VERSION ""

NS_ :

BS_:

BU_: L_DHRR_FD L_UWB_BLE_MST_FD L_UWB_RR_FD L_UWB_BLE_SLV_FD L_UWB_FR_FD L_ROA_FR_FD L_ROA_FD L_DHRL_FD L_UWB_TRNK_FD L_UWB_FRNK_FD L_EDT_FD L_UWB_FL_FD GW_BDC_FD L_UWB_RL_FD L_SAL_FD L_WPC_FD L_TPMS_FD L_DHL_FD L_DHR_FD

BO_ 2214592722 L_UWB_FR_FD_03_00ms: 32 L_UWB_FR_FD
 SG_ L_UWB_FR_FD_Crc3Val : 0|16@1+ (1,0) [0|0] "0" Vector__XXX
 SG_ L_UWB_FR_FD_AlvCnt3Val : 16|8@1+ (1,0) [0|0] "0" Vector__XXX
 SG_ UWB_FR_Ranging_Enc_Result2 : 216|40@1+ (1,0) [0|0] ""  GW_BDC_FD,L_UWB_BLE_MST_FD
 SG_ UWB_FR_Ranging_Enc_Result : 24|192@1+ (1,0) [0|0] ""  GW_BDC_FD,L_UWB_BLE_MST_FD

BO_ 2214592714 L_UWB_BLE_MST_FD_22_00ms: 32 L_UWB_BLE_MST_FD
 SG_ L_UWB_BLE_MST_FD_Crc22Val : 0|16@1+ (1,0) [0|0] "0" Vector__XXX
 SG_ L_UWB_BLE_MST_FD_AlvCnt22Val : 16|8@1+ (1,0) [0|0] "0" Vector__XXX
 SG_ MST_DisconnectDKID : 24|8@1+ (1,0) [0|0] ""  L_EDT_FD
 SG_ MST_DisconnectReason : 32|8@1+ (1,0) [0|0] ""  L_EDT_FD
 SG_ MST_BLE_ErrorReturn : 40|8@1+ (1,0) [0|0] ""  L_EDT_FD,L_UWB_BLE_SLV_FD

BO_ 2214592719 L_UWB_FL_FD_Dvp_01_00ms: 32 L_UWB_FL_FD
 SG_ UWB_FL_Dvp_Data : 0|255@1+ (1,0) [0|0] ""  L_EDT_FD

BO_ 2521143553 L_UWB_BLE_SLV_FD_13_00ms: 32 L_UWB_BLE_SLV_FD
 SG_ L_UWB_BLE_SLV_FD_Crc13Val : 0|16@1+ (1,0) [0|0] "" Vector__XXX
 SG_ L_UWB_BLE_SLV_FD_AlvCnt13Val : 16|8@1+ (1,0) [0|0] "" Vector__XXX
 SG_ SLV_SWID_4_IVD_1 : 24|232@1+ (1,0) [0|0] ""  L_UWB_BLE_MST_FD

BO_ 2214592705 L_UWB_FL_FD_02_00ms: 16 L_UWB_FL_FD
 SG_ L_UWB_FL_FD_Crc2Val : 0|16@1+ (1,0) [0|0] "0" Vector__XXX
 SG_ L_UWB_FL_FD_AlvCnt2Val : 16|8@1+ (1,0) [0|0] "0" Vector__XXX
 SG_ UWB_FL_FOB_RSD_Enc_Result : 24|64@1+ (1,0) [0|0] ""  GW_BDC_FD

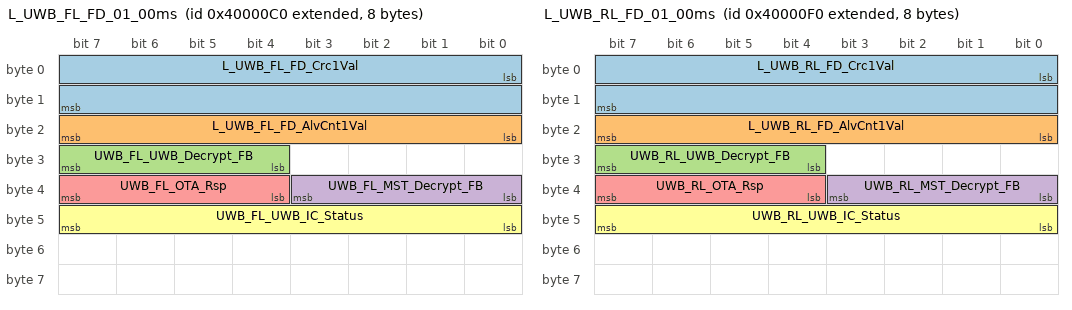
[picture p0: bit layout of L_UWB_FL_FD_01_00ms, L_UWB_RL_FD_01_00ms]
BO_ 2214592704 L_UWB_FL_FD_01_00ms: 8 L_UWB_FL_FD
 SG_ L_UWB_FL_FD_Crc1Val : 0|16@1+ (1,0) [0|0] "0" Vector__XXX
 SG_ L_UWB_FL_FD_AlvCnt1Val : 16|8@1+ (1,0) [0|0] "0" Vector__XXX
 SG_ UWB_FL_UWB_Decrypt_FB : 28|4@1+ (1,0) [0|0] ""  GW_BDC_FD
 SG_ UWB_FL_MST_Decrypt_FB : 32|4@1+ (1,0) [0|0] ""  L_UWB_BLE_MST_FD
 SG_ UWB_FL_OTA_Rsp : 36|4@1+ (1,0) [0|0] ""  L_UWB_BLE_MST_FD
 SG_ UWB_FL_UWB_IC_Status : 40|8@1+ (1,0) [0|0] ""  L_EDT_FD

BO_ 2214592706 L_UWB_FL_FD_03_00ms: 32 L_UWB_FL_FD
 SG_ L_UWB_FL_FD_Crc3Val : 0|16@1+ (1,0) [0|0] "0" Vector__XXX
 SG_ L_UWB_FL_FD_AlvCnt3Val : 16|8@1+ (1,0) [0|0] "0" Vector__XXX
 SG_ UWB_FL_Ranging_Enc_Result2 : 216|40@1+ (1,0) [0|0] ""  GW_BDC_FD,L_UWB_BLE_MST_FD
 SG_ UWB_FL_Ranging_Enc_Result : 24|192@1+ (1,0) [0|0] ""  GW_BDC_FD,L_UWB_BLE_MST_FD

BO_ 2525339649 L_UWB_FL_FD_04_00ms: 32 L_UWB_FL_FD
 SG_ L_UWB_FL_FD_Crc4Val : 0|16@1+ (1,0) [0|0] "" Vector__XXX
 SG_ L_UWB_FL_FD_AlvCnt4Val : 16|8@1+ (1,0) [0|0] "" Vector__XXX
 SG_ FL_SWID_3_IVD_1 : 24|232@1+ (1,0) [0|0] ""  L_UWB_BLE_MST_FD

BO_ 2214592767 L_UWB_RL_FD_Dvp_01_00ms: 32 L_UWB_RL_FD
 SG_ UWB_RL_Dvp_Data : 0|255@1+ (1,0) [0|0] ""  L_EDT_FD

BO_ 2214592754 L_UWB_RL_FD_03_00ms: 32 L_UWB_RL_FD
 SG_ L_UWB_RL_FD_Crc3Val : 0|16@1+ (1,0) [0|0] "0" Vector__XXX
 SG_ L_UWB_RL_FD_AlvCnt3Val : 16|8@1+ (1,0) [0|0] "0" Vector__XXX
 SG_ UWB_RL_Ranging_Enc_Result2 : 216|40@1+ (1,0) [0|0] ""  GW_BDC_FD,L_UWB_BLE_MST_FD
 SG_ UWB_RL_Ranging_Enc_Result : 24|192@1+ (1,0) [0|0] ""  GW_BDC_FD,L_UWB_BLE_MST_FD

BO_ 2214592752 L_UWB_RL_FD_01_00ms: 8 L_UWB_RL_FD
 SG_ L_UWB_RL_FD_Crc1Val : 0|16@1+ (1,0) [0|0] "0" Vector__XXX
 SG_ L_UWB_RL_FD_AlvCnt1Val : 16|8@1+ (1,0) [0|0] "0" Vector__XXX
 SG_ UWB_RL_UWB_Decrypt_FB : 28|4@1+ (1,0) [0|0] ""  GW_BDC_FD
 SG_ UWB_RL_MST_Decrypt_FB : 32|4@1+ (1,0) [0|0] ""  L_UWB_BLE_MST_FD
 SG_ UWB_RL_OTA_Rsp : 36|4@1+ (1,0) [0|0] ""  L_UWB_BLE_MST_FD
 SG_ UWB_RL_UWB_IC_Status : 40|8@1+ (1,0) [0|0] ""  L_EDT_FD

BO_ 2214592753 L_UWB_RL_FD_02_00ms: 16 L_UWB_RL_FD
 SG_ L_UWB_RL_FD_Crc2Val : 0|16@1+ (1,0) [0|0] "0" Vector__XXX
 SG_ L_UWB_RL_FD_AlvCnt2Val : 16|8@1+ (1,0) [0|0] "0" Vector__XXX
 SG_ UWB_RL_FOB_RSD_Enc_Result : 24|64@1+ (1,0) [0|0] ""  GW_BDC_FD

BO_ 187 BDC_FD_01_00ms: 32 GW_BDC_FD
 SG_ BDC_FD_Crc1Val : 0|16@1+ (1,0) [0|0] "" Vector__XXX
 SG_ Ast_AutoRlxWrngDis_Copy_0 : 101|3@1+ (1,0) [0|0] "" Vector__XXX
 SG_ RLPSU_FailState_PopUp_Copy_0 : 104|4@1+ (1,0) [0|0] "" Vector__XXX
 SG_ RRPSU_FailState_PopUp_Copy_0 : 108|4@1+ (1,0) [0|0] "" Vector__XXX
 SG_ Pseat_AllSeatIMSMemoryDelReq : 112|2@1+ (1,0) [0|0] "" Vector__XXX
 SG_ PSeat_RLVIPRelaxionMemoryDelReq : 114|3@1+ (1,0) [0|0] "" Vector__XXX
 SG_ PSeat_RRVIPRelaxionMemoryDelReq : 117|3@1+ (1,0) [0|0] "" Vector__XXX
 SG_ Lamp_FrunkLampCmd : 120|2@1+ (1,0) [0|0] "" Vector__XXX
 SG_ Lamp_DrvCourtesyLampCmd : 122|2@1+ (1,0) [0|0] "" Vector__XXX
 SG_ Lamp_AstCourtesyLampCmd : 124|2@1+ (1,0) [0|0] "" Vector__XXX
 SG_ Lamp_RLCourtesyLampCmd : 126|2@1+ (1,0) [0|0] "" Vector__XXX
 SG_ Lamp_RRCourtesyLampCmd : 128|2@1+ (1,0) [0|0] "" Vector__XXX
 SG_ Lamp_RoomLampCmd : 130|3@1+ (1,0) [0|0] "" Vector__XXX
 SG_ Lamp_FootLampCmd : 133|4@1+ (1,0) [0|0] ""  L_SAL_FD
 SG_ PFSU_3LAMPBzrReq_Copy_0 : 137|2@1+ (1,0) [0|0] "" Vector__XXX
 SG_ PFSU_3RAMPBzrReq_Copy_0 : 139|2@1+ (1,0) [0|0] "" Vector__XXX
 SG_ Drv_AutoRlxWrngDis_2_Copy_0 : 141|3@1+ (1,0) [0|0] "" Vector__XXX
 SG_ Ast_AutoRlxWrngDis_2_Copy_0 : 144|3@1+ (1,0) [0|0] "" Vector__XXX
 SG_ RLPSU_Folding_State_Popup_EC_Cop : 147|3@1+ (1,0) [0|0] "" Vector__XXX
 SG_ RRPSU_Folding_State_Popup_EC_Cop : 150|3@1+ (1,0) [0|0] "" Vector__XXX
 SG_ C_LH_Folding_State_PopUp_Copy_0 : 153|3@1+ (1,0) [0|0] "" Vector__XXX
 SG_ C_RH_Folding_State_PopUp_Copy_0 : 156|3@1+ (1,0) [0|0] "" Vector__XXX
 SG_ C_RH_Folding_State_PopUp_2_Copy_ : 159|3@1+ (1,0) [0|0] "" Vector__XXX
 SG_ BDC_FD_AlvCnt1Val : 16|8@1+ (1,0) [0|0] "" Vector__XXX
 SG_ C_LH_Folding_State_PopUp_2_Copy_ : 162|3@1+ (1,0) [0|0] "" Vector__XXX
 SG_ Swivel_UtilModeSetReq : 165|2@1+ (1,0) [0|0] "" Vector__XXX
 SG_ PSeat_SecondRLTiltWalkInDisReq : 167|2@1+ (1,0) [0|0] "" Vector__XXX
 SG_ PSeat_SecondRRTiltWalkInDisReq : 169|2@1+ (1,0) [0|0] "" Vector__XXX
 SG_ PSeat_DrvLegrestOSDDisReq : 171|3@1+ (1,0) [0|0] "" Vector__XXX
 SG_ PHEV_FuelDrWakeupSta_Copy_0 : 174|2@1+ (1,0) [0|0] "" Vector__XXX
 SG_ MoodLamp_MLSingleBrghtModCmd : 184|3@1+ (1,0) [0|0] "" Vector__XXX
 SG_ MoodLamp_SingleBrghtVal : 187|4@1+ (1,0) [0|0] "" Vector__XXX
 SG_ PSeat_AstReturnMemoryCmd : 192|2@1+ (1,0) [0|0] "" Vector__XXX
 SG_ Swivel_AVNPlayConfirmReq : 194|2@1+ (1,0) [0|0] "" Vector__XXX
 SG_ Swivel_AVNDrvPopUpDisReq : 196|4@1+ (1,0) [0|0] "" Vector__XXX
 SG_ Swivel_AVNAstPopUpDisReq : 200|4@1+ (1,0) [0|0] "" Vector__XXX
 SG_ Swivel_AVNDrvOSDDisReq : 204|4@1+ (1,0) [0|0] "" Vector__XXX
 SG_ Swivel_AVNAstOSDDisReq : 208|4@1+ (1,0) [0|0] "" Vector__XXX
 SG_ Swivel_CTSPlayConfirmReq : 212|2@1+ (1,0) [0|0] "" Vector__XXX
 SG_ Swivel_CTSDrvPopUpDisReq : 214|4@1+ (1,0) [0|0] "" Vector__XXX
 SG_ Swivel_CTSAstPopUpDisReq : 218|4@1+ (1,0) [0|0] "" Vector__XXX
 SG_ Swivel_CTSDrvOSDDisReq : 222|4@1+ (1,0) [0|0] "" Vector__XXX
 SG_ Swivel_CTSAstOSDDisReq : 226|4@1+ (1,0) [0|0] "" Vector__XXX
 SG_ PSeat_AllFoldUnfoldOSDDisReq : 230|4@1+ (1,0) [0|0] "" Vector__XXX
 SG_ DrvIMS_MemorySetEnaSta_Copy_0 : 234|2@1+ (1,0) [0|0] "" Vector__XXX
 SG_ C_LH_Folding_State_PopUp_CTS : 236|3@1+ (1,0) [0|0] "" Vector__XXX
 SG_ C_LH_Folding_State_PopUp_2_CTS : 239|3@1+ (1,0) [0|0] "" Vector__XXX
 SG_ PHEV_FuelDrReleaseSwSta_Copy_0 : 24|2@1+ (1,0) [0|0] "" Vector__XXX
 SG_ C_RH_Folding_State_PopUp_CTS : 242|3@1+ (1,0) [0|0] "" Vector__XXX
 SG_ C_RH_Folding_State_PopUp_2_CTS : 245|3@1+ (1,0) [0|0] "" Vector__XXX
 SG_ PSeat_AllFoldUnfoldOSDDisReq_CTS : 248|4@1+ (1,0) [0|0] "" Vector__XXX
 SG_ StrWhlWrmr_MKBDBpReq_Copy_0 : 26|2@1+ (1,0) [0|0] "" Vector__XXX
 SG_ BckGls_RrGlsHtdMKBDBpReq_Copy_0 : 28|2@1+ (1,0) [0|0] "" Vector__XXX
 SG_ Wndshld_FrtGlsHtdMKBDBpReq_Copy_ : 30|2@1+ (1,0) [0|0] "" Vector__XXX
 SG_ BAlarm_AutoLockrReq_Copy_0 : 32|2@1+ (1,0) [0|0] "" Vector__XXX
 SG_ RLPSU_FailState_PopUp_CTS : 34|4@1+ (1,0) [0|0] "" Vector__XXX
 SG_ RLPSU_Folding_State_Popup_CTS : 38|3@1+ (1,0) [0|0] "" Vector__XXX
 SG_ RRPSU_FailState_PopUp_CTS : 41|4@1+ (1,0) [0|0] "" Vector__XXX
 SG_ RRPSU_Folding_State_Popup_CTS : 45|3@1+ (1,0) [0|0] "" Vector__XXX
 SG_ DrvIMS_AMPBzrReq_Copy_0 : 50|2@1+ (1,0) [0|0] "" Vector__XXX
 SG_ AstIMS_AMPBzrReq_Copy_0 : 52|2@1+ (1,0) [0|0] "" Vector__XXX
 SG_ RLIMS_AMPBzrReq_Copy_0 : 54|2@1+ (1,0) [0|0] "" Vector__XXX
 SG_ RRIMS_AMPBzrReq_Copy_0 : 56|2@1+ (1,0) [0|0] "" Vector__XXX
 SG_ DrvIMS_BzrReq_Copy_0 : 58|2@1+ (1,0) [0|0] "" Vector__XXX
 SG_ DrvIMS_ErrConWmgDis_Copy_0 : 60|2@1+ (1,0) [0|0] "" Vector__XXX
 SG_ DrvIMS_MemoryP1Req_Copy_0 : 62|2@1+ (1,0) [0|0] "" Vector__XXX
 SG_ DrvIMS_MemoryP2Req_Copy_0 : 64|2@1+ (1,0) [0|0] "" Vector__XXX
 SG_ DrvIMS_MemoryP3Req_Copy_0 : 66|2@1+ (1,0) [0|0] "" Vector__XXX
 SG_ DrvIMS_PlyBckP1Req_Copy_0 : 68|2@1+ (1,0) [0|0] "" Vector__XXX
 SG_ DrvIMS_PlyBckP2Req_Copy_0 : 70|2@1+ (1,0) [0|0] "" Vector__XXX
 SG_ DrvIMS_PlyBckP3Req_Copy_0 : 72|2@1+ (1,0) [0|0] "" Vector__XXX
 SG_ DrvIMS_PlyBckStpReq_Copy_0 : 74|2@1+ (1,0) [0|0] "" Vector__XXX
 SG_ AVN_SeatPosMemory_Cmd_Copy_0 : 76|3@1+ (1,0) [0|0] "" Vector__XXX
 SG_ AVN_SeatPosPlyBck_Cmd_Copy_0 : 79|3@1+ (1,0) [0|0] "" Vector__XXX
 SG_ SmrtIMS_EnterSwSta_Copy_0 : 82|2@1+ (1,0) [0|0] "" Vector__XXX
 SG_ SmrtIMS_PlyBckReq_Copy_0 : 84|12@1+ (1,0) [0|0] "" Vector__XXX
 SG_ SmrtIMS_PlyBckStpReq_Copy_0 : 96|2@1+ (1,0) [0|0] "" Vector__XXX
 SG_ Drv_AutoRlxWrngDis_Copy_0 : 98|3@1+ (1,0) [0|0] "" Vector__XXX

BO_ 2214592751 L_UWB_FRNK_FD_Dvp_01_00ms: 32 L_UWB_FRNK_FD
 SG_ UWB_FRNK_Dvp_Data : 0|255@1+ (1,0) [0|0] ""  L_EDT_FD

BO_ 2214592738 L_UWB_FRNK_FD_03_00ms: 32 L_UWB_FRNK_FD
 SG_ L_UWB_FRNK_FD_Crc3Val : 0|16@1+ (1,0) [0|0] "0" Vector__XXX
 SG_ L_UWB_FRNK_FD_AlvCnt3Val : 16|8@1+ (1,0) [0|0] "0" Vector__XXX
 SG_ UWB_FRNK_Ranging_Enc_Result2 : 216|40@1+ (1,0) [0|0] ""  GW_BDC_FD,L_UWB_BLE_MST_FD
 SG_ UWB_FRNK_Ranging_Enc_Result : 24|192@1+ (1,0) [0|0] ""  GW_BDC_FD,L_UWB_BLE_MST_FD

BO_ 2214592737 L_UWB_FRNK_FD_02_00ms: 16 L_UWB_FRNK_FD
 SG_ L_UWB_FRNK_FD_Crc2Val : 0|16@1+ (1,0) [0|0] "0" Vector__XXX
 SG_ L_UWB_FRNK_FD_AlvCnt2Val : 16|8@1+ (1,0) [0|0] "0" Vector__XXX
 SG_ UWB_FRNK_FOB_RSD_Enc_Result : 24|64@1+ (1,0) [0|0] ""  GW_BDC_FD

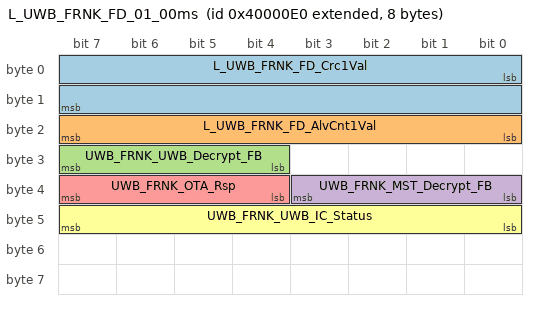
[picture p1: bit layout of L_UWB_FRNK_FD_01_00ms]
BO_ 2214592736 L_UWB_FRNK_FD_01_00ms: 8 L_UWB_FRNK_FD
 SG_ L_UWB_FRNK_FD_Crc1Val : 0|16@1+ (1,0) [0|0] "0" Vector__XXX
 SG_ L_UWB_FRNK_FD_AlvCnt1Val : 16|8@1+ (1,0) [0|0] "0" Vector__XXX
 SG_ UWB_FRNK_UWB_Decrypt_FB : 28|4@1+ (1,0) [0|0] ""  GW_BDC_FD
 SG_ UWB_FRNK_MST_Decrypt_FB : 32|4@1+ (1,0) [0|0] ""  L_UWB_BLE_MST_FD
 SG_ UWB_FRNK_OTA_Rsp : 36|4@1+ (1,0) [0|0] ""  L_UWB_BLE_MST_FD
 SG_ UWB_FRNK_UWB_IC_Status : 40|8@1+ (1,0) [0|0] ""  L_EDT_FD

BO_ 2348810509 TP_L_DHRR_FD_BDC_FD: 32 L_DHRR_FD
 SG_ TP_L_DHRR_FD_BDC_FD_Byte0 : 0|8@1+ (1,0) [0|0] ""  GW_BDC_FD
 SG_ TP_L_DHRR_FD_BDC_FD_Byte13 : 104|8@1+ (1,0) [0|0] ""  GW_BDC_FD
 SG_ TP_L_DHRR_FD_BDC_FD_Byte14 : 112|8@1+ (1,0) [0|0] ""  GW_BDC_FD
 SG_ TP_L_DHRR_FD_BDC_FD_Byte15 : 120|8@1+ (1,0) [0|0] ""  GW_BDC_FD
 SG_ TP_L_DHRR_FD_BDC_FD_Byte16 : 128|8@1+ (1,0) [0|0] ""  GW_BDC_FD
 SG_ TP_L_DHRR_FD_BDC_FD_Byte17 : 136|8@1+ (1,0) [0|0] ""  GW_BDC_FD
 SG_ TP_L_DHRR_FD_BDC_FD_Byte18 : 144|8@1+ (1,0) [0|0] ""  GW_BDC_FD
 SG_ TP_L_DHRR_FD_BDC_FD_Byte19 : 152|8@1+ (1,0) [0|0] ""  GW_BDC_FD
 SG_ TP_L_DHRR_FD_BDC_FD_Byte2 : 16|8@1+ (1,0) [0|0] ""  GW_BDC_FD
 SG_ TP_L_DHRR_FD_BDC_FD_Byte20 : 160|8@1+ (1,0) [0|0] ""  GW_BDC_FD
 SG_ TP_L_DHRR_FD_BDC_FD_Byte21 : 168|8@1+ (1,0) [0|0] ""  GW_BDC_FD
 SG_ TP_L_DHRR_FD_BDC_FD_Byte22 : 176|8@1+ (1,0) [0|0] ""  GW_BDC_FD
 SG_ TP_L_DHRR_FD_BDC_FD_Byte23 : 184|8@1+ (1,0) [0|0] ""  GW_BDC_FD
 SG_ TP_L_DHRR_FD_BDC_FD_Byte24 : 192|8@1+ (1,0) [0|0] ""  GW_BDC_FD
 SG_ TP_L_DHRR_FD_BDC_FD_Byte25 : 200|8@1+ (1,0) [0|0] ""  GW_BDC_FD
 SG_ TP_L_DHRR_FD_BDC_FD_Byte26 : 208|8@1+ (1,0) [0|0] ""  GW_BDC_FD
 SG_ TP_L_DHRR_FD_BDC_FD_Byte27 : 216|8@1+ (1,0) [0|0] ""  GW_BDC_FD
 SG_ TP_L_DHRR_FD_BDC_FD_Byte28 : 224|8@1+ (1,0) [0|0] ""  GW_BDC_FD
 SG_ TP_L_DHRR_FD_BDC_FD_Byte29 : 232|8@1+ (1,0) [0|0] ""  GW_BDC_FD
 SG_ TP_L_DHRR_FD_BDC_FD_Byte3 : 24|8@1+ (1,0) [0|0] ""  GW_BDC_FD
 SG_ TP_L_DHRR_FD_BDC_FD_Byte30 : 240|8@1+ (1,0) [0|0] ""  GW_BDC_FD
 SG_ TP_L_DHRR_FD_BDC_FD_Byte31 : 248|8@1+ (1,0) [0|0] ""  GW_BDC_FD
 SG_ TP_L_DHRR_FD_BDC_FD_Byte4 : 32|8@1+ (1,0) [0|0] ""  GW_BDC_FD
 SG_ TP_L_DHRR_FD_BDC_FD_Byte5 : 40|8@1+ (1,0) [0|0] ""  GW_BDC_FD
 SG_ TP_L_DHRR_FD_BDC_FD_Byte6 : 48|8@1+ (1,0) [0|0] ""  GW_BDC_FD
 SG_ TP_L_DHRR_FD_BDC_FD_Byte7 : 56|8@1+ (1,0) [0|0] ""  GW_BDC_FD
 SG_ TP_L_DHRR_FD_BDC_FD_Byte8 : 64|8@1+ (1,0) [0|0] ""  GW_BDC_FD
 SG_ TP_L_DHRR_FD_BDC_FD_Byte9 : 72|8@1+ (1,0) [0|0] ""  GW_BDC_FD
 SG_ TP_L_DHRR_FD_BDC_FD_Byte1 : 8|8@1+ (1,0) [0|0] ""  GW_BDC_FD
 SG_ TP_L_DHRR_FD_BDC_FD_Byte10 : 80|8@1+ (1,0) [0|0] ""  GW_BDC_FD
 SG_ TP_L_DHRR_FD_BDC_FD_Byte11 : 88|8@1+ (1,0) [0|0] ""  GW_BDC_FD
 SG_ TP_L_DHRR_FD_BDC_FD_Byte12 : 96|8@1+ (1,0) [0|0] ""  GW_BDC_FD

BO_ 745 PDC_FD_15_300ms: 32 GW_BDC_FD
 SG_ PDC_FD_Crc15Val : 0|16@1+ (1,0) [0|0] ""  L_DHL_FD,L_DHRL_FD,L_DHRR_FD,L_DHR_FD,L_EDT_FD,L_ROA_FD,L_ROA_FR_FD,L_SAL_FD,L_TPMS_FD,L_UWB_BLE_MST_FD,L_UWB_BLE_SLV_FD,L_UWB_FL_FD,L_UWB_FRNK_FD,L_UWB_FR_FD,L_UWB_RL_FD,L_UWB_RR_FD,L_UWB_TRNK_FD,L_WPC_FD
 SG_ PDC_CurrAtReset_Copy_0 : 104|12@1+ (10,-40940) [-40940|0] "mA" Vector__XXX
 SG_ PDC_AvgCurrAtReset_Copy_0 : 120|12@1+ (10,-40940) [-40940|0] "mA" Vector__XXX
 SG_ PDC_ResetReason_Copy_0 : 132|3@1+ (1,0) [0|0] "" Vector__XXX
 SG_ PDC_CumulativeCountOf12VReq_Copy : 136|10@1+ (1,0) [0|0] "" Vector__XXX
 SG_ PDC_CumulativeCountOfCCUReq_Copy : 146|10@1+ (1,0) [0|0] "" Vector__XXX
 SG_ PDC_FD_AlvCnt15Val : 16|8@1+ (1,0) [0|0] ""  L_DHL_FD,L_DHRL_FD,L_DHRR_FD,L_DHR_FD,L_EDT_FD,L_ROA_FD,L_ROA_FR_FD,L_SAL_FD,L_TPMS_FD,L_UWB_BLE_MST_FD,L_UWB_BLE_SLV_FD,L_UWB_FL_FD,L_UWB_FRNK_FD,L_UWB_FR_FD,L_UWB_RL_FD,L_UWB_RR_FD,L_UWB_TRNK_FD,L_WPC_FD
 SG_ PDC_LDConReq_Copy_0 : 184|2@1+ (1,0) [0|0] "" Vector__XXX
 SG_ PDC_LDConReq_By_LVBat_Copy_0 : 186|2@1+ (1,0) [0|0] "" Vector__XXX
 SG_ PDC_LDConReq_By_OTA_Copy_0 : 188|2@1+ (1,0) [0|0] "" Vector__XXX
 SG_ PDC_LDConReq_By_Load_Copy_0 : 190|2@1+ (1,0) [0|0] "" Vector__XXX
 SG_ PDC_LDConReq_By_ActiveOn_Copy_0 : 192|2@1+ (1,0) [0|0] "" Vector__XXX
 SG_ PDC_ResetPreWrngForCCU_Copy_0 : 40|2@1+ (1,0) [0|0] "" Vector__XXX
 SG_ PDC_ResetPreWrngForOthers_Copy_0 : 42|2@1+ (1,0) [0|0] ""  L_DHL_FD,L_DHRL_FD,L_DHRR_FD,L_DHR_FD,L_EDT_FD,L_ROA_FD,L_ROA_FR_FD,L_SAL_FD,L_TPMS_FD,L_UWB_BLE_MST_FD,L_UWB_BLE_SLV_FD,L_UWB_FL_FD,L_UWB_FRNK_FD,L_UWB_FR_FD,L_UWB_RL_FD,L_UWB_RR_FD,L_UWB_TRNK_FD,L_WPC_FD
 SG_ PDC_ResetReqForCCU_Copy_0 : 44|2@1+ (1,0) [0|0] "" Vector__XXX
 SG_ PDC_ResetReqForOthers_Copy_0 : 46|2@1+ (1,0) [0|0] ""  L_DHL_FD,L_DHRL_FD,L_DHRR_FD,L_DHR_FD,L_EDT_FD,L_ROA_FD,L_ROA_FR_FD,L_SAL_FD,L_TPMS_FD,L_UWB_BLE_MST_FD,L_UWB_BLE_SLV_FD,L_UWB_FL_FD,L_UWB_FRNK_FD,L_UWB_FR_FD,L_UWB_RL_FD,L_UWB_RR_FD,L_UWB_TRNK_FD,L_WPC_FD
 SG_ PDC_ResetFuncOpt_Copy_0 : 48|2@1+ (1,0) [0|0] ""  L_ROA_FD,L_ROA_FR_FD,L_TPMS_FD,L_UWB_BLE_MST_FD,L_UWB_BLE_SLV_FD,L_UWB_FL_FD,L_UWB_FRNK_FD,L_UWB_FR_FD,L_UWB_RL_FD,L_UWB_RR_FD,L_UWB_TRNK_FD
 SG_ PDC_12VRlyCtrl_Copy_0 : 50|2@1+ (1,0) [0|0] "" Vector__XXX
 SG_ PDC_CurrentValueForReset_Copy_0 : 52|8@1+ (50,0) [0|0] "mA" Vector__XXX
 SG_ PDC_TimeValueForReset_Copy_0 : 64|8@1+ (0.5,0) [0|0] "h" Vector__XXX
 SG_ PDC_12VRlyOffHoldingTime_Copy_0 : 72|5@1+ (0.5,0) [0|0] "s" Vector__XXX
 SG_ PDC_ResetCountSetting_Copy_0 : 77|2@1+ (1,0) [0|0] "" Vector__XXX
 SG_ PDC_ResetCount_Copy_0 : 79|2@1+ (1,0) [0|0] "" Vector__XXX
 SG_ PDC_ResetCumulativeCount_Copy_0 : 81|10@1+ (1,0) [0|0] "" Vector__XXX
 SG_ PDC_ResetOpsta_Copy_0 : 91|2@1+ (1,0) [0|0] "" Vector__XXX
 SG_ PDC_ReadyTimeValueForReset_Copy_ : 96|8@1+ (10,0) [0|255] "Min" Vector__XXX

BO_ 2348810508 TP_BDC_FD_L_DHRR_FD: 32 GW_BDC_FD
 SG_ TP_BDC_FD_L_DHRR_FD_Byte0 : 0|8@1+ (1,0) [0|0] ""  L_DHRR_FD
 SG_ TP_BDC_FD_L_DHRR_FD_Byte13 : 104|8@1+ (1,0) [0|0] ""  L_DHRR_FD
 SG_ TP_BDC_FD_L_DHRR_FD_Byte14 : 112|8@1+ (1,0) [0|0] ""  L_DHRR_FD
 SG_ TP_BDC_FD_L_DHRR_FD_Byte15 : 120|8@1+ (1,0) [0|0] ""  L_DHRR_FD
 SG_ TP_BDC_FD_L_DHRR_FD_Byte16 : 128|8@1+ (1,0) [0|0] ""  L_DHRR_FD
 SG_ TP_BDC_FD_L_DHRR_FD_Byte17 : 136|8@1+ (1,0) [0|0] ""  L_DHRR_FD
 SG_ TP_BDC_FD_L_DHRR_FD_Byte18 : 144|8@1+ (1,0) [0|0] ""  L_DHRR_FD
 SG_ TP_BDC_FD_L_DHRR_FD_Byte19 : 152|8@1+ (1,0) [0|0] ""  L_DHRR_FD
 SG_ TP_BDC_FD_L_DHRR_FD_Byte2 : 16|8@1+ (1,0) [0|0] ""  L_DHRR_FD
 SG_ TP_BDC_FD_L_DHRR_FD_Byte20 : 160|8@1+ (1,0) [0|0] ""  L_DHRR_FD
 SG_ TP_BDC_FD_L_DHRR_FD_Byte21 : 168|8@1+ (1,0) [0|0] ""  L_DHRR_FD
 SG_ TP_BDC_FD_L_DHRR_FD_Byte22 : 176|8@1+ (1,0) [0|0] ""  L_DHRR_FD
 SG_ TP_BDC_FD_L_DHRR_FD_Byte23 : 184|8@1+ (1,0) [0|0] ""  L_DHRR_FD
 SG_ TP_BDC_FD_L_DHRR_FD_Byte24 : 192|8@1+ (1,0) [0|0] ""  L_DHRR_FD
 SG_ TP_BDC_FD_L_DHRR_FD_Byte25 : 200|8@1+ (1,0) [0|0] ""  L_DHRR_FD
 SG_ TP_BDC_FD_L_DHRR_FD_Byte26 : 208|8@1+ (1,0) [0|0] ""  L_DHRR_FD
 SG_ TP_BDC_FD_L_DHRR_FD_Byte27 : 216|8@1+ (1,0) [0|0] ""  L_DHRR_FD
 SG_ TP_BDC_FD_L_DHRR_FD_Byte28 : 224|8@1+ (1,0) [0|0] ""  L_DHRR_FD
 SG_ TP_BDC_FD_L_DHRR_FD_Byte29 : 232|8@1+ (1,0) [0|0] ""  L_DHRR_FD
 SG_ TP_BDC_FD_L_DHRR_FD_Byte3 : 24|8@1+ (1,0) [0|0] ""  L_DHRR_FD
 SG_ TP_BDC_FD_L_DHRR_FD_Byte30 : 240|8@1+ (1,0) [0|0] ""  L_DHRR_FD
 SG_ TP_BDC_FD_L_DHRR_FD_Byte31 : 248|8@1+ (1,0) [0|0] ""  L_DHRR_FD
 SG_ TP_BDC_FD_L_DHRR_FD_Byte4 : 32|8@1+ (1,0) [0|0] ""  L_DHRR_FD
 SG_ TP_BDC_FD_L_DHRR_FD_Byte5 : 40|8@1+ (1,0) [0|0] ""  L_DHRR_FD
 SG_ TP_BDC_FD_L_DHRR_FD_Byte6 : 48|8@1+ (1,0) [0|0] ""  L_DHRR_FD
 SG_ TP_BDC_FD_L_DHRR_FD_Byte7 : 56|8@1+ (1,0) [0|0] ""  L_DHRR_FD
 SG_ TP_BDC_FD_L_DHRR_FD_Byte8 : 64|8@1+ (1,0) [0|0] ""  L_DHRR_FD
 SG_ TP_BDC_FD_L_DHRR_FD_Byte9 : 72|8@1+ (1,0) [0|0] ""  L_DHRR_FD
 SG_ TP_BDC_FD_L_DHRR_FD_Byte1 : 8|8@1+ (1,0) [0|0] ""  L_DHRR_FD
 SG_ TP_BDC_FD_L_DHRR_FD_Byte10 : 80|8@1+ (1,0) [0|0] ""  L_DHRR_FD
 SG_ TP_BDC_FD_L_DHRR_FD_Byte11 : 88|8@1+ (1,0) [0|0] ""  L_DHRR_FD
 SG_ TP_BDC_FD_L_DHRR_FD_Byte12 : 96|8@1+ (1,0) [0|0] ""  L_DHRR_FD

BO_ 2348810507 TP_L_DHRL_FD_BDC_FD: 32 L_DHRL_FD
 SG_ TP_L_DHRL_FD_BDC_FD_Byte0 : 0|8@1+ (1,0) [0|0] ""  GW_BDC_FD
 SG_ TP_L_DHRL_FD_BDC_FD_Byte13 : 104|8@1+ (1,0) [0|0] ""  GW_BDC_FD
 SG_ TP_L_DHRL_FD_BDC_FD_Byte14 : 112|8@1+ (1,0) [0|0] ""  GW_BDC_FD
 SG_ TP_L_DHRL_FD_BDC_FD_Byte15 : 120|8@1+ (1,0) [0|0] ""  GW_BDC_FD
 SG_ TP_L_DHRL_FD_BDC_FD_Byte16 : 128|8@1+ (1,0) [0|0] ""  GW_BDC_FD
 SG_ TP_L_DHRL_FD_BDC_FD_Byte17 : 136|8@1+ (1,0) [0|0] ""  GW_BDC_FD
 SG_ TP_L_DHRL_FD_BDC_FD_Byte18 : 144|8@1+ (1,0) [0|0] ""  GW_BDC_FD
 SG_ TP_L_DHRL_FD_BDC_FD_Byte19 : 152|8@1+ (1,0) [0|0] ""  GW_BDC_FD
 SG_ TP_L_DHRL_FD_BDC_FD_Byte2 : 16|8@1+ (1,0) [0|0] ""  GW_BDC_FD
 SG_ TP_L_DHRL_FD_BDC_FD_Byte20 : 160|8@1+ (1,0) [0|0] ""  GW_BDC_FD
 SG_ TP_L_DHRL_FD_BDC_FD_Byte21 : 168|8@1+ (1,0) [0|0] ""  GW_BDC_FD
 SG_ TP_L_DHRL_FD_BDC_FD_Byte22 : 176|8@1+ (1,0) [0|0] ""  GW_BDC_FD
 SG_ TP_L_DHRL_FD_BDC_FD_Byte23 : 184|8@1+ (1,0) [0|0] ""  GW_BDC_FD
 SG_ TP_L_DHRL_FD_BDC_FD_Byte24 : 192|8@1+ (1,0) [0|0] ""  GW_BDC_FD
 SG_ TP_L_DHRL_FD_BDC_FD_Byte25 : 200|8@1+ (1,0) [0|0] ""  GW_BDC_FD
 SG_ TP_L_DHRL_FD_BDC_FD_Byte26 : 208|8@1+ (1,0) [0|0] ""  GW_BDC_FD
 SG_ TP_L_DHRL_FD_BDC_FD_Byte27 : 216|8@1+ (1,0) [0|0] ""  GW_BDC_FD
 SG_ TP_L_DHRL_FD_BDC_FD_Byte28 : 224|8@1+ (1,0) [0|0] ""  GW_BDC_FD
 SG_ TP_L_DHRL_FD_BDC_FD_Byte29 : 232|8@1+ (1,0) [0|0] ""  GW_BDC_FD
 SG_ TP_L_DHRL_FD_BDC_FD_Byte3 : 24|8@1+ (1,0) [0|0] ""  GW_BDC_FD
 SG_ TP_L_DHRL_FD_BDC_FD_Byte30 : 240|8@1+ (1,0) [0|0] ""  GW_BDC_FD
 SG_ TP_L_DHRL_FD_BDC_FD_Byte31 : 248|8@1+ (1,0) [0|0] ""  GW_BDC_FD
 SG_ TP_L_DHRL_FD_BDC_FD_Byte4 : 32|8@1+ (1,0) [0|0] ""  GW_BDC_FD
 SG_ TP_L_DHRL_FD_BDC_FD_Byte5 : 40|8@1+ (1,0) [0|0] ""  GW_BDC_FD
 SG_ TP_L_DHRL_FD_BDC_FD_Byte6 : 48|8@1+ (1,0) [0|0] ""  GW_BDC_FD
 SG_ TP_L_DHRL_FD_BDC_FD_Byte7 : 56|8@1+ (1,0) [0|0] ""  GW_BDC_FD
 SG_ TP_L_DHRL_FD_BDC_FD_Byte8 : 64|8@1+ (1,0) [0|0] ""  GW_BDC_FD
 SG_ TP_L_DHRL_FD_BDC_FD_Byte9 : 72|8@1+ (1,0) [0|0] ""  GW_BDC_FD
 SG_ TP_L_DHRL_FD_BDC_FD_Byte1 : 8|8@1+ (1,0) [0|0] ""  GW_BDC_FD
 SG_ TP_L_DHRL_FD_BDC_FD_Byte10 : 80|8@1+ (1,0) [0|0] ""  GW_BDC_FD
 SG_ TP_L_DHRL_FD_BDC_FD_Byte11 : 88|8@1+ (1,0) [0|0] ""  GW_BDC_FD
 SG_ TP_L_DHRL_FD_BDC_FD_Byte12 : 96|8@1+ (1,0) [0|0] ""  GW_BDC_FD

CM_ BO_ 2214592722 "[EW] On Event and On Write";
CM_ SG_ 2214592722 L_UWB_FR_FD_Crc3Val "L_UWB_FR_FD_CyclicRedundancyCheck3Value";
CM_ SG_ 2214592722 L_UWB_FR_FD_AlvCnt3Val "L_UWB_FR_FD_AliveCounter3Value";
CM_ SG_ 2214592722 UWB_FR_Ranging_Enc_Result2 "UWB Ranging Result2(Encrypted Data) with DK";
CM_ SG_ 2214592722 UWB_FR_Ranging_Enc_Result "UWB Ranging Result with DK";
CM_ BO_ 2214592714 "[EC] On Event and On Change";
CM_ SG_ 2214592714 L_UWB_BLE_MST_FD_Crc22Val "L_UWB_BLE_MST_FD_CyclicRedundancyCheck22Value";
CM_ SG_ 2214592714 L_UWB_BLE_MST_FD_AlvCnt22Val "L_UWB_BLE_MST_FD_AliveCounter22Value";
CM_ SG_ 2214592714 MST_DisconnectDKID "Disconnected DK ID";
CM_ SG_ 2214592714 MST_DisconnectReason "Disconnected Reason";
CM_ SG_ 2214592714 MST_BLE_ErrorReturn "Master BLE Error Data";
CM_ BO_ 2214592719 "[EW] On Event and On Write";
CM_ SG_ 2214592719 UWB_FL_Dvp_Data "Development Message";
CM_ BO_ 2521143553 "[EW] On Event and On Write";
CM_ SG_ 2521143553 L_UWB_BLE_SLV_FD_Crc13Val "L_UWB_BLE_SLV_FD_CyclicRedundancyCheck13Value";
CM_ SG_ 2521143553 L_UWB_BLE_SLV_FD_AlvCnt13Val "L_UWB_BLE_SLV_FD_AliveCounter13Value";
CM_ SG_ 2521143553 SLV_SWID_4_IVD_1 "Slave SW Unit 4 IVD1";
CM_ BO_ 2214592705 "[EC] On Event and On Change";
CM_ SG_ 2214592705 L_UWB_FL_FD_Crc2Val "L_UWB_FL_FD_CyclicRedundancyCheck2Value";
CM_ SG_ 2214592705 L_UWB_FL_FD_AlvCnt2Val "L_UWB_FL_FD_AliveCounter2Value";
CM_ SG_ 2214592705 UWB_FL_FOB_RSD_Enc_Result "UWB Ranging Result with FOB";
CM_ BO_ 2214592704 "[EC] On Event and On Change";
CM_ SG_ 2214592704 L_UWB_FL_FD_Crc1Val "L_UWB_FL_FD_CyclicRedundancyCheck1Value";
CM_ SG_ 2214592704 L_UWB_FL_FD_AlvCnt1Val "L_UWB_FL_FD_AliveCounter1Value";
CM_ SG_ 2214592704 UWB_FL_UWB_Decrypt_FB "Decryption Feedback for UWB (to BDC)";
CM_ SG_ 2214592704 UWB_FL_MST_Decrypt_FB "UWB FL Decryption FeedBack (to Master)";
CM_ SG_ 2214592704 UWB_FL_OTA_Rsp "UWB FL OTA response";
CM_ SG_ 2214592704 UWB_FL_UWB_IC_Status "UWB IC Status Message";
CM_ BO_ 2214592706 "[EW] On Event and On Write";
CM_ SG_ 2214592706 L_UWB_FL_FD_Crc3Val "L_UWB_FL_FD_CyclicRedundancyCheck3Value";
CM_ SG_ 2214592706 L_UWB_FL_FD_AlvCnt3Val "L_UWB_FL_FD_AliveCounter3Value";
CM_ SG_ 2214592706 UWB_FL_Ranging_Enc_Result2 "UWB Ranging Result2(Encrypted Data) with DK";
CM_ SG_ 2214592706 UWB_FL_Ranging_Enc_Result "UWB Ranging Result with DK";
CM_ BO_ 2525339649 "[EW] On Event and On Write";
CM_ SG_ 2525339649 L_UWB_FL_FD_Crc4Val "L_UWB_FL_FD_CyclicRedundancyCheck4Value";
CM_ SG_ 2525339649 L_UWB_FL_FD_AlvCnt4Val "L_UWB_FL_FD_AliveCounter4Value";
CM_ SG_ 2525339649 FL_SWID_3_IVD_1 "UWB FL SW Unit 3 IVD1";
CM_ BO_ 2214592767 "[EW] On Event and On Write";
CM_ SG_ 2214592767 UWB_RL_Dvp_Data "Development Message";
CM_ BO_ 2214592754 "[EW] On Event and On Write";
CM_ SG_ 2214592754 L_UWB_RL_FD_Crc3Val "L_UWB_RL_FD_CyclicRedundancyCheck3Value";
CM_ SG_ 2214592754 L_UWB_RL_FD_AlvCnt3Val "L_UWB_RL_FD_AliveCounter3Value";
CM_ SG_ 2214592754 UWB_RL_Ranging_Enc_Result2 "UWB Ranging Result2(Encrypted Data) with DK";
CM_ SG_ 2214592754 UWB_RL_Ranging_Enc_Result "UWB Ranging Result with DK";
CM_ BO_ 2214592752 "[EC] On Event and On Change";
CM_ SG_ 2214592752 L_UWB_RL_FD_Crc1Val "L_UWB_RL_FD_CyclicRedundancyCheck1Value";
CM_ SG_ 2214592752 L_UWB_RL_FD_AlvCnt1Val "L_UWB_RL_FD_AliveCounter1Value";
CM_ SG_ 2214592752 UWB_RL_UWB_Decrypt_FB "Decryption Feedback for UWB (to BDC)";
CM_ SG_ 2214592752 UWB_RL_MST_Decrypt_FB "UWB RL Decryption FeedBack (to Master)";
CM_ SG_ 2214592752 UWB_RL_OTA_Rsp "UWB RL OTA response";
CM_ SG_ 2214592752 UWB_RL_UWB_IC_Status "UWB IC Status Message";
CM_ BO_ 2214592753 "[EC] On Event and On Change";
CM_ SG_ 2214592753 L_UWB_RL_FD_Crc2Val "L_UWB_RL_FD_CyclicRedundancyCheck2Value";
CM_ SG_ 2214592753 L_UWB_RL_FD_AlvCnt2Val "L_UWB_RL_FD_AliveCounter2Value";
CM_ SG_ 2214592753 UWB_RL_FOB_RSD_Enc_Result "UWB Ranging Result with FOB";
CM_ BO_ 187 "[EC] On Event and On Change";
CM_ SG_ 187 BDC_FD_Crc1Val "BDC_FD_CyclicRedundancyCheck1Value";
CM_ SG_ 187 Ast_AutoRlxWrngDis_Copy_0 "Assist seat auto relax warning information for AVN Display";
CM_ SG_ 187 RLPSU_FailState_PopUp_Copy_0 "Rear LH Seat Operating Finish or Operating Disable Information for AVN Display";
CM_ SG_ 187 RRPSU_FailState_PopUp_Copy_0 "2nd RH Seat Operating Finish or Operating Disable Information for AVN Display";
CM_ SG_ 187 PFSU_3LAMPBzrReq_Copy_0 "3rd Left SEAT IMS Buzzer Request for AMP or Inner Speaker";
CM_ SG_ 187 PFSU_3RAMPBzrReq_Copy_0 "3rd Right SEAT IMS Buzzer Request for AMP or Inner Speaker";
CM_ SG_ 187 Drv_AutoRlxWrngDis_2_Copy_0 "Drive seat auto relax warning information for AVN display";
CM_ SG_ 187 Ast_AutoRlxWrngDis_2_Copy_0 "Assist seat auto relax warning information for AVN Display";
CM_ SG_ 187 RLPSU_Folding_State_Popup_EC_Cop "Rear LH seat Folding State information";
CM_ SG_ 187 RRPSU_Folding_State_Popup_EC_Cop "Rear RH seat Folding State information";
CM_ SG_ 187 C_LH_Folding_State_PopUp_Copy_0 "3rd LH seat Moving Finish / Mode-Fail signal";
CM_ SG_ 187 C_RH_Folding_State_PopUp_Copy_0 "3rd RH seat Moving Finish / Mode-Fail signal";
CM_ SG_ 187 C_RH_Folding_State_PopUp_2_Copy_ "AVNT OSD PopUp For 3rd Seat Inoperable condition";
CM_ SG_ 187 BDC_FD_AlvCnt1Val "BDC_FD_AliveCounter1Value";
CM_ SG_ 187 C_LH_Folding_State_PopUp_2_Copy_ "AVNT OSD PopUp For 3rd Seat Inoperable condition";
CM_ SG_ 187 Swivel_UtilModeSetReq "Utility Mode Set Request for Swivel Seat";
CM_ SG_ 187 PSeat_SecondRLTiltWalkInDisReq "Second RL Seat TiltUp Walkin Unlocking Display Request";
CM_ SG_ 187 PSeat_SecondRRTiltWalkInDisReq "Second RR Seat TiltUp Walkin Unlocking Display Request";
CM_ SG_ 187 PSeat_DrvLegrestOSDDisReq "Driver Seat Legrest OSD Display Request";
CM_ SG_ 187 Swivel_AVNPlayConfirmReq "AVN Swivel Play User Confirm Request";
CM_ SG_ 187 Swivel_AVNDrvPopUpDisReq "Driver Seat Swivel AVN PopUp Display Request";
CM_ SG_ 187 Swivel_AVNAstPopUpDisReq "Assist Seat Swivel AVN PopUp Display Request";
CM_ SG_ 187 Swivel_AVNDrvOSDDisReq "Driver Seat Swivel AVN OSD Display Request";
CM_ SG_ 187 Swivel_AVNAstOSDDisReq "Assist Seat Swivel AVN OSD Display Request";
CM_ SG_ 187 Swivel_CTSPlayConfirmReq "Swivel_CTSDrvPlayConfirmReq";
CM_ SG_ 187 Swivel_CTSDrvPopUpDisReq "Driver Seat Swivel CTS PopUp Display Request";
CM_ SG_ 187 Swivel_CTSAstPopUpDisReq "Assist Seat Swivel CTS PopUp Display Request";
CM_ SG_ 187 Swivel_CTSDrvOSDDisReq "Driver Seat Swivel CTS OSD Display Request";
CM_ SG_ 187 Swivel_CTSAstOSDDisReq "Swivel_CTSAstOSDDisReq";
CM_ SG_ 187 PSeat_AllFoldUnfoldOSDDisReq "All Fold Unfold OSD Display Request to AVN";
CM_ SG_ 187 DrvIMS_MemorySetEnaSta_Copy_0 "PSM_MemorySetEnableStatus";
CM_ SG_ 187 PHEV_FuelDrReleaseSwSta_Copy_0 "PHEV Fuel Filler Door Release Sw State";
CM_ SG_ 187 BAlarm_AutoLockrReq_Copy_0 "BAlarm_AutoLockRequest ##2G##BCM - BCMmsg01 - C_AutoLockCmd";
CM_ SG_ 187 DrvIMS_AMPBzrReq_Copy_0 "SEAT IMS Buzzer Request for AMP";
CM_ SG_ 187 AstIMS_AMPBzrReq_Copy_0 "SEAT IMS Buzzer Request for AMP";
CM_ SG_ 187 RLIMS_AMPBzrReq_Copy_0 "SEAT IMS Buzzer Request for AMP";
CM_ SG_ 187 RRIMS_AMPBzrReq_Copy_0 "SEAT IMS Buzzer Request for AMP";
CM_ SG_ 187 DrvIMS_BzrReq_Copy_0 "PSM_DriverSeatImsBuzzerRequest";
CM_ SG_ 187 DrvIMS_ErrConWmgDis_Copy_0 "Warning about IMS Mem/Play Error Condition";
CM_ SG_ 187 DrvIMS_MemoryP1Req_Copy_0 "PSM_DriverSeatPositionMemoryP1Request";
CM_ SG_ 187 DrvIMS_MemoryP2Req_Copy_0 "PSM_DriverSeatPositionMemoryP2Request";
CM_ SG_ 187 DrvIMS_MemoryP3Req_Copy_0 "PSM_DriverSeatPositionMemoryP3Request";
CM_ SG_ 187 DrvIMS_PlyBckP1Req_Copy_0 "PSM_PlayBackP1Request";
CM_ SG_ 187 DrvIMS_PlyBckP2Req_Copy_0 "PSM_PlayBackP2Request";
CM_ SG_ 187 DrvIMS_PlyBckP3Req_Copy_0 "PSM_PlayBackP3Request";
CM_ SG_ 187 DrvIMS_PlyBckStpReq_Copy_0 "PSM_PlayBackStopRequest";
CM_ SG_ 187 AVN_SeatPosMemory_Cmd_Copy_0 "AVN_SeatPositionMemory_Command";
CM_ SG_ 187 AVN_SeatPosPlyBck_Cmd_Copy_0 "AVN_SeatPositionPlayBack_Command";
CM_ SG_ 187 SmrtIMS_EnterSwSta_Copy_0 "Smart IMS switch on using IMS switch";
CM_ SG_ 187 SmrtIMS_PlyBckReq_Copy_0 "HCIMS_PlayBackRequest";
CM_ SG_ 187 SmrtIMS_PlyBckStpReq_Copy_0 "HCIMS_Status";
CM_ SG_ 187 Drv_AutoRlxWrngDis_Copy_0 "Drive seat auto relax warning information for AVN display";
CM_ BO_ 2214592751 "[EW] On Event and On Write";
CM_ SG_ 2214592751 UWB_FRNK_Dvp_Data "Development Message";
CM_ BO_ 2214592738 "[EW] On Event and On Write";
CM_ SG_ 2214592738 L_UWB_FRNK_FD_Crc3Val "L_UWB_FRNK_FD_CyclicRedundancyCheck3Value";
CM_ SG_ 2214592738 L_UWB_FRNK_FD_AlvCnt3Val "L_UWB_FRNK_FD_AliveCounter3Value";
CM_ SG_ 2214592738 UWB_FRNK_Ranging_Enc_Result2 "UWB Ranging Result2(Encrypted Data) with DK";
CM_ SG_ 2214592738 UWB_FRNK_Ranging_Enc_Result "UWB Ranging Result with DK";
CM_ BO_ 2214592737 "[EC] On Event and On Change";
CM_ SG_ 2214592737 L_UWB_FRNK_FD_Crc2Val "L_UWB_FRNK_FD_CyclicRedundancyCheck2Value";
CM_ SG_ 2214592737 L_UWB_FRNK_FD_AlvCnt2Val "L_UWB_FRNK_FD_AliveCounter2Value";
CM_ SG_ 2214592737 UWB_FRNK_FOB_RSD_Enc_Result "UWB Ranging Result with FOB";
CM_ BO_ 2214592736 "[EC] On Event and On Change";
CM_ SG_ 2214592736 L_UWB_FRNK_FD_Crc1Val "L_UWB_FRNK_FD_CyclicRedundancyCheck1Value";
CM_ SG_ 2214592736 L_UWB_FRNK_FD_AlvCnt1Val "L_UWB_FRNK_FD_AliveCounter1Value";
CM_ SG_ 2214592736 UWB_FRNK_UWB_Decrypt_FB "Decryption Feedback for UWB (to BDC)";
CM_ SG_ 2214592736 UWB_FRNK_MST_Decrypt_FB "UWB FRNK Decryption FeedBack (to Master)";
CM_ SG_ 2214592736 UWB_FRNK_OTA_Rsp "UWB FRNK OTA response";
CM_ SG_ 2214592736 UWB_FRNK_UWB_IC_Status "UWB IC Status Message";
CM_ BO_ 2348810509 "[TP] Transport Protocol";
CM_ BO_ 745 "[PE] Periodic and On Event";
CM_ SG_ 745 PDC_FD_Crc15Val "PDC_FD_CyclicRedundancyCheck15Value";
CM_ SG_ 745 PDC_CurrAtReset_Copy_0 "This signal indicate the current at reset request";
CM_ SG_ 745 PDC_AvgCurrAtReset_Copy_0 "This signal indicate the average current at reset request";
CM_ SG_ 745 PDC_ResetReason_Copy_0 "This signal indicate the reason reset is operated";
CM_ SG_ 745 PDC_CumulativeCountOf12VReq_Copy "This signal indicates the cumulative number of 12V Controller req.";
CM_ SG_ 745 PDC_CumulativeCountOfCCUReq_Copy "This signal indicates the cumulative number of CCU_ForcedPowerOffReq";
CM_ SG_ 745 PDC_FD_AlvCnt15Val "PDC_FD_AliveCounter15Value";
CM_ SG_ 745 PDC_LDConReq_Copy_0 "LDC on request signal for High Voltage Battery Discharge";
CM_ SG_ 745 PDC_LDConReq_By_LVBat_Copy_0 "LDC on request signal for High Voltage Battery Discharge by Low Voltage Battery";
CM_ SG_ 745 PDC_LDConReq_By_OTA_Copy_0 "LDC on request signal for High Voltage Battery Discharge by OTA";
CM_ SG_ 745 PDC_LDConReq_By_Load_Copy_0 "LDC on request signal for High Voltage Battery Discharge by Load";
CM_ SG_ 745 PDC_LDConReq_By_ActiveOn_Copy_0 "LDC on request signal for High Voltage Battery Discharge by Active On";
CM_ SG_ 745 PDC_ResetPreWrngForCCU_Copy_0 "This is a warning signal for reset.  This signal is used for preparing sideeffect of reset by Gateway";
CM_ SG_ 745 PDC_ResetPreWrngForOthers_Copy_0 "This is a warning signal for reset.  This signal is used for preparing sideeffect of reset by Receivers";
CM_ SG_ 745 PDC_ResetReqForCCU_Copy_0 "This is a request signal for SW reset of Gateway";
CM_ SG_ 745 PDC_ResetReqForOthers_Copy_0 "This is a request signal for SW reset except for Gateway";
CM_ SG_ 745 PDC_ResetFuncOpt_Copy_0 "This signal inform whether reset fucntion at PDC is appiled or not";
CM_ SG_ 745 PDC_12VRlyCtrl_Copy_0 "This signal is request signal to control 12V battery internal relay for HW reset";
CM_ SG_ 745 PDC_CurrentValueForReset_Copy_0 "This signal sets the average discharge current value to be measured for PDC_TimevalueForReset to be considered as a situation requiring reset.";
CM_ SG_ 745 PDC_TimeValueForReset_Copy_0 "This signal sets the time value to be considered as a situation requiring reset.";
CM_ SG_ 745 PDC_12VRlyOffHoldingTime_Copy_0 "This signal sets how long the relay will be turned off when performing an HW reset using a 12 V battery internal relay.";
CM_ SG_ 745 PDC_ResetCountSetting_Copy_0 "This signal sets the number of resets performed.";
CM_ SG_ 745 PDC_ResetCount_Copy_0 "This signal indicates how much reset has occurred.";
CM_ SG_ 745 PDC_ResetCumulativeCount_Copy_0 "This signal indicates the cumulative number of resets performed.";
CM_ SG_ 745 PDC_ResetOpsta_Copy_0 "This signal indicates whether the reset operation has been completed or not";
CM_ SG_ 745 PDC_ReadyTimeValueForReset_Copy_ "This signal sets the time value to be considered as a situation of quiescent current";
CM_ BO_ 2348810508 "[TP] Transport Protocol";
CM_ BO_ 2348810507 "[TP] Transport Protocol";
BA_DEF_ BO_  "CANFD_BRS" ENUM  "0","1";
BA_DEF_ BO_  "GenMsgEVName" STRING ;
BA_DEF_ BO_  "NmAsrMessage" ENUM  "No","Yes";
BA_DEF_ BO_  "DiagState" ENUM  "No","Yes";
BA_DEF_ BO_  "DiagResponse" ENUM  "No","Yes";
BA_DEF_ BO_  "DiagRequest" ENUM  "No","Yes";
BA_DEF_ BO_  "TpMessage" ENUM  "No","Yes";
BA_DEF_ BO_  "UsrMsgIDSforwardDeviation" INT 0 100;
BA_DEF_ BO_  "UsrMsgIDSbackwardDeviation" INT 50 1000;
BA_DEF_ BO_  "GenMsgCycleTime" INT 0 2000;
BA_DEF_ BO_  "GenMsgStartDelayTime" INT 0 2000;
BA_DEF_ BO_  "GenMsgSendType" ENUM  "Cyclic","NoMsgSendType";
BA_DEF_ BO_  "GenMsgCycleTimeFast" INT 0 500;
BA_DEF_ BO_  "GenMsgDelayTime" INT 0 20;
BA_DEF_ BO_  "GenMsgILSupport" ENUM  "No","Yes";
BA_DEF_ BO_  "GenMsgNrOfRepetition" INT 0 3;
BA_DEF_ BO_  "TpTxIndex" INT 0 65535;
BA_DEF_ BO_  "VFrameFormat" ENUM  "StandardCAN","ExtendedCAN","reserved","reserved","reserved","reserved","reserved","reserved","reserved","reserved","reserved","reserved","reserved","reserved","StandardCAN_FD","ExtendedCAN_FD";
BA_DEF_ SG_  "UserSigValidity" ENUM  "B+","ACC","IG","IG1","IG2","IG3","IG1 or IG2","IG1 or IG3","Undef";
BA_DEF_ SG_  "TimeoutValue" STRING ;
BA_DEF_ SG_  "UsrSigPurpose" ENUM  "Undef","FN","DIAG","DIAG(Req)","DIAG(Res)","DIAG(Func)","DEV","CCP","NM","TP";
BA_DEF_ SG_  "GenSigStartValue" INT 0 1215752192;
BA_DEF_ SG_  "NetworkRequest" ENUM  "Yes","No";
BA_DEF_ SG_  "NetworkRequestHoldingTime" INT 0 65535;
BA_DEF_ SG_  "Description" STRING ;
BA_DEF_ SG_  "Version" STRING ;
BA_DEF_ SG_  "GenSigEnvVarType" ENUM  "Int","Float","Undef";
BA_DEF_ SG_  "GenSigSendType" ENUM  "Cyclic","OnWrite","OnWriteWithRepetition","OnChange","OnChangeWithRepetition","IfActive","IfActiveWithRepetition","NoSigSendType","OnChangeAndIfActive","OnChangeAndIfActiveWithRepetition";
BA_DEF_ SG_  "GwSigLatencyTime" INT 0 65536;
BA_DEF_ SG_  "GwSigMissingSourceType" ENUM  "Undef","OldValue","DefaultValue","InitialValue";
BA_DEF_ SG_  "NWM-WakeupAllowed" ENUM  "<n.a.>";
BA_DEF_ SG_  "RoutingFactor" INT 1 1215752192;
BA_DEF_ SG_  "SystemSignalLongSymbol" STRING ;
BA_DEF_REL_ BU_SG_REL_  "GenSigTimeoutTime" INT 0 7000;
BA_DEF_DEF_  "CANFD_BRS" "1";
BA_DEF_DEF_  "GenMsgEVName" "@Signame";
BA_DEF_DEF_  "NmAsrMessage" "No";
BA_DEF_DEF_  "DiagState" "No";
BA_DEF_DEF_  "DiagResponse" "No";
BA_DEF_DEF_  "DiagRequest" "No";
BA_DEF_DEF_  "TpMessage" "No";
BA_DEF_DEF_  "UsrMsgIDSforwardDeviation" 10;
BA_DEF_DEF_  "UsrMsgIDSbackwardDeviation" 100;
BA_DEF_DEF_  "GenMsgCycleTime" 200;
BA_DEF_DEF_  "GenMsgStartDelayTime" 0;
BA_DEF_DEF_  "GenMsgSendType" "NoMsgSendType";
BA_DEF_DEF_  "GenMsgCycleTimeFast" 40;
BA_DEF_DEF_  "GenMsgDelayTime" 20;
BA_DEF_DEF_  "GenMsgILSupport" "Yes";
BA_DEF_DEF_  "GenMsgNrOfRepetition" 3;
BA_DEF_DEF_  "TpTxIndex" 0;
BA_DEF_DEF_  "VFrameFormat" "StandardCAN";
BA_DEF_DEF_  "UserSigValidity" "IG";
BA_DEF_DEF_  "TimeoutValue" "";
BA_DEF_DEF_  "UsrSigPurpose" "FN";
BA_DEF_DEF_  "GenSigStartValue" 0;
BA_DEF_DEF_  "NetworkRequest" "No";
BA_DEF_DEF_  "NetworkRequestHoldingTime" 0;
BA_DEF_DEF_  "Description" "";
BA_DEF_DEF_  "Version" "";
BA_DEF_DEF_  "GenSigEnvVarType" "Undef";
BA_DEF_DEF_  "GenSigSendType" "NoSigSendType";
BA_DEF_DEF_  "GwSigLatencyTime" 40;
BA_DEF_DEF_  "GwSigMissingSourceType" "Undef";
BA_DEF_DEF_  "NWM-WakeupAllowed" "<n.a.>";
BA_DEF_DEF_  "RoutingFactor" 1;
BA_DEF_DEF_REL_ "GenSigTimeoutTime" 500;
BA_DEF_DEF_  "SystemSignalLongSymbol" "";
BA_ "GenMsgDelayTime" BO_ 2214592722 10;
BA_ "GenMsgCycleTime" BO_ 2214592722 0;
BA_ "VFrameFormat" BO_ 2214592722 15;
BA_ "GenMsgCycleTime" BO_ 2214592714 0;
BA_ "VFrameFormat" BO_ 2214592714 15;
BA_ "GenMsgDelayTime" BO_ 2214592719 10;
BA_ "GenMsgCycleTime" BO_ 2214592719 0;
BA_ "VFrameFormat" BO_ 2214592719 15;
BA_ "GenMsgDelayTime" BO_ 2521143553 10;
BA_ "GenMsgCycleTime" BO_ 2521143553 0;
BA_ "VFrameFormat" BO_ 2521143553 15;
BA_ "GenMsgCycleTime" BO_ 2214592705 0;
BA_ "VFrameFormat" BO_ 2214592705 15;
BA_ "GenMsgCycleTime" BO_ 2214592704 0;
BA_ "VFrameFormat" BO_ 2214592704 15;
BA_ "GenMsgDelayTime" BO_ 2214592706 10;
BA_ "GenMsgCycleTime" BO_ 2214592706 0;
BA_ "VFrameFormat" BO_ 2214592706 15;
BA_ "GenMsgDelayTime" BO_ 2525339649 10;
BA_ "GenMsgCycleTime" BO_ 2525339649 0;
BA_ "VFrameFormat" BO_ 2525339649 15;
BA_ "GenMsgDelayTime" BO_ 2214592767 10;
BA_ "GenMsgCycleTime" BO_ 2214592767 0;
BA_ "VFrameFormat" BO_ 2214592767 15;
BA_ "GenMsgDelayTime" BO_ 2214592754 10;
BA_ "GenMsgCycleTime" BO_ 2214592754 0;
BA_ "VFrameFormat" BO_ 2214592754 15;
BA_ "GenMsgCycleTime" BO_ 2214592752 0;
BA_ "VFrameFormat" BO_ 2214592752 15;
BA_ "GenMsgCycleTime" BO_ 2214592753 0;
BA_ "VFrameFormat" BO_ 2214592753 15;
BA_ "GenMsgCycleTime" BO_ 187 0;
BA_ "VFrameFormat" BO_ 187 14;
BA_ "GenMsgDelayTime" BO_ 2214592751 10;
BA_ "GenMsgCycleTime" BO_ 2214592751 0;
BA_ "VFrameFormat" BO_ 2214592751 15;
BA_ "GenMsgDelayTime" BO_ 2214592738 10;
BA_ "GenMsgCycleTime" BO_ 2214592738 0;
BA_ "VFrameFormat" BO_ 2214592738 15;
BA_ "GenMsgCycleTime" BO_ 2214592737 0;
BA_ "VFrameFormat" BO_ 2214592737 15;
BA_ "GenMsgCycleTime" BO_ 2214592736 0;
BA_ "VFrameFormat" BO_ 2214592736 15;
BA_ "TpTxIndex" BO_ 2348810509 276;
BA_ "TpMessage" BO_ 2348810509 1;
BA_ "GenMsgILSupport" BO_ 2348810509 0;
BA_ "GenMsgNrOfRepetition" BO_ 2348810509 0;
BA_ "GenMsgCycleTimeFast" BO_ 2348810509 0;
BA_ "GenMsgCycleTime" BO_ 2348810509 0;
BA_ "VFrameFormat" BO_ 2348810509 15;
BA_ "GenMsgCycleTime" BO_ 745 300;
BA_ "GenMsgSendType" BO_ 745 0;
BA_ "VFrameFormat" BO_ 745 14;
BA_ "TpTxIndex" BO_ 2348810508 276;
BA_ "TpMessage" BO_ 2348810508 1;
BA_ "GenMsgILSupport" BO_ 2348810508 0;
BA_ "GenMsgNrOfRepetition" BO_ 2348810508 0;
BA_ "GenMsgCycleTimeFast" BO_ 2348810508 0;
BA_ "GenMsgCycleTime" BO_ 2348810508 0;
BA_ "VFrameFormat" BO_ 2348810508 15;
BA_ "TpTxIndex" BO_ 2348810507 275;
BA_ "TpMessage" BO_ 2348810507 1;
BA_ "GenMsgILSupport" BO_ 2348810507 0;
BA_ "GenMsgNrOfRepetition" BO_ 2348810507 0;
BA_ "GenMsgCycleTimeFast" BO_ 2348810507 0;
BA_ "GenMsgCycleTime" BO_ 2348810507 0;
BA_ "VFrameFormat" BO_ 2348810507 15;
BA_ "Version" SG_ 2214592722 L_UWB_FR_FD_Crc3Val "23.01.02";
BA_ "UserSigValidity" SG_ 2214592722 L_UWB_FR_FD_Crc3Val 3;
BA_ "GenSigStartValue" SG_ 2214592722 L_UWB_FR_FD_Crc3Val 65535;
BA_ "GenSigSendType" SG_ 2214592722 L_UWB_FR_FD_Crc3Val 2;
BA_ "Description" SG_ 2214592722 L_UWB_FR_FD_Crc3Val "The data area for CRC calculation is based on the data length (DLC) of the message DB.

The CRC shall be calculated over the entire data block (excluding the CRC bytes) including the user data, alive counter and Data ID



- CRC Polynomial (0x1021) , Ini";
BA_ "Version" SG_ 2214592722 L_UWB_FR_FD_AlvCnt3Val "23.01.02";
BA_ "UserSigValidity" SG_ 2214592722 L_UWB_FR_FD_AlvCnt3Val 3;
BA_ "GenSigSendType" SG_ 2214592722 L_UWB_FR_FD_AlvCnt3Val 2;
BA_ "Description" SG_ 2214592722 L_UWB_FR_FD_AlvCnt3Val "For the first transmission request for a data element the counter shall be initialized with 0 and shall be incremented by 1 for every subsequent send request. 

When the counter reaches the maximum value(0xFF), then it shall restart with 0 for the next s";
BA_ "Version" SG_ 2214592722 UWB_FR_Ranging_Enc_Result2 "24.04.06";
BA_ "UserSigValidity" SG_ 2214592722 UWB_FR_Ranging_Enc_Result2 0;
BA_ "GenSigSendType" SG_ 2214592722 UWB_FR_Ranging_Enc_Result2 2;
BA_ "Description" SG_ 2214592722 UWB_FR_Ranging_Enc_Result2 "UWB Ranging Result2(Encrypted Data) with DK";
BA_ "Version" SG_ 2214592722 UWB_FR_Ranging_Enc_Result "23.01.02";
BA_ "UserSigValidity" SG_ 2214592722 UWB_FR_Ranging_Enc_Result 0;
BA_ "GenSigSendType" SG_ 2214592722 UWB_FR_Ranging_Enc_Result 2;
BA_ "Version" SG_ 2214592714 L_UWB_BLE_MST_FD_Crc22Val "23.11.05";
BA_ "UserSigValidity" SG_ 2214592714 L_UWB_BLE_MST_FD_Crc22Val 3;
BA_ "GenSigStartValue" SG_ 2214592714 L_UWB_BLE_MST_FD_Crc22Val 65535;
BA_ "GenSigSendType" SG_ 2214592714 L_UWB_BLE_MST_FD_Crc22Val 4;
BA_ "Description" SG_ 2214592714 L_UWB_BLE_MST_FD_Crc22Val "The data area for CRC calculation is based on the data length (DLC) of the message DB.

The CRC shall be calculated over the entire data block (excluding the CRC bytes) including the user data, alive counter and Data ID



- CRC Polynomial (0x1021) , Ini";
BA_ "Version" SG_ 2214592714 L_UWB_BLE_MST_FD_AlvCnt22Val "23.11.05";
BA_ "UserSigValidity" SG_ 2214592714 L_UWB_BLE_MST_FD_AlvCnt22Val 3;
BA_ "GenSigSendType" SG_ 2214592714 L_UWB_BLE_MST_FD_AlvCnt22Val 4;
BA_ "Description" SG_ 2214592714 L_UWB_BLE_MST_FD_AlvCnt22Val "For the first transmission request for a data element the counter shall be initialized with 0 and shall be incremented by 1 for every subsequent send request. 

When the counter reaches the maximum value(0xFF), then it shall restart with 0 for the next s";
BA_ "Version" SG_ 2214592714 MST_DisconnectDKID "23.11.05";
BA_ "UserSigValidity" SG_ 2214592714 MST_DisconnectDKID 0;
BA_ "GenSigSendType" SG_ 2214592714 MST_DisconnectDKID 4;
BA_ "Description" SG_ 2214592714 MST_DisconnectDKID "For checking disconnected DK ID";
BA_ "Version" SG_ 2214592714 MST_DisconnectReason "23.11.05";
BA_ "UserSigValidity" SG_ 2214592714 MST_DisconnectReason 0;
BA_ "GenSigSendType" SG_ 2214592714 MST_DisconnectReason 4;
BA_ "Description" SG_ 2214592714 MST_DisconnectReason "For analyzing disconnected reason";
BA_ "Version" SG_ 2214592714 MST_BLE_ErrorReturn "24.01.04";
BA_ "UserSigValidity" SG_ 2214592714 MST_BLE_ErrorReturn 0;
BA_ "GenSigSendType" SG_ 2214592714 MST_BLE_ErrorReturn 4;
BA_ "Description" SG_ 2214592714 MST_BLE_ErrorReturn "Valid Range : 0x00 ~ 0xFF";
BA_ "Version" SG_ 2214592719 UWB_FL_Dvp_Data "23.01.02";
BA_ "UserSigValidity" SG_ 2214592719 UWB_FL_Dvp_Data 0;
BA_ "GenSigSendType" SG_ 2214592719 UWB_FL_Dvp_Data 2;
BA_ "Version" SG_ 2521143553 L_UWB_BLE_SLV_FD_Crc13Val "24.07.05";
BA_ "RoutingFactor" SG_ 2521143553 L_UWB_BLE_SLV_FD_Crc13Val 0;
BA_ "UserSigValidity" SG_ 2521143553 L_UWB_BLE_SLV_FD_Crc13Val 3;
BA_ "GenSigStartValue" SG_ 2521143553 L_UWB_BLE_SLV_FD_Crc13Val 65535;
BA_ "GenSigSendType" SG_ 2521143553 L_UWB_BLE_SLV_FD_Crc13Val 2;
BA_ "Description" SG_ 2521143553 L_UWB_BLE_SLV_FD_Crc13Val "The data area for CRC calculation is based on the data length (DLC) of the message DB.

The CRC shall be calculated over the entire data block (excluding the CRC bytes) including the user data, alive counter and Data ID



- CRC Polynomial (0x1021) , Ini";
BA_ "Version" SG_ 2521143553 L_UWB_BLE_SLV_FD_AlvCnt13Val "24.07.05";
BA_ "RoutingFactor" SG_ 2521143553 L_UWB_BLE_SLV_FD_AlvCnt13Val 0;
BA_ "UserSigValidity" SG_ 2521143553 L_UWB_BLE_SLV_FD_AlvCnt13Val 3;
BA_ "GenSigSendType" SG_ 2521143553 L_UWB_BLE_SLV_FD_AlvCnt13Val 2;
BA_ "Description" SG_ 2521143553 L_UWB_BLE_SLV_FD_AlvCnt13Val "For the first transmission request for a data element the counter shall be initialized with 0 and shall be incremented by 1 for every subsequent send request. 

When the counter reaches the maximum value(0xFF), then it shall restart with 0 for the next s";
BA_ "Version" SG_ 2521143553 SLV_SWID_4_IVD_1 "24.07.05";
BA_ "RoutingFactor" SG_ 2521143553 SLV_SWID_4_IVD_1 0;
BA_ "UserSigValidity" SG_ 2521143553 SLV_SWID_4_IVD_1 0;
BA_ "GenSigSendType" SG_ 2521143553 SLV_SWID_4_IVD_1 2;
BA_ "Version" SG_ 2214592705 L_UWB_FL_FD_Crc2Val "23.01.02";
BA_ "UserSigValidity" SG_ 2214592705 L_UWB_FL_FD_Crc2Val 3;
BA_ "GenSigStartValue" SG_ 2214592705 L_UWB_FL_FD_Crc2Val 65535;
BA_ "GenSigSendType" SG_ 2214592705 L_UWB_FL_FD_Crc2Val 4;
BA_ "Description" SG_ 2214592705 L_UWB_FL_FD_Crc2Val "The data area for CRC calculation is based on the data length (DLC) of the message DB.

The CRC shall be calculated over the entire data block (excluding the CRC bytes) including the user data, alive counter and Data ID



- CRC Polynomial (0x1021) , Ini";
BA_ "Version" SG_ 2214592705 L_UWB_FL_FD_AlvCnt2Val "23.01.02";
BA_ "UserSigValidity" SG_ 2214592705 L_UWB_FL_FD_AlvCnt2Val 3;
BA_ "GenSigSendType" SG_ 2214592705 L_UWB_FL_FD_AlvCnt2Val 4;
BA_ "Description" SG_ 2214592705 L_UWB_FL_FD_AlvCnt2Val "For the first transmission request for a data element the counter shall be initialized with 0 and shall be incremented by 1 for every subsequent send request. 

When the counter reaches the maximum value(0xFF), then it shall restart with 0 for the next s";
BA_ "Version" SG_ 2214592705 UWB_FL_FOB_RSD_Enc_Result "23.01.02";
BA_ "UserSigValidity" SG_ 2214592705 UWB_FL_FOB_RSD_Enc_Result 0;
BA_ "GenSigSendType" SG_ 2214592705 UWB_FL_FOB_RSD_Enc_Result 4;
BA_ "Version" SG_ 2214592704 L_UWB_FL_FD_Crc1Val "23.01.02";
BA_ "UserSigValidity" SG_ 2214592704 L_UWB_FL_FD_Crc1Val 3;
BA_ "GenSigStartValue" SG_ 2214592704 L_UWB_FL_FD_Crc1Val 65535;
BA_ "GenSigSendType" SG_ 2214592704 L_UWB_FL_FD_Crc1Val 4;
BA_ "Description" SG_ 2214592704 L_UWB_FL_FD_Crc1Val "The data area for CRC calculation is based on the data length (DLC) of the message DB.

The CRC shall be calculated over the entire data block (excluding the CRC bytes) including the user data, alive counter and Data ID



- CRC Polynomial (0x1021) , Ini";
BA_ "Version" SG_ 2214592704 L_UWB_FL_FD_AlvCnt1Val "23.01.02";
BA_ "UserSigValidity" SG_ 2214592704 L_UWB_FL_FD_AlvCnt1Val 3;
BA_ "GenSigSendType" SG_ 2214592704 L_UWB_FL_FD_AlvCnt1Val 4;
BA_ "Description" SG_ 2214592704 L_UWB_FL_FD_AlvCnt1Val "For the first transmission request for a data element the counter shall be initialized with 0 and shall be incremented by 1 for every subsequent send request. 

When the counter reaches the maximum value(0xFF), then it shall restart with 0 for the next s";
BA_ "Version" SG_ 2214592704 UWB_FL_UWB_Decrypt_FB "23.01.02";
BA_ "UserSigValidity" SG_ 2214592704 UWB_FL_UWB_Decrypt_FB 0;
BA_ "GenSigSendType" SG_ 2214592704 UWB_FL_UWB_Decrypt_FB 4;
BA_ "Version" SG_ 2214592704 UWB_FL_MST_Decrypt_FB "23.01.02";
BA_ "UserSigValidity" SG_ 2214592704 UWB_FL_MST_Decrypt_FB 0;
BA_ "GenSigSendType" SG_ 2214592704 UWB_FL_MST_Decrypt_FB 4;
BA_ "Version" SG_ 2214592704 UWB_FL_OTA_Rsp "24.07.05";
BA_ "UserSigValidity" SG_ 2214592704 UWB_FL_OTA_Rsp 0;
BA_ "GenSigSendType" SG_ 2214592704 UWB_FL_OTA_Rsp 4;
BA_ "Description" SG_ 2214592704 UWB_FL_OTA_Rsp "UWB FL OTA response";
BA_ "Version" SG_ 2214592704 UWB_FL_UWB_IC_Status "24.04.03";
BA_ "UserSigValidity" SG_ 2214592704 UWB_FL_UWB_IC_Status 0;
BA_ "GenSigSendType" SG_ 2214592704 UWB_FL_UWB_IC_Status 4;
BA_ "Description" SG_ 2214592704 UWB_FL_UWB_IC_Status "UWB IC Status Message";
BA_ "Version" SG_ 2214592706 L_UWB_FL_FD_Crc3Val "23.01.02";
BA_ "UserSigValidity" SG_ 2214592706 L_UWB_FL_FD_Crc3Val 3;
BA_ "GenSigStartValue" SG_ 2214592706 L_UWB_FL_FD_Crc3Val 65535;
BA_ "GenSigSendType" SG_ 2214592706 L_UWB_FL_FD_Crc3Val 2;
BA_ "Description" SG_ 2214592706 L_UWB_FL_FD_Crc3Val "The data area for CRC calculation is based on the data length (DLC) of the message DB.

The CRC shall be calculated over the entire data block (excluding the CRC bytes) including the user data, alive counter and Data ID



- CRC Polynomial (0x1021) , Ini";
BA_ "Version" SG_ 2214592706 L_UWB_FL_FD_AlvCnt3Val "23.01.02";
BA_ "UserSigValidity" SG_ 2214592706 L_UWB_FL_FD_AlvCnt3Val 3;
BA_ "GenSigSendType" SG_ 2214592706 L_UWB_FL_FD_AlvCnt3Val 2;
BA_ "Description" SG_ 2214592706 L_UWB_FL_FD_AlvCnt3Val "For the first transmission request for a data element the counter shall be initialized with 0 and shall be incremented by 1 for every subsequent send request. 

When the counter reaches the maximum value(0xFF), then it shall restart with 0 for the next s";
BA_ "Version" SG_ 2214592706 UWB_FL_Ranging_Enc_Result2 "24.04.06";
BA_ "UserSigValidity" SG_ 2214592706 UWB_FL_Ranging_Enc_Result2 0;
BA_ "GenSigSendType" SG_ 2214592706 UWB_FL_Ranging_Enc_Result2 2;
BA_ "Description" SG_ 2214592706 UWB_FL_Ranging_Enc_Result2 "UWB Ranging Result2(Encrypted Data) with DK";
BA_ "Version" SG_ 2214592706 UWB_FL_Ranging_Enc_Result "23.01.02";
BA_ "UserSigValidity" SG_ 2214592706 UWB_FL_Ranging_Enc_Result 0;
BA_ "GenSigSendType" SG_ 2214592706 UWB_FL_Ranging_Enc_Result 2;
BA_ "Version" SG_ 2525339649 L_UWB_FL_FD_Crc4Val "24.07.05";
BA_ "RoutingFactor" SG_ 2525339649 L_UWB_FL_FD_Crc4Val 0;
BA_ "UserSigValidity" SG_ 2525339649 L_UWB_FL_FD_Crc4Val 3;
BA_ "GenSigStartValue" SG_ 2525339649 L_UWB_FL_FD_Crc4Val 65535;
BA_ "GenSigSendType" SG_ 2525339649 L_UWB_FL_FD_Crc4Val 2;
BA_ "Description" SG_ 2525339649 L_UWB_FL_FD_Crc4Val "The data area for CRC calculation is based on the data length (DLC) of the message DB.

The CRC shall be calculated over the entire data block (excluding the CRC bytes) including the user data, alive counter and Data ID



- CRC Polynomial (0x1021) , Ini";
BA_ "Version" SG_ 2525339649 L_UWB_FL_FD_AlvCnt4Val "24.07.05";
BA_ "RoutingFactor" SG_ 2525339649 L_UWB_FL_FD_AlvCnt4Val 0;
BA_ "UserSigValidity" SG_ 2525339649 L_UWB_FL_FD_AlvCnt4Val 3;
BA_ "GenSigSendType" SG_ 2525339649 L_UWB_FL_FD_AlvCnt4Val 2;
BA_ "Description" SG_ 2525339649 L_UWB_FL_FD_AlvCnt4Val "For the first transmission request for a data element the counter shall be initialized with 0 and shall be incremented by 1 for every subsequent send request. 

When the counter reaches the maximum value(0xFF), then it shall restart with 0 for the next s";
BA_ "Version" SG_ 2525339649 FL_SWID_3_IVD_1 "24.07.05";
BA_ "RoutingFactor" SG_ 2525339649 FL_SWID_3_IVD_1 0;
BA_ "UserSigValidity" SG_ 2525339649 FL_SWID_3_IVD_1 0;
BA_ "GenSigSendType" SG_ 2525339649 FL_SWID_3_IVD_1 2;
BA_ "Version" SG_ 2214592767 UWB_RL_Dvp_Data "23.01.02";
BA_ "UserSigValidity" SG_ 2214592767 UWB_RL_Dvp_Data 0;
BA_ "GenSigSendType" SG_ 2214592767 UWB_RL_Dvp_Data 2;
BA_ "Version" SG_ 2214592754 L_UWB_RL_FD_Crc3Val "23.01.02";
BA_ "UserSigValidity" SG_ 2214592754 L_UWB_RL_FD_Crc3Val 3;
BA_ "GenSigStartValue" SG_ 2214592754 L_UWB_RL_FD_Crc3Val 65535;
BA_ "GenSigSendType" SG_ 2214592754 L_UWB_RL_FD_Crc3Val 2;
BA_ "Description" SG_ 2214592754 L_UWB_RL_FD_Crc3Val "The data area for CRC calculation is based on the data length (DLC) of the message DB.

The CRC shall be calculated over the entire data block (excluding the CRC bytes) including the user data, alive counter and Data ID



- CRC Polynomial (0x1021) , Ini";
BA_ "Version" SG_ 2214592754 L_UWB_RL_FD_AlvCnt3Val "23.01.02";
BA_ "UserSigValidity" SG_ 2214592754 L_UWB_RL_FD_AlvCnt3Val 3;
BA_ "GenSigSendType" SG_ 2214592754 L_UWB_RL_FD_AlvCnt3Val 2;
BA_ "Description" SG_ 2214592754 L_UWB_RL_FD_AlvCnt3Val "For the first transmission request for a data element the counter shall be initialized with 0 and shall be incremented by 1 for every subsequent send request. 

When the counter reaches the maximum value(0xFF), then it shall restart with 0 for the next s";
BA_ "Version" SG_ 2214592754 UWB_RL_Ranging_Enc_Result2 "24.04.06";
BA_ "UserSigValidity" SG_ 2214592754 UWB_RL_Ranging_Enc_Result2 0;
BA_ "GenSigSendType" SG_ 2214592754 UWB_RL_Ranging_Enc_Result2 2;
BA_ "Description" SG_ 2214592754 UWB_RL_Ranging_Enc_Result2 "UWB Ranging Result2(Encrypted Data) with DK";
BA_ "Version" SG_ 2214592754 UWB_RL_Ranging_Enc_Result "23.01.02";
BA_ "UserSigValidity" SG_ 2214592754 UWB_RL_Ranging_Enc_Result 0;
BA_ "GenSigSendType" SG_ 2214592754 UWB_RL_Ranging_Enc_Result 2;
BA_ "Version" SG_ 2214592752 L_UWB_RL_FD_Crc1Val "23.01.02";
BA_ "UserSigValidity" SG_ 2214592752 L_UWB_RL_FD_Crc1Val 3;
BA_ "GenSigStartValue" SG_ 2214592752 L_UWB_RL_FD_Crc1Val 65535;
BA_ "GenSigSendType" SG_ 2214592752 L_UWB_RL_FD_Crc1Val 4;
BA_ "Description" SG_ 2214592752 L_UWB_RL_FD_Crc1Val "The data area for CRC calculation is based on the data length (DLC) of the message DB.

The CRC shall be calculated over the entire data block (excluding the CRC bytes) including the user data, alive counter and Data ID



- CRC Polynomial (0x1021) , Ini";
BA_ "Version" SG_ 2214592752 L_UWB_RL_FD_AlvCnt1Val "23.01.02";
BA_ "UserSigValidity" SG_ 2214592752 L_UWB_RL_FD_AlvCnt1Val 3;
BA_ "GenSigSendType" SG_ 2214592752 L_UWB_RL_FD_AlvCnt1Val 4;
BA_ "Description" SG_ 2214592752 L_UWB_RL_FD_AlvCnt1Val "For the first transmission request for a data element the counter shall be initialized with 0 and shall be incremented by 1 for every subsequent send request. 

When the counter reaches the maximum value(0xFF), then it shall restart with 0 for the next s";
BA_ "Version" SG_ 2214592752 UWB_RL_UWB_Decrypt_FB "23.01.02";
BA_ "UserSigValidity" SG_ 2214592752 UWB_RL_UWB_Decrypt_FB 0;
BA_ "GenSigSendType" SG_ 2214592752 UWB_RL_UWB_Decrypt_FB 4;
BA_ "Version" SG_ 2214592752 UWB_RL_MST_Decrypt_FB "23.01.02";
BA_ "UserSigValidity" SG_ 2214592752 UWB_RL_MST_Decrypt_FB 0;
BA_ "GenSigSendType" SG_ 2214592752 UWB_RL_MST_Decrypt_FB 4;
BA_ "Version" SG_ 2214592752 UWB_RL_OTA_Rsp "24.07.05";
BA_ "UserSigValidity" SG_ 2214592752 UWB_RL_OTA_Rsp 0;
BA_ "GenSigSendType" SG_ 2214592752 UWB_RL_OTA_Rsp 4;
BA_ "Description" SG_ 2214592752 UWB_RL_OTA_Rsp "UWB RL OTA response";
BA_ "Version" SG_ 2214592752 UWB_RL_UWB_IC_Status "24.04.03";
BA_ "UserSigValidity" SG_ 2214592752 UWB_RL_UWB_IC_Status 0;
BA_ "GenSigSendType" SG_ 2214592752 UWB_RL_UWB_IC_Status 4;
BA_ "Description" SG_ 2214592752 UWB_RL_UWB_IC_Status "UWB IC Status Message";
BA_ "Version" SG_ 2214592753 L_UWB_RL_FD_Crc2Val "23.01.02";
BA_ "UserSigValidity" SG_ 2214592753 L_UWB_RL_FD_Crc2Val 3;
BA_ "GenSigStartValue" SG_ 2214592753 L_UWB_RL_FD_Crc2Val 65535;
BA_ "GenSigSendType" SG_ 2214592753 L_UWB_RL_FD_Crc2Val 4;
BA_ "Description" SG_ 2214592753 L_UWB_RL_FD_Crc2Val "The data area for CRC calculation is based on the data length (DLC) of the message DB.

The CRC shall be calculated over the entire data block (excluding the CRC bytes) including the user data, alive counter and Data ID



- CRC Polynomial (0x1021) , Ini";
BA_ "Version" SG_ 2214592753 L_UWB_RL_FD_AlvCnt2Val "23.01.02";
BA_ "UserSigValidity" SG_ 2214592753 L_UWB_RL_FD_AlvCnt2Val 3;
BA_ "GenSigSendType" SG_ 2214592753 L_UWB_RL_FD_AlvCnt2Val 4;
BA_ "Description" SG_ 2214592753 L_UWB_RL_FD_AlvCnt2Val "For the first transmission request for a data element the counter shall be initialized with 0 and shall be incremented by 1 for every subsequent send request. 

When the counter reaches the maximum value(0xFF), then it shall restart with 0 for the next s";
BA_ "Version" SG_ 2214592753 UWB_RL_FOB_RSD_Enc_Result "23.01.02";
BA_ "UserSigValidity" SG_ 2214592753 UWB_RL_FOB_RSD_Enc_Result 0;
BA_ "GenSigSendType" SG_ 2214592753 UWB_RL_FOB_RSD_Enc_Result 4;
BA_ "Version" SG_ 187 BDC_FD_Crc1Val "22.11.04";
BA_ "UserSigValidity" SG_ 187 BDC_FD_Crc1Val 0;
BA_ "GenSigStartValue" SG_ 187 BDC_FD_Crc1Val 65535;
BA_ "GenSigSendType" SG_ 187 BDC_FD_Crc1Val 4;
BA_ "Description" SG_ 187 BDC_FD_Crc1Val "The data area for CRC calculation is based on the data length (DLC) of the message DB.

The CRC shall be calculated over the entire data block (excluding the CRC bytes) including the user data, alive counter and Data ID



- CRC Polynomial (0x1021) , Ini";
BA_ "Version" SG_ 187 Ast_AutoRlxWrngDis_Copy_0 "21.06.10";
BA_ "NetworkRequestHoldingTime" SG_ 187 Ast_AutoRlxWrngDis_Copy_0 5000;
BA_ "NetworkRequest" SG_ 187 Ast_AutoRlxWrngDis_Copy_0 0;
BA_ "UserSigValidity" SG_ 187 Ast_AutoRlxWrngDis_Copy_0 1;
BA_ "GenSigSendType" SG_ 187 Ast_AutoRlxWrngDis_Copy_0 4;
BA_ "Version" SG_ 187 RLPSU_FailState_PopUp_Copy_0 "22.11.00";
BA_ "UserSigValidity" SG_ 187 RLPSU_FailState_PopUp_Copy_0 0;
BA_ "GenSigSendType" SG_ 187 RLPSU_FailState_PopUp_Copy_0 4;
BA_ "Description" SG_ 187 RLPSU_FailState_PopUp_Copy_0 "Rear LH Seat Operating Finish or Operating Disable Information for AVN Display";
BA_ "Version" SG_ 187 RRPSU_FailState_PopUp_Copy_0 "22.11.00";
BA_ "UserSigValidity" SG_ 187 RRPSU_FailState_PopUp_Copy_0 0;
BA_ "GenSigSendType" SG_ 187 RRPSU_FailState_PopUp_Copy_0 4;
BA_ "Description" SG_ 187 RRPSU_FailState_PopUp_Copy_0 "2nd RH Seat Operating Finish or Operating Disable Information for AVN Display";
BA_ "Version" SG_ 187 Pseat_AllSeatIMSMemoryDelReq "23.02.02";
BA_ "UserSigValidity" SG_ 187 Pseat_AllSeatIMSMemoryDelReq 0;
BA_ "GenSigSendType" SG_ 187 Pseat_AllSeatIMSMemoryDelReq 4;
BA_ "Description" SG_ 187 Pseat_AllSeatIMSMemoryDelReq "AllSeatIMSMemoryDeleteReq";
BA_ "Version" SG_ 187 PSeat_RLVIPRelaxionMemoryDelReq "23.02.02";
BA_ "UserSigValidity" SG_ 187 PSeat_RLVIPRelaxionMemoryDelReq 0;
BA_ "GenSigSendType" SG_ 187 PSeat_RLVIPRelaxionMemoryDelReq 4;
BA_ "Description" SG_ 187 PSeat_RLVIPRelaxionMemoryDelReq "SecondRLVIPRelaxionMemoryDeleteReq";
BA_ "Version" SG_ 187 PSeat_RRVIPRelaxionMemoryDelReq "23.02.02";
BA_ "UserSigValidity" SG_ 187 PSeat_RRVIPRelaxionMemoryDelReq 0;
BA_ "GenSigSendType" SG_ 187 PSeat_RRVIPRelaxionMemoryDelReq 4;
BA_ "Description" SG_ 187 PSeat_RRVIPRelaxionMemoryDelReq "SecondRRVIPRelaxionMemoryDeleteReq";
BA_ "Version" SG_ 187 Lamp_FrunkLampCmd "23.06.00";
BA_ "NetworkRequestHoldingTime" SG_ 187 Lamp_FrunkLampCmd 5000;
BA_ "NetworkRequest" SG_ 187 Lamp_FrunkLampCmd 0;
BA_ "UserSigValidity" SG_ 187 Lamp_FrunkLampCmd 0;
BA_ "GenSigSendType" SG_ 187 Lamp_FrunkLampCmd 4;
BA_ "Version" SG_ 187 Lamp_DrvCourtesyLampCmd "23.04.03";
BA_ "NetworkRequestHoldingTime" SG_ 187 Lamp_DrvCourtesyLampCmd 5000;
BA_ "NetworkRequest" SG_ 187 Lamp_DrvCourtesyLampCmd 0;
BA_ "UserSigValidity" SG_ 187 Lamp_DrvCourtesyLampCmd 0;
BA_ "GenSigSendType" SG_ 187 Lamp_DrvCourtesyLampCmd 4;
BA_ "Version" SG_ 187 Lamp_AstCourtesyLampCmd "23.04.03";
BA_ "NetworkRequestHoldingTime" SG_ 187 Lamp_AstCourtesyLampCmd 5000;
BA_ "NetworkRequest" SG_ 187 Lamp_AstCourtesyLampCmd 0;
BA_ "UserSigValidity" SG_ 187 Lamp_AstCourtesyLampCmd 0;
BA_ "GenSigSendType" SG_ 187 Lamp_AstCourtesyLampCmd 4;
BA_ "Version" SG_ 187 Lamp_RLCourtesyLampCmd "23.04.03";
BA_ "NetworkRequestHoldingTime" SG_ 187 Lamp_RLCourtesyLampCmd 5000;
BA_ "NetworkRequest" SG_ 187 Lamp_RLCourtesyLampCmd 0;
BA_ "UserSigValidity" SG_ 187 Lamp_RLCourtesyLampCmd 0;
BA_ "GenSigSendType" SG_ 187 Lamp_RLCourtesyLampCmd 4;
BA_ "Version" SG_ 187 Lamp_RRCourtesyLampCmd "23.04.03";
BA_ "NetworkRequestHoldingTime" SG_ 187 Lamp_RRCourtesyLampCmd 5000;
BA_ "NetworkRequest" SG_ 187 Lamp_RRCourtesyLampCmd 0;
BA_ "UserSigValidity" SG_ 187 Lamp_RRCourtesyLampCmd 0;
BA_ "GenSigSendType" SG_ 187 Lamp_RRCourtesyLampCmd 4;
BA_ "Version" SG_ 187 Lamp_RoomLampCmd "23.04.03";
BA_ "NetworkRequestHoldingTime" SG_ 187 Lamp_RoomLampCmd 5000;
BA_ "NetworkRequest" SG_ 187 Lamp_RoomLampCmd 0;
BA_ "UserSigValidity" SG_ 187 Lamp_RoomLampCmd 0;
BA_ "GenSigSendType" SG_ 187 Lamp_RoomLampCmd 4;
BA_ "Version" SG_ 187 Lamp_FootLampCmd "23.04.03";
BA_ "NetworkRequestHoldingTime" SG_ 187 Lamp_FootLampCmd 5000;
BA_ "NetworkRequest" SG_ 187 Lamp_FootLampCmd 0;
BA_ "UserSigValidity" SG_ 187 Lamp_FootLampCmd 0;
BA_ "GenSigSendType" SG_ 187 Lamp_FootLampCmd 4;
BA_ "Version" SG_ 187 PFSU_3LAMPBzrReq_Copy_0 "22.11.00";
BA_ "NetworkRequestHoldingTime" SG_ 187 PFSU_3LAMPBzrReq_Copy_0 5000;
BA_ "NetworkRequest" SG_ 187 PFSU_3LAMPBzrReq_Copy_0 0;
BA_ "UserSigValidity" SG_ 187 PFSU_3LAMPBzrReq_Copy_0 0;
BA_ "GenSigSendType" SG_ 187 PFSU_3LAMPBzrReq_Copy_0 4;
BA_ "Description" SG_ 187 PFSU_3LAMPBzrReq_Copy_0 "3rd Left SEAT IMS Buzzer Request for AMP or Inner Speaker";
BA_ "Version" SG_ 187 PFSU_3RAMPBzrReq_Copy_0 "22.11.00";
BA_ "NetworkRequestHoldingTime" SG_ 187 PFSU_3RAMPBzrReq_Copy_0 5000;
BA_ "NetworkRequest" SG_ 187 PFSU_3RAMPBzrReq_Copy_0 0;
BA_ "UserSigValidity" SG_ 187 PFSU_3RAMPBzrReq_Copy_0 0;
BA_ "GenSigSendType" SG_ 187 PFSU_3RAMPBzrReq_Copy_0 4;
BA_ "Description" SG_ 187 PFSU_3RAMPBzrReq_Copy_0 "3rd Right SEAT IMS Buzzer Request for AMP or Inner Speaker";
BA_ "Version" SG_ 187 Drv_AutoRlxWrngDis_2_Copy_0 "22.11.03";
BA_ "NetworkRequestHoldingTime" SG_ 187 Drv_AutoRlxWrngDis_2_Copy_0 5000;
BA_ "NetworkRequest" SG_ 187 Drv_AutoRlxWrngDis_2_Copy_0 0;
BA_ "UserSigValidity" SG_ 187 Drv_AutoRlxWrngDis_2_Copy_0 1;
BA_ "GenSigSendType" SG_ 187 Drv_AutoRlxWrngDis_2_Copy_0 4;
BA_ "Version" SG_ 187 Ast_AutoRlxWrngDis_2_Copy_0 "22.11.00";
BA_ "NetworkRequestHoldingTime" SG_ 187 Ast_AutoRlxWrngDis_2_Copy_0 5000;
BA_ "NetworkRequest" SG_ 187 Ast_AutoRlxWrngDis_2_Copy_0 0;
BA_ "UserSigValidity" SG_ 187 Ast_AutoRlxWrngDis_2_Copy_0 1;
BA_ "GenSigSendType" SG_ 187 Ast_AutoRlxWrngDis_2_Copy_0 4;
BA_ "Description" SG_ 187 Ast_AutoRlxWrngDis_2_Copy_0 "Assist seat auto relax warning information for AVN Display";
BA_ "Version" SG_ 187 RLPSU_Folding_State_Popup_EC_Cop "22.11.00";
BA_ "UserSigValidity" SG_ 187 RLPSU_Folding_State_Popup_EC_Cop 0;
BA_ "GenSigSendType" SG_ 187 RLPSU_Folding_State_Popup_EC_Cop 4;
BA_ "Description" SG_ 187 RLPSU_Folding_State_Popup_EC_Cop "Rear LH seat Folding State information";
BA_ "SystemSignalLongSymbol" SG_ 187 RLPSU_Folding_State_Popup_EC_Cop "RLPSU_Folding_State_Popup_EC_Copy_0";
BA_ "Version" SG_ 187 RRPSU_Folding_State_Popup_EC_Cop "23.07.05";
BA_ "UserSigValidity" SG_ 187 RRPSU_Folding_State_Popup_EC_Cop 0;
BA_ "GenSigSendType" SG_ 187 RRPSU_Folding_State_Popup_EC_Cop 4;
BA_ "Description" SG_ 187 RRPSU_Folding_State_Popup_EC_Cop "Rear RH seat Folding State information";
BA_ "SystemSignalLongSymbol" SG_ 187 RRPSU_Folding_State_Popup_EC_Cop "RRPSU_Folding_State_Popup_EC_Copy_0";
BA_ "Version" SG_ 187 C_LH_Folding_State_PopUp_Copy_0 "22.11.00";
BA_ "NetworkRequestHoldingTime" SG_ 187 C_LH_Folding_State_PopUp_Copy_0 5000;
BA_ "NetworkRequest" SG_ 187 C_LH_Folding_State_PopUp_Copy_0 0;
BA_ "UserSigValidity" SG_ 187 C_LH_Folding_State_PopUp_Copy_0 0;
BA_ "GenSigSendType" SG_ 187 C_LH_Folding_State_PopUp_Copy_0 4;
BA_ "Description" SG_ 187 C_LH_Folding_State_PopUp_Copy_0 "3rd LH seat Moving Finish / Mode-Fail signal";
BA_ "Version" SG_ 187 C_RH_Folding_State_PopUp_Copy_0 "22.11.00";
BA_ "NetworkRequestHoldingTime" SG_ 187 C_RH_Folding_State_PopUp_Copy_0 5000;
BA_ "NetworkRequest" SG_ 187 C_RH_Folding_State_PopUp_Copy_0 0;
BA_ "UserSigValidity" SG_ 187 C_RH_Folding_State_PopUp_Copy_0 0;
BA_ "GenSigSendType" SG_ 187 C_RH_Folding_State_PopUp_Copy_0 4;
BA_ "Description" SG_ 187 C_RH_Folding_State_PopUp_Copy_0 "3rd RH seat Moving Finish / Mode-Fail signal";
BA_ "Version" SG_ 187 C_RH_Folding_State_PopUp_2_Copy_ "22.11.14";
BA_ "NetworkRequestHoldingTime" SG_ 187 C_RH_Folding_State_PopUp_2_Copy_ 5000;
BA_ "NetworkRequest" SG_ 187 C_RH_Folding_State_PopUp_2_Copy_ 0;
BA_ "UserSigValidity" SG_ 187 C_RH_Folding_State_PopUp_2_Copy_ 0;
BA_ "GenSigSendType" SG_ 187 C_RH_Folding_State_PopUp_2_Copy_ 4;
BA_ "Description" SG_ 187 C_RH_Folding_State_PopUp_2_Copy_ "AVNT OSD PopUp For 3rd Seat Inoperable condition";
BA_ "SystemSignalLongSymbol" SG_ 187 C_RH_Folding_State_PopUp_2_Copy_ "C_RH_Folding_State_PopUp_2_Copy_0";
BA_ "Version" SG_ 187 BDC_FD_AlvCnt1Val "22.11.04";
BA_ "UserSigValidity" SG_ 187 BDC_FD_AlvCnt1Val 0;
BA_ "GenSigSendType" SG_ 187 BDC_FD_AlvCnt1Val 4;
BA_ "Description" SG_ 187 BDC_FD_AlvCnt1Val "For the first transmission request for a data element the counter shall be initialized with 0 and shall be incremented by 1 for every subsequent send request. 

When the counter reaches the maximum value(0xFF), then it shall restart with 0 for the next s";
BA_ "Version" SG_ 187 C_LH_Folding_State_PopUp_2_Copy_ "22.11.14";
BA_ "NetworkRequestHoldingTime" SG_ 187 C_LH_Folding_State_PopUp_2_Copy_ 5000;
BA_ "NetworkRequest" SG_ 187 C_LH_Folding_State_PopUp_2_Copy_ 0;
BA_ "UserSigValidity" SG_ 187 C_LH_Folding_State_PopUp_2_Copy_ 0;
BA_ "GenSigSendType" SG_ 187 C_LH_Folding_State_PopUp_2_Copy_ 4;
BA_ "Description" SG_ 187 C_LH_Folding_State_PopUp_2_Copy_ "AVNT OSD PopUp For 3rd Seat Inoperable condition";
BA_ "SystemSignalLongSymbol" SG_ 187 C_LH_Folding_State_PopUp_2_Copy_ "C_LH_Folding_State_PopUp_2_Copy_0";
BA_ "Version" SG_ 187 Swivel_UtilModeSetReq "23.10.11";
BA_ "NetworkRequestHoldingTime" SG_ 187 Swivel_UtilModeSetReq 5000;
BA_ "NetworkRequest" SG_ 187 Swivel_UtilModeSetReq 0;
BA_ "UserSigValidity" SG_ 187 Swivel_UtilModeSetReq 0;
BA_ "GenSigSendType" SG_ 187 Swivel_UtilModeSetReq 4;
BA_ "Description" SG_ 187 Swivel_UtilModeSetReq "Utility Mode Set Request for Swivel Seat";
BA_ "Version" SG_ 187 PSeat_SecondRLTiltWalkInDisReq "24.01.10";
BA_ "NetworkRequestHoldingTime" SG_ 187 PSeat_SecondRLTiltWalkInDisReq 5000;
BA_ "NetworkRequest" SG_ 187 PSeat_SecondRLTiltWalkInDisReq 0;
BA_ "UserSigValidity" SG_ 187 PSeat_SecondRLTiltWalkInDisReq 0;
BA_ "GenSigSendType" SG_ 187 PSeat_SecondRLTiltWalkInDisReq 4;
BA_ "Description" SG_ 187 PSeat_SecondRLTiltWalkInDisReq "Second RL Seat TiltUp Walkin Unlocking Display Request";
BA_ "Version" SG_ 187 PSeat_SecondRRTiltWalkInDisReq "24.02.00";
BA_ "NetworkRequestHoldingTime" SG_ 187 PSeat_SecondRRTiltWalkInDisReq 5000;
BA_ "NetworkRequest" SG_ 187 PSeat_SecondRRTiltWalkInDisReq 0;
BA_ "UserSigValidity" SG_ 187 PSeat_SecondRRTiltWalkInDisReq 0;
BA_ "GenSigSendType" SG_ 187 PSeat_SecondRRTiltWalkInDisReq 4;
BA_ "Description" SG_ 187 PSeat_SecondRRTiltWalkInDisReq "Second RR Seat TiltUp Walkin Unlocking Display Request";
BA_ "Version" SG_ 187 PSeat_DrvLegrestOSDDisReq "24.01.10";
BA_ "NetworkRequestHoldingTime" SG_ 187 PSeat_DrvLegrestOSDDisReq 5000;
BA_ "NetworkRequest" SG_ 187 PSeat_DrvLegrestOSDDisReq 0;
BA_ "UserSigValidity" SG_ 187 PSeat_DrvLegrestOSDDisReq 0;
BA_ "GenSigSendType" SG_ 187 PSeat_DrvLegrestOSDDisReq 4;
BA_ "Description" SG_ 187 PSeat_DrvLegrestOSDDisReq "Driver Seat Legrest OSD Display Request";
BA_ "Version" SG_ 187 PHEV_FuelDrWakeupSta_Copy_0 "24.04.01";
BA_ "NetworkRequestHoldingTime" SG_ 187 PHEV_FuelDrWakeupSta_Copy_0 5000;
BA_ "NetworkRequest" SG_ 187 PHEV_FuelDrWakeupSta_Copy_0 0;
BA_ "UserSigValidity" SG_ 187 PHEV_FuelDrWakeupSta_Copy_0 0;
BA_ "GenSigSendType" SG_ 187 PHEV_FuelDrWakeupSta_Copy_0 4;
BA_ "Description" SG_ 187 PHEV_FuelDrWakeupSta_Copy_0 "This signal is transmitted when fuel door release switch is pressd in PHEV or HEV vehicle with NIRCOS";
BA_ "Version" SG_ 187 MoodLamp_MLSingleBrghtModCmd "23.04.04";
BA_ "NetworkRequestHoldingTime" SG_ 187 MoodLamp_MLSingleBrghtModCmd 5000;
BA_ "NetworkRequest" SG_ 187 MoodLamp_MLSingleBrghtModCmd 0;
BA_ "UserSigValidity" SG_ 187 MoodLamp_MLSingleBrghtModCmd 0;
BA_ "GenSigSendType" SG_ 187 MoodLamp_MLSingleBrghtModCmd 4;
BA_ "Description" SG_ 187 MoodLamp_MLSingleBrghtModCmd "Single Mood Lamp Bright Mode Command";
BA_ "Version" SG_ 187 MoodLamp_SingleBrghtVal "23.04.04";
BA_ "NetworkRequestHoldingTime" SG_ 187 MoodLamp_SingleBrghtVal 5000;
BA_ "NetworkRequest" SG_ 187 MoodLamp_SingleBrghtVal 0;
BA_ "UserSigValidity" SG_ 187 MoodLamp_SingleBrghtVal 0;
BA_ "GenSigSendType" SG_ 187 MoodLamp_SingleBrghtVal 4;
BA_ "Description" SG_ 187 MoodLamp_SingleBrghtVal "Single Mood Lamp Brightness Value";
BA_ "Version" SG_ 187 PSeat_AstReturnMemoryCmd "23.04.04";
BA_ "NetworkRequestHoldingTime" SG_ 187 PSeat_AstReturnMemoryCmd 5000;
BA_ "NetworkRequest" SG_ 187 PSeat_AstReturnMemoryCmd 0;
BA_ "UserSigValidity" SG_ 187 PSeat_AstReturnMemoryCmd 0;
BA_ "GenSigSendType" SG_ 187 PSeat_AstReturnMemoryCmd 4;
BA_ "Description" SG_ 187 PSeat_AstReturnMemoryCmd "PowerSeat_AstReturnMemoryCmd";
BA_ "Version" SG_ 187 Swivel_AVNPlayConfirmReq "23.10.03";
BA_ "NetworkRequestHoldingTime" SG_ 187 Swivel_AVNPlayConfirmReq 5000;
BA_ "NetworkRequest" SG_ 187 Swivel_AVNPlayConfirmReq 0;
BA_ "UserSigValidity" SG_ 187 Swivel_AVNPlayConfirmReq 0;
BA_ "GenSigSendType" SG_ 187 Swivel_AVNPlayConfirmReq 4;
BA_ "Description" SG_ 187 Swivel_AVNPlayConfirmReq "AVN Swivel Play User Confirm Request";
BA_ "Version" SG_ 187 Swivel_AVNDrvPopUpDisReq "23.10.03";
BA_ "NetworkRequestHoldingTime" SG_ 187 Swivel_AVNDrvPopUpDisReq 5000;
BA_ "NetworkRequest" SG_ 187 Swivel_AVNDrvPopUpDisReq 0;
BA_ "UserSigValidity" SG_ 187 Swivel_AVNDrvPopUpDisReq 0;
BA_ "GenSigSendType" SG_ 187 Swivel_AVNDrvPopUpDisReq 4;
BA_ "Description" SG_ 187 Swivel_AVNDrvPopUpDisReq "Driver Seat Swivel AVN PopUp Display Request";
BA_ "Version" SG_ 187 Swivel_AVNAstPopUpDisReq "23.10.03";
BA_ "NetworkRequestHoldingTime" SG_ 187 Swivel_AVNAstPopUpDisReq 5000;
BA_ "NetworkRequest" SG_ 187 Swivel_AVNAstPopUpDisReq 0;
BA_ "UserSigValidity" SG_ 187 Swivel_AVNAstPopUpDisReq 0;
BA_ "GenSigSendType" SG_ 187 Swivel_AVNAstPopUpDisReq 4;
BA_ "Description" SG_ 187 Swivel_AVNAstPopUpDisReq "Assist Seat Swivel AVN PopUp Display Request";
BA_ "Version" SG_ 187 Swivel_AVNDrvOSDDisReq "23.10.03";
BA_ "NetworkRequestHoldingTime" SG_ 187 Swivel_AVNDrvOSDDisReq 5000;
BA_ "NetworkRequest" SG_ 187 Swivel_AVNDrvOSDDisReq 0;
BA_ "UserSigValidity" SG_ 187 Swivel_AVNDrvOSDDisReq 0;
BA_ "GenSigSendType" SG_ 187 Swivel_AVNDrvOSDDisReq 4;
BA_ "Description" SG_ 187 Swivel_AVNDrvOSDDisReq "Driver Seat Swivel AVN OSD Display Request";
BA_ "Version" SG_ 187 Swivel_AVNAstOSDDisReq "23.10.03";
BA_ "NetworkRequestHoldingTime" SG_ 187 Swivel_AVNAstOSDDisReq 5000;
BA_ "NetworkRequest" SG_ 187 Swivel_AVNAstOSDDisReq 0;
BA_ "UserSigValidity" SG_ 187 Swivel_AVNAstOSDDisReq 0;
BA_ "GenSigSendType" SG_ 187 Swivel_AVNAstOSDDisReq 4;
BA_ "Description" SG_ 187 Swivel_AVNAstOSDDisReq "Assist Seat Swivel AVN OSD Display Request";
BA_ "Version" SG_ 187 Swivel_CTSPlayConfirmReq "23.10.03";
BA_ "NetworkRequestHoldingTime" SG_ 187 Swivel_CTSPlayConfirmReq 5000;
BA_ "NetworkRequest" SG_ 187 Swivel_CTSPlayConfirmReq 0;
BA_ "UserSigValidity" SG_ 187 Swivel_CTSPlayConfirmReq 0;
BA_ "GenSigSendType" SG_ 187 Swivel_CTSPlayConfirmReq 4;
BA_ "Description" SG_ 187 Swivel_CTSPlayConfirmReq "Swivel_CTSDrvPlayConfirmReq";
BA_ "Version" SG_ 187 Swivel_CTSDrvPopUpDisReq "23.10.03";
BA_ "NetworkRequestHoldingTime" SG_ 187 Swivel_CTSDrvPopUpDisReq 5000;
BA_ "NetworkRequest" SG_ 187 Swivel_CTSDrvPopUpDisReq 0;
BA_ "UserSigValidity" SG_ 187 Swivel_CTSDrvPopUpDisReq 0;
BA_ "GenSigSendType" SG_ 187 Swivel_CTSDrvPopUpDisReq 4;
BA_ "Description" SG_ 187 Swivel_CTSDrvPopUpDisReq "Driver Seat Swivel CTS PopUp Display Request";
BA_ "Version" SG_ 187 Swivel_CTSAstPopUpDisReq "23.10.03";
BA_ "NetworkRequestHoldingTime" SG_ 187 Swivel_CTSAstPopUpDisReq 5000;
BA_ "NetworkRequest" SG_ 187 Swivel_CTSAstPopUpDisReq 0;
BA_ "UserSigValidity" SG_ 187 Swivel_CTSAstPopUpDisReq 0;
BA_ "GenSigSendType" SG_ 187 Swivel_CTSAstPopUpDisReq 4;
BA_ "Description" SG_ 187 Swivel_CTSAstPopUpDisReq "Assist Seat Swivel CTS PopUp Display Request";
BA_ "Version" SG_ 187 Swivel_CTSDrvOSDDisReq "23.10.03";
BA_ "NetworkRequestHoldingTime" SG_ 187 Swivel_CTSDrvOSDDisReq 5000;
BA_ "NetworkRequest" SG_ 187 Swivel_CTSDrvOSDDisReq 0;
BA_ "UserSigValidity" SG_ 187 Swivel_CTSDrvOSDDisReq 0;
BA_ "GenSigSendType" SG_ 187 Swivel_CTSDrvOSDDisReq 4;
BA_ "Description" SG_ 187 Swivel_CTSDrvOSDDisReq "Driver Seat Swivel CTS OSD Display Request";
BA_ "Version" SG_ 187 Swivel_CTSAstOSDDisReq "23.10.03";
BA_ "NetworkRequestHoldingTime" SG_ 187 Swivel_CTSAstOSDDisReq 5000;
BA_ "NetworkRequest" SG_ 187 Swivel_CTSAstOSDDisReq 0;
BA_ "UserSigValidity" SG_ 187 Swivel_CTSAstOSDDisReq 0;
BA_ "GenSigSendType" SG_ 187 Swivel_CTSAstOSDDisReq 4;
BA_ "Description" SG_ 187 Swivel_CTSAstOSDDisReq "Swivel_CTSAstOSDDisReq";
BA_ "Version" SG_ 187 PSeat_AllFoldUnfoldOSDDisReq "23.10.04";
BA_ "NetworkRequestHoldingTime" SG_ 187 PSeat_AllFoldUnfoldOSDDisReq 5000;
BA_ "NetworkRequest" SG_ 187 PSeat_AllFoldUnfoldOSDDisReq 0;
BA_ "UserSigValidity" SG_ 187 PSeat_AllFoldUnfoldOSDDisReq 0;
BA_ "GenSigSendType" SG_ 187 PSeat_AllFoldUnfoldOSDDisReq 4;
BA_ "Description" SG_ 187 PSeat_AllFoldUnfoldOSDDisReq "All Fold Unfold OSD Display Request to AVN";
BA_ "Version" SG_ 187 DrvIMS_MemorySetEnaSta_Copy_0 "22.11.00";
BA_ "NetworkRequestHoldingTime" SG_ 187 DrvIMS_MemorySetEnaSta_Copy_0 5000;
BA_ "NetworkRequest" SG_ 187 DrvIMS_MemorySetEnaSta_Copy_0 0;
BA_ "UserSigValidity" SG_ 187 DrvIMS_MemorySetEnaSta_Copy_0 0;
BA_ "GenSigSendType" SG_ 187 DrvIMS_MemorySetEnaSta_Copy_0 4;
BA_ "Description" SG_ 187 DrvIMS_MemorySetEnaSta_Copy_0 "-(Old)C_MEMENB";
BA_ "Version" SG_ 187 C_LH_Folding_State_PopUp_CTS "24.04.07";
BA_ "NetworkRequestHoldingTime" SG_ 187 C_LH_Folding_State_PopUp_CTS 5000;
BA_ "NetworkRequest" SG_ 187 C_LH_Folding_State_PopUp_CTS 0;
BA_ "UserSigValidity" SG_ 187 C_LH_Folding_State_PopUp_CTS 0;
BA_ "GenSigSendType" SG_ 187 C_LH_Folding_State_PopUp_CTS 4;
BA_ "Description" SG_ 187 C_LH_Folding_State_PopUp_CTS "3rd LH seat Moving Finish / Mode-Fail signal";
BA_ "Version" SG_ 187 C_LH_Folding_State_PopUp_2_CTS "24.04.07";
BA_ "NetworkRequestHoldingTime" SG_ 187 C_LH_Folding_State_PopUp_2_CTS 5000;
BA_ "NetworkRequest" SG_ 187 C_LH_Folding_State_PopUp_2_CTS 0;
BA_ "UserSigValidity" SG_ 187 C_LH_Folding_State_PopUp_2_CTS 0;
BA_ "GenSigSendType" SG_ 187 C_LH_Folding_State_PopUp_2_CTS 4;
BA_ "Description" SG_ 187 C_LH_Folding_State_PopUp_2_CTS "CTS OSD PopUp For 3rd Seat Inoperable condition";
BA_ "Version" SG_ 187 PHEV_FuelDrReleaseSwSta_Copy_0 "23.10.01";
BA_ "NetworkRequestHoldingTime" SG_ 187 PHEV_FuelDrReleaseSwSta_Copy_0 5000;
BA_ "NetworkRequest" SG_ 187 PHEV_FuelDrReleaseSwSta_Copy_0 0;
BA_ "UserSigValidity" SG_ 187 PHEV_FuelDrReleaseSwSta_Copy_0 0;
BA_ "GenSigSendType" SG_ 187 PHEV_FuelDrReleaseSwSta_Copy_0 4;
BA_ "Description" SG_ 187 PHEV_FuelDrReleaseSwSta_Copy_0 "PHEV Fuel Filler Door Release SW State

- BDC transmits 0x1 value when the circuit (h/wire) between switch and BDC is connected. If it is not connected (e.g., FCS applied), BDC always transmits 0x0 default value.";
BA_ "Version" SG_ 187 C_RH_Folding_State_PopUp_CTS "24.04.07";
BA_ "NetworkRequestHoldingTime" SG_ 187 C_RH_Folding_State_PopUp_CTS 5000;
BA_ "NetworkRequest" SG_ 187 C_RH_Folding_State_PopUp_CTS 0;
BA_ "UserSigValidity" SG_ 187 C_RH_Folding_State_PopUp_CTS 0;
BA_ "GenSigSendType" SG_ 187 C_RH_Folding_State_PopUp_CTS 4;
BA_ "Description" SG_ 187 C_RH_Folding_State_PopUp_CTS "3rd RH seat Moving Finish / Mode-Fail signal for CTS";
BA_ "Version" SG_ 187 C_RH_Folding_State_PopUp_2_CTS "24.04.07";
BA_ "NetworkRequestHoldingTime" SG_ 187 C_RH_Folding_State_PopUp_2_CTS 5000;
BA_ "NetworkRequest" SG_ 187 C_RH_Folding_State_PopUp_2_CTS 0;
BA_ "UserSigValidity" SG_ 187 C_RH_Folding_State_PopUp_2_CTS 0;
BA_ "GenSigSendType" SG_ 187 C_RH_Folding_State_PopUp_2_CTS 4;
BA_ "Description" SG_ 187 C_RH_Folding_State_PopUp_2_CTS "CTS OSD PopUp For 3rd Seat Inoperable condition";
BA_ "Version" SG_ 187 PSeat_AllFoldUnfoldOSDDisReq_CTS "24.04.07";
BA_ "NetworkRequestHoldingTime" SG_ 187 PSeat_AllFoldUnfoldOSDDisReq_CTS 5000;
BA_ "NetworkRequest" SG_ 187 PSeat_AllFoldUnfoldOSDDisReq_CTS 0;
BA_ "UserSigValidity" SG_ 187 PSeat_AllFoldUnfoldOSDDisReq_CTS 0;
BA_ "GenSigSendType" SG_ 187 PSeat_AllFoldUnfoldOSDDisReq_CTS 4;
BA_ "Description" SG_ 187 PSeat_AllFoldUnfoldOSDDisReq_CTS "All Fold Unfold OSD Display Request to CTS";
BA_ "Version" SG_ 187 StrWhlWrmr_MKBDBpReq_Copy_0 "20.08.02";
BA_ "NetworkRequestHoldingTime" SG_ 187 StrWhlWrmr_MKBDBpReq_Copy_0 5000;
BA_ "NetworkRequest" SG_ 187 StrWhlWrmr_MKBDBpReq_Copy_0 0;
BA_ "UserSigValidity" SG_ 187 StrWhlWrmr_MKBDBpReq_Copy_0 0;
BA_ "GenSigSendType" SG_ 187 StrWhlWrmr_MKBDBpReq_Copy_0 4;
BA_ "Description" SG_ 187 StrWhlWrmr_MKBDBpReq_Copy_0 "Steering Wheel Warmer Switch Beep Command";
BA_ "Version" SG_ 187 BckGls_RrGlsHtdMKBDBpReq_Copy_0 "22.05.02";
BA_ "NetworkRequestHoldingTime" SG_ 187 BckGls_RrGlsHtdMKBDBpReq_Copy_0 5000;
BA_ "NetworkRequest" SG_ 187 BckGls_RrGlsHtdMKBDBpReq_Copy_0 0;
BA_ "UserSigValidity" SG_ 187 BckGls_RrGlsHtdMKBDBpReq_Copy_0 0;
BA_ "GenSigSendType" SG_ 187 BckGls_RrGlsHtdMKBDBpReq_Copy_0 4;
BA_ "Description" SG_ 187 BckGls_RrGlsHtdMKBDBpReq_Copy_0 "Rear Glass Heated Switch Beep Request";
BA_ "Version" SG_ 187 Wndshld_FrtGlsHtdMKBDBpReq_Copy_ "22.05.02";
BA_ "NetworkRequestHoldingTime" SG_ 187 Wndshld_FrtGlsHtdMKBDBpReq_Copy_ 5000;
BA_ "NetworkRequest" SG_ 187 Wndshld_FrtGlsHtdMKBDBpReq_Copy_ 0;
BA_ "UserSigValidity" SG_ 187 Wndshld_FrtGlsHtdMKBDBpReq_Copy_ 0;
BA_ "GenSigSendType" SG_ 187 Wndshld_FrtGlsHtdMKBDBpReq_Copy_ 4;
BA_ "Description" SG_ 187 Wndshld_FrtGlsHtdMKBDBpReq_Copy_ "Front Glass Heated Switch Beep Request";
BA_ "SystemSignalLongSymbol" SG_ 187 Wndshld_FrtGlsHtdMKBDBpReq_Copy_ "Wndshld_FrtGlsHtdMKBDBpReq_Copy_0";
BA_ "Version" SG_ 187 BAlarm_AutoLockrReq_Copy_0 "17.12.00";
BA_ "NetworkRequestHoldingTime" SG_ 187 BAlarm_AutoLockrReq_Copy_0 5000;
BA_ "NetworkRequest" SG_ 187 BAlarm_AutoLockrReq_Copy_0 0;
BA_ "UserSigValidity" SG_ 187 BAlarm_AutoLockrReq_Copy_0 0;
BA_ "GenSigSendType" SG_ 187 BAlarm_AutoLockrReq_Copy_0 4;
BA_ "Description" SG_ 187 BAlarm_AutoLockrReq_Copy_0 "-Lock request by Auto Locking

 (BurglarAlarmFunction)";
BA_ "Version" SG_ 187 RLPSU_FailState_PopUp_CTS "24.04.07";
BA_ "UserSigValidity" SG_ 187 RLPSU_FailState_PopUp_CTS 0;
BA_ "GenSigSendType" SG_ 187 RLPSU_FailState_PopUp_CTS 4;
BA_ "Description" SG_ 187 RLPSU_FailState_PopUp_CTS "Rear LH Seat Operating Finish or Operating Disable Information for CTS Display";
BA_ "Version" SG_ 187 RLPSU_Folding_State_Popup_CTS "24.04.07";
BA_ "UserSigValidity" SG_ 187 RLPSU_Folding_State_Popup_CTS 0;
BA_ "GenSigSendType" SG_ 187 RLPSU_Folding_State_Popup_CTS 4;
BA_ "Description" SG_ 187 RLPSU_Folding_State_Popup_CTS "Rear LH seat Folding State information for CTS";
BA_ "Version" SG_ 187 RRPSU_FailState_PopUp_CTS "24.04.07";
BA_ "UserSigValidity" SG_ 187 RRPSU_FailState_PopUp_CTS 0;
BA_ "GenSigSendType" SG_ 187 RRPSU_FailState_PopUp_CTS 4;
BA_ "Description" SG_ 187 RRPSU_FailState_PopUp_CTS "2nd RH Seat Operating Finish or Operating Disable Information for CTS Display";
BA_ "Version" SG_ 187 RRPSU_Folding_State_Popup_CTS "24.04.07";
BA_ "UserSigValidity" SG_ 187 RRPSU_Folding_State_Popup_CTS 0;
BA_ "GenSigSendType" SG_ 187 RRPSU_Folding_State_Popup_CTS 4;
BA_ "Description" SG_ 187 RRPSU_Folding_State_Popup_CTS "Rear RH seat Folding State information for CTS";
BA_ "Version" SG_ 187 DrvIMS_AMPBzrReq_Copy_0 "22.12.04";
BA_ "NetworkRequestHoldingTime" SG_ 187 DrvIMS_AMPBzrReq_Copy_0 5000;
BA_ "NetworkRequest" SG_ 187 DrvIMS_AMPBzrReq_Copy_0 0;
BA_ "UserSigValidity" SG_ 187 DrvIMS_AMPBzrReq_Copy_0 0;
BA_ "GenSigSendType" SG_ 187 DrvIMS_AMPBzrReq_Copy_0 4;
BA_ "Description" SG_ 187 DrvIMS_AMPBzrReq_Copy_0 "SEAT IMS Buzzer Request for AMP";
BA_ "Version" SG_ 187 AstIMS_AMPBzrReq_Copy_0 "22.12.04";
BA_ "NetworkRequestHoldingTime" SG_ 187 AstIMS_AMPBzrReq_Copy_0 5000;
BA_ "NetworkRequest" SG_ 187 AstIMS_AMPBzrReq_Copy_0 0;
BA_ "UserSigValidity" SG_ 187 AstIMS_AMPBzrReq_Copy_0 0;
BA_ "GenSigSendType" SG_ 187 AstIMS_AMPBzrReq_Copy_0 4;
BA_ "Description" SG_ 187 AstIMS_AMPBzrReq_Copy_0 "SEAT IMS Buzzer Request for AMP";
BA_ "Version" SG_ 187 RLIMS_AMPBzrReq_Copy_0 "22.05.02";
BA_ "NetworkRequestHoldingTime" SG_ 187 RLIMS_AMPBzrReq_Copy_0 5000;
BA_ "NetworkRequest" SG_ 187 RLIMS_AMPBzrReq_Copy_0 0;
BA_ "UserSigValidity" SG_ 187 RLIMS_AMPBzrReq_Copy_0 0;
BA_ "GenSigSendType" SG_ 187 RLIMS_AMPBzrReq_Copy_0 4;
BA_ "Description" SG_ 187 RLIMS_AMPBzrReq_Copy_0 "SEAT IMS Buzzer Request for AMP";
BA_ "Version" SG_ 187 RRIMS_AMPBzrReq_Copy_0 "22.05.02";
BA_ "NetworkRequestHoldingTime" SG_ 187 RRIMS_AMPBzrReq_Copy_0 5000;
BA_ "NetworkRequest" SG_ 187 RRIMS_AMPBzrReq_Copy_0 0;
BA_ "UserSigValidity" SG_ 187 RRIMS_AMPBzrReq_Copy_0 0;
BA_ "GenSigSendType" SG_ 187 RRIMS_AMPBzrReq_Copy_0 4;
BA_ "Description" SG_ 187 RRIMS_AMPBzrReq_Copy_0 "SEAT IMS Buzzer Request for AMP";
BA_ "Version" SG_ 187 DrvIMS_BzrReq_Copy_0 "22.11.00";
BA_ "NetworkRequestHoldingTime" SG_ 187 DrvIMS_BzrReq_Copy_0 5000;
BA_ "NetworkRequest" SG_ 187 DrvIMS_BzrReq_Copy_0 0;
BA_ "UserSigValidity" SG_ 187 DrvIMS_BzrReq_Copy_0 0;
BA_ "GenSigSendType" SG_ 187 DrvIMS_BzrReq_Copy_0 4;
BA_ "Description" SG_ 187 DrvIMS_BzrReq_Copy_0 "IMS ║╬┴о└╜└╗ ┼м╖п╜║┼═ ╜║╟╟─┐┐б╝н ├т╖┬╟╧▒т └з╟╤ ╜├▒╫│╬";
BA_ "Version" SG_ 187 DrvIMS_ErrConWmgDis_Copy_0 "22.11.00";
BA_ "NetworkRequestHoldingTime" SG_ 187 DrvIMS_ErrConWmgDis_Copy_0 5000;
BA_ "NetworkRequest" SG_ 187 DrvIMS_ErrConWmgDis_Copy_0 0;
BA_ "UserSigValidity" SG_ 187 DrvIMS_ErrConWmgDis_Copy_0 0;
BA_ "GenSigSendType" SG_ 187 DrvIMS_ErrConWmgDis_Copy_0 4;
BA_ "Description" SG_ 187 DrvIMS_ErrConWmgDis_Copy_0 "IMS ▒т╛я/└ч╗¤ ┴╢░╟ ┐б╖п ├т╖┬ ╜├▒╫│╬";
BA_ "Version" SG_ 187 DrvIMS_MemoryP1Req_Copy_0 "22.11.00";
BA_ "NetworkRequestHoldingTime" SG_ 187 DrvIMS_MemoryP1Req_Copy_0 5000;
BA_ "NetworkRequest" SG_ 187 DrvIMS_MemoryP1Req_Copy_0 0;
BA_ "UserSigValidity" SG_ 187 DrvIMS_MemoryP1Req_Copy_0 0;
BA_ "GenSigSendType" SG_ 187 DrvIMS_MemoryP1Req_Copy_0 4;
BA_ "Description" SG_ 187 DrvIMS_MemoryP1Req_Copy_0 "-(Old)C_MEMP1CMD";
BA_ "Version" SG_ 187 DrvIMS_MemoryP2Req_Copy_0 "22.11.00";
BA_ "NetworkRequestHoldingTime" SG_ 187 DrvIMS_MemoryP2Req_Copy_0 5000;
BA_ "NetworkRequest" SG_ 187 DrvIMS_MemoryP2Req_Copy_0 0;
BA_ "UserSigValidity" SG_ 187 DrvIMS_MemoryP2Req_Copy_0 0;
BA_ "GenSigSendType" SG_ 187 DrvIMS_MemoryP2Req_Copy_0 4;
BA_ "Description" SG_ 187 DrvIMS_MemoryP2Req_Copy_0 "-(Old)C_MEMP2CMD";
BA_ "Version" SG_ 187 DrvIMS_MemoryP3Req_Copy_0 "22.11.00";
BA_ "NetworkRequestHoldingTime" SG_ 187 DrvIMS_MemoryP3Req_Copy_0 5000;
BA_ "NetworkRequest" SG_ 187 DrvIMS_MemoryP3Req_Copy_0 0;
BA_ "UserSigValidity" SG_ 187 DrvIMS_MemoryP3Req_Copy_0 0;
BA_ "GenSigSendType" SG_ 187 DrvIMS_MemoryP3Req_Copy_0 4;
BA_ "Description" SG_ 187 DrvIMS_MemoryP3Req_Copy_0 "Memory IMS3";
BA_ "Version" SG_ 187 DrvIMS_PlyBckP1Req_Copy_0 "22.11.00";
BA_ "NetworkRequestHoldingTime" SG_ 187 DrvIMS_PlyBckP1Req_Copy_0 5000;
BA_ "NetworkRequest" SG_ 187 DrvIMS_PlyBckP1Req_Copy_0 0;
BA_ "UserSigValidity" SG_ 187 DrvIMS_PlyBckP1Req_Copy_0 0;
BA_ "GenSigSendType" SG_ 187 DrvIMS_PlyBckP1Req_Copy_0 4;
BA_ "Version" SG_ 187 DrvIMS_PlyBckP2Req_Copy_0 "22.11.00";
BA_ "NetworkRequestHoldingTime" SG_ 187 DrvIMS_PlyBckP2Req_Copy_0 5000;
BA_ "NetworkRequest" SG_ 187 DrvIMS_PlyBckP2Req_Copy_0 0;
BA_ "UserSigValidity" SG_ 187 DrvIMS_PlyBckP2Req_Copy_0 0;
BA_ "GenSigSendType" SG_ 187 DrvIMS_PlyBckP2Req_Copy_0 4;
BA_ "Version" SG_ 187 DrvIMS_PlyBckP3Req_Copy_0 "22.11.00";
BA_ "NetworkRequestHoldingTime" SG_ 187 DrvIMS_PlyBckP3Req_Copy_0 5000;
BA_ "NetworkRequest" SG_ 187 DrvIMS_PlyBckP3Req_Copy_0 0;
BA_ "UserSigValidity" SG_ 187 DrvIMS_PlyBckP3Req_Copy_0 0;
BA_ "GenSigSendType" SG_ 187 DrvIMS_PlyBckP3Req_Copy_0 4;
BA_ "Description" SG_ 187 DrvIMS_PlyBckP3Req_Copy_0 "PLAY IMS3";
BA_ "Version" SG_ 187 DrvIMS_PlyBckStpReq_Copy_0 "22.11.00";
BA_ "NetworkRequestHoldingTime" SG_ 187 DrvIMS_PlyBckStpReq_Copy_0 5000;
BA_ "NetworkRequest" SG_ 187 DrvIMS_PlyBckStpReq_Copy_0 0;
BA_ "UserSigValidity" SG_ 187 DrvIMS_PlyBckStpReq_Copy_0 0;
BA_ "GenSigSendType" SG_ 187 DrvIMS_PlyBckStpReq_Copy_0 4;
BA_ "Description" SG_ 187 DrvIMS_PlyBckStpReq_Copy_0 "This signal is used to stop during playback";
BA_ "Version" SG_ 187 AVN_SeatPosMemory_Cmd_Copy_0 "20.03.07";
BA_ "UserSigValidity" SG_ 187 AVN_SeatPosMemory_Cmd_Copy_0 0;
BA_ "GenSigSendType" SG_ 187 AVN_SeatPosMemory_Cmd_Copy_0 4;
BA_ "Description" SG_ 187 AVN_SeatPosMemory_Cmd_Copy_0 "The signal indicates the command of rear left seat position memory to AVN.";
BA_ "Version" SG_ 187 AVN_SeatPosPlyBck_Cmd_Copy_0 "20.03.07";
BA_ "UserSigValidity" SG_ 187 AVN_SeatPosPlyBck_Cmd_Copy_0 0;
BA_ "GenSigSendType" SG_ 187 AVN_SeatPosPlyBck_Cmd_Copy_0 4;
BA_ "Description" SG_ 187 AVN_SeatPosPlyBck_Cmd_Copy_0 "The signal indicates the command of rear left seat positon play to AVN.";
BA_ "Version" SG_ 187 SmrtIMS_EnterSwSta_Copy_0 "22.11.00";
BA_ "NetworkRequestHoldingTime" SG_ 187 SmrtIMS_EnterSwSta_Copy_0 5000;
BA_ "NetworkRequest" SG_ 187 SmrtIMS_EnterSwSta_Copy_0 0;
BA_ "UserSigValidity" SG_ 187 SmrtIMS_EnterSwSta_Copy_0 0;
BA_ "GenSigSendType" SG_ 187 SmrtIMS_EnterSwSta_Copy_0 4;
BA_ "Description" SG_ 187 SmrtIMS_EnterSwSta_Copy_0 "-(Old)C_SmartIMSOn";
BA_ "Version" SG_ 187 SmrtIMS_PlyBckReq_Copy_0 "22.11.00";
BA_ "NetworkRequestHoldingTime" SG_ 187 SmrtIMS_PlyBckReq_Copy_0 5000;
BA_ "NetworkRequest" SG_ 187 SmrtIMS_PlyBckReq_Copy_0 0;
BA_ "UserSigValidity" SG_ 187 SmrtIMS_PlyBckReq_Copy_0 0;
BA_ "GenSigSendType" SG_ 187 SmrtIMS_PlyBckReq_Copy_0 4;
BA_ "Description" SG_ 187 SmrtIMS_PlyBckReq_Copy_0 "Signal for Health Care IMS Playback DB Number";
BA_ "Version" SG_ 187 SmrtIMS_PlyBckStpReq_Copy_0 "22.11.00";
BA_ "NetworkRequestHoldingTime" SG_ 187 SmrtIMS_PlyBckStpReq_Copy_0 5000;
BA_ "NetworkRequest" SG_ 187 SmrtIMS_PlyBckStpReq_Copy_0 0;
BA_ "UserSigValidity" SG_ 187 SmrtIMS_PlyBckStpReq_Copy_0 0;
BA_ "GenSigSendType" SG_ 187 SmrtIMS_PlyBckStpReq_Copy_0 4;
BA_ "Description" SG_ 187 SmrtIMS_PlyBckStpReq_Copy_0 "Health Care IMS On/Off Flag";
BA_ "Version" SG_ 187 Drv_AutoRlxWrngDis_Copy_0 "22.11.00";
BA_ "NetworkRequestHoldingTime" SG_ 187 Drv_AutoRlxWrngDis_Copy_0 5000;
BA_ "NetworkRequest" SG_ 187 Drv_AutoRlxWrngDis_Copy_0 0;
BA_ "UserSigValidity" SG_ 187 Drv_AutoRlxWrngDis_Copy_0 1;
BA_ "GenSigSendType" SG_ 187 Drv_AutoRlxWrngDis_Copy_0 4;
BA_ "Version" SG_ 2214592751 UWB_FRNK_Dvp_Data "23.01.02";
BA_ "UserSigValidity" SG_ 2214592751 UWB_FRNK_Dvp_Data 0;
BA_ "GenSigSendType" SG_ 2214592751 UWB_FRNK_Dvp_Data 2;
BA_ "Version" SG_ 2214592738 L_UWB_FRNK_FD_Crc3Val "23.01.02";
BA_ "UserSigValidity" SG_ 2214592738 L_UWB_FRNK_FD_Crc3Val 3;
BA_ "GenSigStartValue" SG_ 2214592738 L_UWB_FRNK_FD_Crc3Val 65535;
BA_ "GenSigSendType" SG_ 2214592738 L_UWB_FRNK_FD_Crc3Val 2;
BA_ "Description" SG_ 2214592738 L_UWB_FRNK_FD_Crc3Val "The data area for CRC calculation is based on the data length (DLC) of the message DB.

The CRC shall be calculated over the entire data block (excluding the CRC bytes) including the user data, alive counter and Data ID



- CRC Polynomial (0x1021) , Ini";
BA_ "Version" SG_ 2214592738 L_UWB_FRNK_FD_AlvCnt3Val "23.01.02";
BA_ "UserSigValidity" SG_ 2214592738 L_UWB_FRNK_FD_AlvCnt3Val 3;
BA_ "GenSigSendType" SG_ 2214592738 L_UWB_FRNK_FD_AlvCnt3Val 2;
BA_ "Description" SG_ 2214592738 L_UWB_FRNK_FD_AlvCnt3Val "For the first transmission request for a data element the counter shall be initialized with 0 and shall be incremented by 1 for every subsequent send request. 

When the counter reaches the maximum value(0xFF), then it shall restart with 0 for the next s";
BA_ "Version" SG_ 2214592738 UWB_FRNK_Ranging_Enc_Result2 "24.04.06";
BA_ "UserSigValidity" SG_ 2214592738 UWB_FRNK_Ranging_Enc_Result2 0;
BA_ "GenSigSendType" SG_ 2214592738 UWB_FRNK_Ranging_Enc_Result2 2;
BA_ "Description" SG_ 2214592738 UWB_FRNK_Ranging_Enc_Result2 "UWB Ranging Result2(Encrypted Data) with DK";
BA_ "Version" SG_ 2214592738 UWB_FRNK_Ranging_Enc_Result "23.01.02";
BA_ "UserSigValidity" SG_ 2214592738 UWB_FRNK_Ranging_Enc_Result 0;
BA_ "GenSigSendType" SG_ 2214592738 UWB_FRNK_Ranging_Enc_Result 2;
BA_ "Version" SG_ 2214592737 L_UWB_FRNK_FD_Crc2Val "23.01.02";
BA_ "UserSigValidity" SG_ 2214592737 L_UWB_FRNK_FD_Crc2Val 3;
BA_ "GenSigStartValue" SG_ 2214592737 L_UWB_FRNK_FD_Crc2Val 65535;
BA_ "GenSigSendType" SG_ 2214592737 L_UWB_FRNK_FD_Crc2Val 4;
BA_ "Description" SG_ 2214592737 L_UWB_FRNK_FD_Crc2Val "The data area for CRC calculation is based on the data length (DLC) of the message DB.

The CRC shall be calculated over the entire data block (excluding the CRC bytes) including the user data, alive counter and Data ID



- CRC Polynomial (0x1021) , Ini";
BA_ "Version" SG_ 2214592737 L_UWB_FRNK_FD_AlvCnt2Val "23.01.02";
BA_ "UserSigValidity" SG_ 2214592737 L_UWB_FRNK_FD_AlvCnt2Val 3;
BA_ "GenSigSendType" SG_ 2214592737 L_UWB_FRNK_FD_AlvCnt2Val 4;
BA_ "Description" SG_ 2214592737 L_UWB_FRNK_FD_AlvCnt2Val "For the first transmission request for a data element the counter shall be initialized with 0 and shall be incremented by 1 for every subsequent send request. 

When the counter reaches the maximum value(0xFF), then it shall restart with 0 for the next s";
BA_ "Version" SG_ 2214592737 UWB_FRNK_FOB_RSD_Enc_Result "23.01.02";
BA_ "UserSigValidity" SG_ 2214592737 UWB_FRNK_FOB_RSD_Enc_Result 0;
BA_ "GenSigSendType" SG_ 2214592737 UWB_FRNK_FOB_RSD_Enc_Result 4;
BA_ "Version" SG_ 2214592736 L_UWB_FRNK_FD_Crc1Val "23.01.02";
BA_ "UserSigValidity" SG_ 2214592736 L_UWB_FRNK_FD_Crc1Val 3;
BA_ "GenSigStartValue" SG_ 2214592736 L_UWB_FRNK_FD_Crc1Val 65535;
BA_ "GenSigSendType" SG_ 2214592736 L_UWB_FRNK_FD_Crc1Val 4;
BA_ "Description" SG_ 2214592736 L_UWB_FRNK_FD_Crc1Val "The data area for CRC calculation is based on the data length (DLC) of the message DB.

The CRC shall be calculated over the entire data block (excluding the CRC bytes) including the user data, alive counter and Data ID



- CRC Polynomial (0x1021) , Ini";
BA_ "Version" SG_ 2214592736 L_UWB_FRNK_FD_AlvCnt1Val "23.01.02";
BA_ "UserSigValidity" SG_ 2214592736 L_UWB_FRNK_FD_AlvCnt1Val 3;
BA_ "GenSigSendType" SG_ 2214592736 L_UWB_FRNK_FD_AlvCnt1Val 4;
BA_ "Description" SG_ 2214592736 L_UWB_FRNK_FD_AlvCnt1Val "For the first transmission request for a data element the counter shall be initialized with 0 and shall be incremented by 1 for every subsequent send request. 

When the counter reaches the maximum value(0xFF), then it shall restart with 0 for the next s";
BA_ "Version" SG_ 2214592736 UWB_FRNK_UWB_Decrypt_FB "23.01.02";
BA_ "UserSigValidity" SG_ 2214592736 UWB_FRNK_UWB_Decrypt_FB 0;
BA_ "GenSigSendType" SG_ 2214592736 UWB_FRNK_UWB_Decrypt_FB 4;
BA_ "Version" SG_ 2214592736 UWB_FRNK_MST_Decrypt_FB "23.01.02";
BA_ "UserSigValidity" SG_ 2214592736 UWB_FRNK_MST_Decrypt_FB 0;
BA_ "GenSigSendType" SG_ 2214592736 UWB_FRNK_MST_Decrypt_FB 4;
BA_ "Version" SG_ 2214592736 UWB_FRNK_OTA_Rsp "24.07.05";
BA_ "UserSigValidity" SG_ 2214592736 UWB_FRNK_OTA_Rsp 0;
BA_ "GenSigSendType" SG_ 2214592736 UWB_FRNK_OTA_Rsp 4;
BA_ "Description" SG_ 2214592736 UWB_FRNK_OTA_Rsp "UWB FRNK OTA response";
BA_ "Version" SG_ 2214592736 UWB_FRNK_UWB_IC_Status "24.04.03";
BA_ "UserSigValidity" SG_ 2214592736 UWB_FRNK_UWB_IC_Status 0;
BA_ "GenSigSendType" SG_ 2214592736 UWB_FRNK_UWB_IC_Status 4;
BA_ "Description" SG_ 2214592736 UWB_FRNK_UWB_IC_Status "UWB IC Status Message";
BA_ "Version" SG_ 2348810509 TP_L_DHRR_FD_BDC_FD_Byte0 "23.06.01";
BA_ "NetworkRequestHoldingTime" SG_ 2348810509 TP_L_DHRR_FD_BDC_FD_Byte0 5000;
BA_ "NetworkRequest" SG_ 2348810509 TP_L_DHRR_FD_BDC_FD_Byte0 0;
BA_ "UserSigValidity" SG_ 2348810509 TP_L_DHRR_FD_BDC_FD_Byte0 0;
BA_ "UsrSigPurpose" SG_ 2348810509 TP_L_DHRR_FD_BDC_FD_Byte0 9;
BA_ "Description" SG_ 2348810509 TP_L_DHRR_FD_BDC_FD_Byte0 "TP Index : 276";
BA_ "Version" SG_ 2348810509 TP_L_DHRR_FD_BDC_FD_Byte13 "23.06.01";
BA_ "NetworkRequestHoldingTime" SG_ 2348810509 TP_L_DHRR_FD_BDC_FD_Byte13 5000;
BA_ "NetworkRequest" SG_ 2348810509 TP_L_DHRR_FD_BDC_FD_Byte13 0;
BA_ "UserSigValidity" SG_ 2348810509 TP_L_DHRR_FD_BDC_FD_Byte13 0;
BA_ "UsrSigPurpose" SG_ 2348810509 TP_L_DHRR_FD_BDC_FD_Byte13 9;
BA_ "Description" SG_ 2348810509 TP_L_DHRR_FD_BDC_FD_Byte13 "TP Index : 276";
BA_ "Version" SG_ 2348810509 TP_L_DHRR_FD_BDC_FD_Byte14 "23.06.01";
BA_ "NetworkRequestHoldingTime" SG_ 2348810509 TP_L_DHRR_FD_BDC_FD_Byte14 5000;
BA_ "NetworkRequest" SG_ 2348810509 TP_L_DHRR_FD_BDC_FD_Byte14 0;
BA_ "UserSigValidity" SG_ 2348810509 TP_L_DHRR_FD_BDC_FD_Byte14 0;
BA_ "UsrSigPurpose" SG_ 2348810509 TP_L_DHRR_FD_BDC_FD_Byte14 9;
BA_ "Description" SG_ 2348810509 TP_L_DHRR_FD_BDC_FD_Byte14 "TP Index : 276";
BA_ "Version" SG_ 2348810509 TP_L_DHRR_FD_BDC_FD_Byte15 "23.06.01";
BA_ "NetworkRequestHoldingTime" SG_ 2348810509 TP_L_DHRR_FD_BDC_FD_Byte15 5000;
BA_ "NetworkRequest" SG_ 2348810509 TP_L_DHRR_FD_BDC_FD_Byte15 0;
BA_ "UserSigValidity" SG_ 2348810509 TP_L_DHRR_FD_BDC_FD_Byte15 0;
BA_ "UsrSigPurpose" SG_ 2348810509 TP_L_DHRR_FD_BDC_FD_Byte15 9;
BA_ "Description" SG_ 2348810509 TP_L_DHRR_FD_BDC_FD_Byte15 "TP Index : 276";
BA_ "Version" SG_ 2348810509 TP_L_DHRR_FD_BDC_FD_Byte16 "23.06.01";
BA_ "NetworkRequestHoldingTime" SG_ 2348810509 TP_L_DHRR_FD_BDC_FD_Byte16 5000;
BA_ "NetworkRequest" SG_ 2348810509 TP_L_DHRR_FD_BDC_FD_Byte16 0;
BA_ "UserSigValidity" SG_ 2348810509 TP_L_DHRR_FD_BDC_FD_Byte16 0;
BA_ "UsrSigPurpose" SG_ 2348810509 TP_L_DHRR_FD_BDC_FD_Byte16 9;
BA_ "Description" SG_ 2348810509 TP_L_DHRR_FD_BDC_FD_Byte16 "TP Index : 276";
BA_ "Version" SG_ 2348810509 TP_L_DHRR_FD_BDC_FD_Byte17 "23.06.01";
BA_ "NetworkRequestHoldingTime" SG_ 2348810509 TP_L_DHRR_FD_BDC_FD_Byte17 5000;
BA_ "NetworkRequest" SG_ 2348810509 TP_L_DHRR_FD_BDC_FD_Byte17 0;
BA_ "UserSigValidity" SG_ 2348810509 TP_L_DHRR_FD_BDC_FD_Byte17 0;
BA_ "UsrSigPurpose" SG_ 2348810509 TP_L_DHRR_FD_BDC_FD_Byte17 9;
BA_ "Description" SG_ 2348810509 TP_L_DHRR_FD_BDC_FD_Byte17 "TP Index : 276";
BA_ "Version" SG_ 2348810509 TP_L_DHRR_FD_BDC_FD_Byte18 "23.06.01";
BA_ "NetworkRequestHoldingTime" SG_ 2348810509 TP_L_DHRR_FD_BDC_FD_Byte18 5000;
BA_ "NetworkRequest" SG_ 2348810509 TP_L_DHRR_FD_BDC_FD_Byte18 0;
BA_ "UserSigValidity" SG_ 2348810509 TP_L_DHRR_FD_BDC_FD_Byte18 0;
BA_ "UsrSigPurpose" SG_ 2348810509 TP_L_DHRR_FD_BDC_FD_Byte18 9;
BA_ "Description" SG_ 2348810509 TP_L_DHRR_FD_BDC_FD_Byte18 "TP Index : 276";
BA_ "Version" SG_ 2348810509 TP_L_DHRR_FD_BDC_FD_Byte19 "23.06.01";
BA_ "NetworkRequestHoldingTime" SG_ 2348810509 TP_L_DHRR_FD_BDC_FD_Byte19 5000;
BA_ "NetworkRequest" SG_ 2348810509 TP_L_DHRR_FD_BDC_FD_Byte19 0;
BA_ "UserSigValidity" SG_ 2348810509 TP_L_DHRR_FD_BDC_FD_Byte19 0;
BA_ "UsrSigPurpose" SG_ 2348810509 TP_L_DHRR_FD_BDC_FD_Byte19 9;
BA_ "Description" SG_ 2348810509 TP_L_DHRR_FD_BDC_FD_Byte19 "TP Index : 276";
BA_ "Version" SG_ 2348810509 TP_L_DHRR_FD_BDC_FD_Byte2 "23.06.01";
BA_ "NetworkRequestHoldingTime" SG_ 2348810509 TP_L_DHRR_FD_BDC_FD_Byte2 5000;
BA_ "NetworkRequest" SG_ 2348810509 TP_L_DHRR_FD_BDC_FD_Byte2 0;
BA_ "UserSigValidity" SG_ 2348810509 TP_L_DHRR_FD_BDC_FD_Byte2 0;
BA_ "UsrSigPurpose" SG_ 2348810509 TP_L_DHRR_FD_BDC_FD_Byte2 9;
BA_ "Description" SG_ 2348810509 TP_L_DHRR_FD_BDC_FD_Byte2 "TP Index : 276";
BA_ "Version" SG_ 2348810509 TP_L_DHRR_FD_BDC_FD_Byte20 "23.06.01";
BA_ "NetworkRequestHoldingTime" SG_ 2348810509 TP_L_DHRR_FD_BDC_FD_Byte20 5000;
BA_ "NetworkRequest" SG_ 2348810509 TP_L_DHRR_FD_BDC_FD_Byte20 0;
BA_ "UserSigValidity" SG_ 2348810509 TP_L_DHRR_FD_BDC_FD_Byte20 0;
BA_ "UsrSigPurpose" SG_ 2348810509 TP_L_DHRR_FD_BDC_FD_Byte20 9;
BA_ "Description" SG_ 2348810509 TP_L_DHRR_FD_BDC_FD_Byte20 "TP Index : 276";
BA_ "Version" SG_ 2348810509 TP_L_DHRR_FD_BDC_FD_Byte21 "23.06.01";
BA_ "NetworkRequestHoldingTime" SG_ 2348810509 TP_L_DHRR_FD_BDC_FD_Byte21 5000;
BA_ "NetworkRequest" SG_ 2348810509 TP_L_DHRR_FD_BDC_FD_Byte21 0;
BA_ "UserSigValidity" SG_ 2348810509 TP_L_DHRR_FD_BDC_FD_Byte21 0;
BA_ "UsrSigPurpose" SG_ 2348810509 TP_L_DHRR_FD_BDC_FD_Byte21 9;
BA_ "Description" SG_ 2348810509 TP_L_DHRR_FD_BDC_FD_Byte21 "TP Index : 276";
BA_ "Version" SG_ 2348810509 TP_L_DHRR_FD_BDC_FD_Byte22 "23.06.01";
BA_ "NetworkRequestHoldingTime" SG_ 2348810509 TP_L_DHRR_FD_BDC_FD_Byte22 5000;
BA_ "NetworkRequest" SG_ 2348810509 TP_L_DHRR_FD_BDC_FD_Byte22 0;
BA_ "UserSigValidity" SG_ 2348810509 TP_L_DHRR_FD_BDC_FD_Byte22 0;
BA_ "UsrSigPurpose" SG_ 2348810509 TP_L_DHRR_FD_BDC_FD_Byte22 9;
BA_ "Description" SG_ 2348810509 TP_L_DHRR_FD_BDC_FD_Byte22 "TP Index : 276";
BA_ "Version" SG_ 2348810509 TP_L_DHRR_FD_BDC_FD_Byte23 "23.06.01";
BA_ "NetworkRequestHoldingTime" SG_ 2348810509 TP_L_DHRR_FD_BDC_FD_Byte23 5000;
BA_ "NetworkRequest" SG_ 2348810509 TP_L_DHRR_FD_BDC_FD_Byte23 0;
BA_ "UserSigValidity" SG_ 2348810509 TP_L_DHRR_FD_BDC_FD_Byte23 0;
BA_ "UsrSigPurpose" SG_ 2348810509 TP_L_DHRR_FD_BDC_FD_Byte23 9;
BA_ "Description" SG_ 2348810509 TP_L_DHRR_FD_BDC_FD_Byte23 "TP Index : 276";
BA_ "Version" SG_ 2348810509 TP_L_DHRR_FD_BDC_FD_Byte24 "23.06.01";
BA_ "NetworkRequestHoldingTime" SG_ 2348810509 TP_L_DHRR_FD_BDC_FD_Byte24 5000;
BA_ "NetworkRequest" SG_ 2348810509 TP_L_DHRR_FD_BDC_FD_Byte24 0;
BA_ "UserSigValidity" SG_ 2348810509 TP_L_DHRR_FD_BDC_FD_Byte24 0;
BA_ "UsrSigPurpose" SG_ 2348810509 TP_L_DHRR_FD_BDC_FD_Byte24 9;
BA_ "Description" SG_ 2348810509 TP_L_DHRR_FD_BDC_FD_Byte24 "TP Index : 276";
BA_ "Version" SG_ 2348810509 TP_L_DHRR_FD_BDC_FD_Byte25 "23.06.01";
BA_ "NetworkRequestHoldingTime" SG_ 2348810509 TP_L_DHRR_FD_BDC_FD_Byte25 5000;
BA_ "NetworkRequest" SG_ 2348810509 TP_L_DHRR_FD_BDC_FD_Byte25 0;
BA_ "UserSigValidity" SG_ 2348810509 TP_L_DHRR_FD_BDC_FD_Byte25 0;
BA_ "UsrSigPurpose" SG_ 2348810509 TP_L_DHRR_FD_BDC_FD_Byte25 9;
BA_ "Description" SG_ 2348810509 TP_L_DHRR_FD_BDC_FD_Byte25 "TP Index : 276";
BA_ "Version" SG_ 2348810509 TP_L_DHRR_FD_BDC_FD_Byte26 "23.06.01";
BA_ "NetworkRequestHoldingTime" SG_ 2348810509 TP_L_DHRR_FD_BDC_FD_Byte26 5000;
BA_ "NetworkRequest" SG_ 2348810509 TP_L_DHRR_FD_BDC_FD_Byte26 0;
BA_ "UserSigValidity" SG_ 2348810509 TP_L_DHRR_FD_BDC_FD_Byte26 0;
BA_ "UsrSigPurpose" SG_ 2348810509 TP_L_DHRR_FD_BDC_FD_Byte26 9;
BA_ "Description" SG_ 2348810509 TP_L_DHRR_FD_BDC_FD_Byte26 "TP Index : 276";
BA_ "Version" SG_ 2348810509 TP_L_DHRR_FD_BDC_FD_Byte27 "23.06.01";
BA_ "NetworkRequestHoldingTime" SG_ 2348810509 TP_L_DHRR_FD_BDC_FD_Byte27 5000;
BA_ "NetworkRequest" SG_ 2348810509 TP_L_DHRR_FD_BDC_FD_Byte27 0;
BA_ "UserSigValidity" SG_ 2348810509 TP_L_DHRR_FD_BDC_FD_Byte27 0;
BA_ "UsrSigPurpose" SG_ 2348810509 TP_L_DHRR_FD_BDC_FD_Byte27 9;
BA_ "Description" SG_ 2348810509 TP_L_DHRR_FD_BDC_FD_Byte27 "TP Index : 276";
BA_ "Version" SG_ 2348810509 TP_L_DHRR_FD_BDC_FD_Byte28 "23.06.01";
BA_ "NetworkRequestHoldingTime" SG_ 2348810509 TP_L_DHRR_FD_BDC_FD_Byte28 5000;
BA_ "NetworkRequest" SG_ 2348810509 TP_L_DHRR_FD_BDC_FD_Byte28 0;
BA_ "UserSigValidity" SG_ 2348810509 TP_L_DHRR_FD_BDC_FD_Byte28 0;
BA_ "UsrSigPurpose" SG_ 2348810509 TP_L_DHRR_FD_BDC_FD_Byte28 9;
BA_ "Description" SG_ 2348810509 TP_L_DHRR_FD_BDC_FD_Byte28 "TP Index : 276";
BA_ "Version" SG_ 2348810509 TP_L_DHRR_FD_BDC_FD_Byte29 "23.06.01";
BA_ "NetworkRequestHoldingTime" SG_ 2348810509 TP_L_DHRR_FD_BDC_FD_Byte29 5000;
BA_ "NetworkRequest" SG_ 2348810509 TP_L_DHRR_FD_BDC_FD_Byte29 0;
BA_ "UserSigValidity" SG_ 2348810509 TP_L_DHRR_FD_BDC_FD_Byte29 0;
BA_ "UsrSigPurpose" SG_ 2348810509 TP_L_DHRR_FD_BDC_FD_Byte29 9;
BA_ "Description" SG_ 2348810509 TP_L_DHRR_FD_BDC_FD_Byte29 "TP Index : 276";
BA_ "Version" SG_ 2348810509 TP_L_DHRR_FD_BDC_FD_Byte3 "23.06.01";
BA_ "NetworkRequestHoldingTime" SG_ 2348810509 TP_L_DHRR_FD_BDC_FD_Byte3 5000;
BA_ "NetworkRequest" SG_ 2348810509 TP_L_DHRR_FD_BDC_FD_Byte3 0;
BA_ "UserSigValidity" SG_ 2348810509 TP_L_DHRR_FD_BDC_FD_Byte3 0;
BA_ "UsrSigPurpose" SG_ 2348810509 TP_L_DHRR_FD_BDC_FD_Byte3 9;
BA_ "Description" SG_ 2348810509 TP_L_DHRR_FD_BDC_FD_Byte3 "TP Index : 276";
BA_ "Version" SG_ 2348810509 TP_L_DHRR_FD_BDC_FD_Byte30 "23.06.01";
BA_ "NetworkRequestHoldingTime" SG_ 2348810509 TP_L_DHRR_FD_BDC_FD_Byte30 5000;
BA_ "NetworkRequest" SG_ 2348810509 TP_L_DHRR_FD_BDC_FD_Byte30 0;
BA_ "UserSigValidity" SG_ 2348810509 TP_L_DHRR_FD_BDC_FD_Byte30 0;
BA_ "UsrSigPurpose" SG_ 2348810509 TP_L_DHRR_FD_BDC_FD_Byte30 9;
BA_ "Description" SG_ 2348810509 TP_L_DHRR_FD_BDC_FD_Byte30 "TP Index : 276";
BA_ "Version" SG_ 2348810509 TP_L_DHRR_FD_BDC_FD_Byte31 "23.06.01";
BA_ "NetworkRequestHoldingTime" SG_ 2348810509 TP_L_DHRR_FD_BDC_FD_Byte31 5000;
BA_ "NetworkRequest" SG_ 2348810509 TP_L_DHRR_FD_BDC_FD_Byte31 0;
BA_ "UserSigValidity" SG_ 2348810509 TP_L_DHRR_FD_BDC_FD_Byte31 0;
BA_ "UsrSigPurpose" SG_ 2348810509 TP_L_DHRR_FD_BDC_FD_Byte31 9;
BA_ "Description" SG_ 2348810509 TP_L_DHRR_FD_BDC_FD_Byte31 "TP Index : 276";
BA_ "Version" SG_ 2348810509 TP_L_DHRR_FD_BDC_FD_Byte4 "23.06.01";
BA_ "NetworkRequestHoldingTime" SG_ 2348810509 TP_L_DHRR_FD_BDC_FD_Byte4 5000;
BA_ "NetworkRequest" SG_ 2348810509 TP_L_DHRR_FD_BDC_FD_Byte4 0;
BA_ "UserSigValidity" SG_ 2348810509 TP_L_DHRR_FD_BDC_FD_Byte4 0;
BA_ "UsrSigPurpose" SG_ 2348810509 TP_L_DHRR_FD_BDC_FD_Byte4 9;
BA_ "Description" SG_ 2348810509 TP_L_DHRR_FD_BDC_FD_Byte4 "TP Index : 276";
BA_ "Version" SG_ 2348810509 TP_L_DHRR_FD_BDC_FD_Byte5 "23.06.01";
BA_ "NetworkRequestHoldingTime" SG_ 2348810509 TP_L_DHRR_FD_BDC_FD_Byte5 5000;
BA_ "NetworkRequest" SG_ 2348810509 TP_L_DHRR_FD_BDC_FD_Byte5 0;
BA_ "UserSigValidity" SG_ 2348810509 TP_L_DHRR_FD_BDC_FD_Byte5 0;
BA_ "UsrSigPurpose" SG_ 2348810509 TP_L_DHRR_FD_BDC_FD_Byte5 9;
BA_ "Description" SG_ 2348810509 TP_L_DHRR_FD_BDC_FD_Byte5 "TP Index : 276";
BA_ "Version" SG_ 2348810509 TP_L_DHRR_FD_BDC_FD_Byte6 "23.06.01";
BA_ "NetworkRequestHoldingTime" SG_ 2348810509 TP_L_DHRR_FD_BDC_FD_Byte6 5000;
BA_ "NetworkRequest" SG_ 2348810509 TP_L_DHRR_FD_BDC_FD_Byte6 0;
BA_ "UserSigValidity" SG_ 2348810509 TP_L_DHRR_FD_BDC_FD_Byte6 0;
BA_ "UsrSigPurpose" SG_ 2348810509 TP_L_DHRR_FD_BDC_FD_Byte6 9;
BA_ "Description" SG_ 2348810509 TP_L_DHRR_FD_BDC_FD_Byte6 "TP Index : 276";
BA_ "Version" SG_ 2348810509 TP_L_DHRR_FD_BDC_FD_Byte7 "23.06.01";
BA_ "NetworkRequestHoldingTime" SG_ 2348810509 TP_L_DHRR_FD_BDC_FD_Byte7 5000;
BA_ "NetworkRequest" SG_ 2348810509 TP_L_DHRR_FD_BDC_FD_Byte7 0;
BA_ "UserSigValidity" SG_ 2348810509 TP_L_DHRR_FD_BDC_FD_Byte7 0;
BA_ "UsrSigPurpose" SG_ 2348810509 TP_L_DHRR_FD_BDC_FD_Byte7 9;
BA_ "Description" SG_ 2348810509 TP_L_DHRR_FD_BDC_FD_Byte7 "TP Index : 276";
BA_ "Version" SG_ 2348810509 TP_L_DHRR_FD_BDC_FD_Byte8 "23.06.01";
BA_ "NetworkRequestHoldingTime" SG_ 2348810509 TP_L_DHRR_FD_BDC_FD_Byte8 5000;
BA_ "NetworkRequest" SG_ 2348810509 TP_L_DHRR_FD_BDC_FD_Byte8 0;
BA_ "UserSigValidity" SG_ 2348810509 TP_L_DHRR_FD_BDC_FD_Byte8 0;
BA_ "UsrSigPurpose" SG_ 2348810509 TP_L_DHRR_FD_BDC_FD_Byte8 9;
BA_ "Description" SG_ 2348810509 TP_L_DHRR_FD_BDC_FD_Byte8 "TP Index : 276";
BA_ "Version" SG_ 2348810509 TP_L_DHRR_FD_BDC_FD_Byte9 "23.06.01";
BA_ "NetworkRequestHoldingTime" SG_ 2348810509 TP_L_DHRR_FD_BDC_FD_Byte9 5000;
BA_ "NetworkRequest" SG_ 2348810509 TP_L_DHRR_FD_BDC_FD_Byte9 0;
BA_ "UserSigValidity" SG_ 2348810509 TP_L_DHRR_FD_BDC_FD_Byte9 0;
BA_ "UsrSigPurpose" SG_ 2348810509 TP_L_DHRR_FD_BDC_FD_Byte9 9;
BA_ "Description" SG_ 2348810509 TP_L_DHRR_FD_BDC_FD_Byte9 "TP Index : 276";
BA_ "Version" SG_ 2348810509 TP_L_DHRR_FD_BDC_FD_Byte1 "23.06.01";
BA_ "NetworkRequestHoldingTime" SG_ 2348810509 TP_L_DHRR_FD_BDC_FD_Byte1 5000;
BA_ "NetworkRequest" SG_ 2348810509 TP_L_DHRR_FD_BDC_FD_Byte1 0;
BA_ "UserSigValidity" SG_ 2348810509 TP_L_DHRR_FD_BDC_FD_Byte1 0;
BA_ "UsrSigPurpose" SG_ 2348810509 TP_L_DHRR_FD_BDC_FD_Byte1 9;
BA_ "Description" SG_ 2348810509 TP_L_DHRR_FD_BDC_FD_Byte1 "TP Index : 276";
BA_ "Version" SG_ 2348810509 TP_L_DHRR_FD_BDC_FD_Byte10 "23.06.01";
BA_ "NetworkRequestHoldingTime" SG_ 2348810509 TP_L_DHRR_FD_BDC_FD_Byte10 5000;
BA_ "NetworkRequest" SG_ 2348810509 TP_L_DHRR_FD_BDC_FD_Byte10 0;
BA_ "UserSigValidity" SG_ 2348810509 TP_L_DHRR_FD_BDC_FD_Byte10 0;
BA_ "UsrSigPurpose" SG_ 2348810509 TP_L_DHRR_FD_BDC_FD_Byte10 9;
BA_ "Description" SG_ 2348810509 TP_L_DHRR_FD_BDC_FD_Byte10 "TP Index : 276";
BA_ "Version" SG_ 2348810509 TP_L_DHRR_FD_BDC_FD_Byte11 "23.06.01";
BA_ "NetworkRequestHoldingTime" SG_ 2348810509 TP_L_DHRR_FD_BDC_FD_Byte11 5000;
BA_ "NetworkRequest" SG_ 2348810509 TP_L_DHRR_FD_BDC_FD_Byte11 0;
BA_ "UserSigValidity" SG_ 2348810509 TP_L_DHRR_FD_BDC_FD_Byte11 0;
BA_ "UsrSigPurpose" SG_ 2348810509 TP_L_DHRR_FD_BDC_FD_Byte11 9;
BA_ "Description" SG_ 2348810509 TP_L_DHRR_FD_BDC_FD_Byte11 "TP Index : 276";
BA_ "Version" SG_ 2348810509 TP_L_DHRR_FD_BDC_FD_Byte12 "23.06.01";
BA_ "NetworkRequestHoldingTime" SG_ 2348810509 TP_L_DHRR_FD_BDC_FD_Byte12 5000;
BA_ "NetworkRequest" SG_ 2348810509 TP_L_DHRR_FD_BDC_FD_Byte12 0;
BA_ "UserSigValidity" SG_ 2348810509 TP_L_DHRR_FD_BDC_FD_Byte12 0;
BA_ "UsrSigPurpose" SG_ 2348810509 TP_L_DHRR_FD_BDC_FD_Byte12 9;
BA_ "Description" SG_ 2348810509 TP_L_DHRR_FD_BDC_FD_Byte12 "TP Index : 276";
BA_ "Version" SG_ 745 PDC_FD_Crc15Val "24.04.08";
BA_ "UserSigValidity" SG_ 745 PDC_FD_Crc15Val 3;
BA_ "GenSigStartValue" SG_ 745 PDC_FD_Crc15Val 65535;
BA_ "GenSigSendType" SG_ 745 PDC_FD_Crc15Val 4;
BA_ "Description" SG_ 745 PDC_FD_Crc15Val "The data area for CRC calculation is based on the data length (DLC) of the message DB.

The CRC shall be calculated over the entire data block (excluding the CRC bytes) including the user data, alive counter and Data ID



- CRC Polynomial (0x1021) , Ini";
BA_ "Version" SG_ 745 PDC_CurrAtReset_Copy_0 "24.07.06";
BA_ "UserSigValidity" SG_ 745 PDC_CurrAtReset_Copy_0 0;
BA_ "GenSigSendType" SG_ 745 PDC_CurrAtReset_Copy_0 4;
BA_ "Description" SG_ 745 PDC_CurrAtReset_Copy_0 "This signal indicate the current at reset request";
BA_ "Version" SG_ 745 PDC_AvgCurrAtReset_Copy_0 "24.07.06";
BA_ "UserSigValidity" SG_ 745 PDC_AvgCurrAtReset_Copy_0 0;
BA_ "GenSigSendType" SG_ 745 PDC_AvgCurrAtReset_Copy_0 4;
BA_ "Description" SG_ 745 PDC_AvgCurrAtReset_Copy_0 "This signal indicate the average current at reset request";
BA_ "Version" SG_ 745 PDC_ResetReason_Copy_0 "24.07.06";
BA_ "UserSigValidity" SG_ 745 PDC_ResetReason_Copy_0 0;
BA_ "GenSigSendType" SG_ 745 PDC_ResetReason_Copy_0 4;
BA_ "Description" SG_ 745 PDC_ResetReason_Copy_0 "This signal indicate the reason reset is operated";
BA_ "Version" SG_ 745 PDC_CumulativeCountOf12VReq_Copy "24.07.06";
BA_ "UserSigValidity" SG_ 745 PDC_CumulativeCountOf12VReq_Copy 0;
BA_ "GenSigSendType" SG_ 745 PDC_CumulativeCountOf12VReq_Copy 4;
BA_ "Description" SG_ 745 PDC_CumulativeCountOf12VReq_Copy "This signal indicates the cumulative number of 12V Controller req.";
BA_ "SystemSignalLongSymbol" SG_ 745 PDC_CumulativeCountOf12VReq_Copy "PDC_CumulativeCountOf12VReq_Copy_0";
BA_ "Version" SG_ 745 PDC_CumulativeCountOfCCUReq_Copy "24.07.06";
BA_ "UserSigValidity" SG_ 745 PDC_CumulativeCountOfCCUReq_Copy 0;
BA_ "GenSigSendType" SG_ 745 PDC_CumulativeCountOfCCUReq_Copy 4;
BA_ "Description" SG_ 745 PDC_CumulativeCountOfCCUReq_Copy "This signal indicates the cumulative number of CCU_ForcedPowerOffReq";
BA_ "SystemSignalLongSymbol" SG_ 745 PDC_CumulativeCountOfCCUReq_Copy "PDC_CumulativeCountOfCCUReq_Copy_0";
BA_ "Version" SG_ 745 PDC_FD_AlvCnt15Val "24.04.08";
BA_ "UserSigValidity" SG_ 745 PDC_FD_AlvCnt15Val 3;
BA_ "GenSigSendType" SG_ 745 PDC_FD_AlvCnt15Val 4;
BA_ "Description" SG_ 745 PDC_FD_AlvCnt15Val "For the first transmission request for a data element the counter shall be initialized with 0 and shall be incremented by 1 for every subsequent send request. 

When the counter reaches the maximum value(0xFF), then it shall restart with 0 for the next s";
BA_ "Version" SG_ 745 PDC_LDConReq_Copy_0 "24.07.05";
BA_ "UserSigValidity" SG_ 745 PDC_LDConReq_Copy_0 0;
BA_ "GenSigSendType" SG_ 745 PDC_LDConReq_Copy_0 4;
BA_ "Description" SG_ 745 PDC_LDConReq_Copy_0 "LDC on request signal for High Voltage Battery Discharge";
BA_ "Version" SG_ 745 PDC_LDConReq_By_LVBat_Copy_0 "24.07.05";
BA_ "UserSigValidity" SG_ 745 PDC_LDConReq_By_LVBat_Copy_0 0;
BA_ "GenSigSendType" SG_ 745 PDC_LDConReq_By_LVBat_Copy_0 4;
BA_ "Description" SG_ 745 PDC_LDConReq_By_LVBat_Copy_0 "LDC on request signal for High Voltage Battery Discharge by Low Voltage Battery";
BA_ "Version" SG_ 745 PDC_LDConReq_By_OTA_Copy_0 "24.07.05";
BA_ "UserSigValidity" SG_ 745 PDC_LDConReq_By_OTA_Copy_0 0;
BA_ "GenSigSendType" SG_ 745 PDC_LDConReq_By_OTA_Copy_0 4;
BA_ "Description" SG_ 745 PDC_LDConReq_By_OTA_Copy_0 "LDC on request signal for High Voltage Battery Discharge by OTA";
BA_ "Version" SG_ 745 PDC_LDConReq_By_Load_Copy_0 "24.07.05";
BA_ "UserSigValidity" SG_ 745 PDC_LDConReq_By_Load_Copy_0 0;
BA_ "GenSigSendType" SG_ 745 PDC_LDConReq_By_Load_Copy_0 4;
BA_ "Description" SG_ 745 PDC_LDConReq_By_Load_Copy_0 "LDC on request signal for High Voltage Battery Discharge by Load";
BA_ "Version" SG_ 745 PDC_LDConReq_By_ActiveOn_Copy_0 "24.07.05";
BA_ "UserSigValidity" SG_ 745 PDC_LDConReq_By_ActiveOn_Copy_0 0;
BA_ "GenSigSendType" SG_ 745 PDC_LDConReq_By_ActiveOn_Copy_0 4;
BA_ "Description" SG_ 745 PDC_LDConReq_By_ActiveOn_Copy_0 "LDC on request signal for High Voltage Battery Discharge by Active On";
BA_ "Version" SG_ 745 PDC_ResetPreWrngForCCU_Copy_0 "24.05.05";
BA_ "UserSigValidity" SG_ 745 PDC_ResetPreWrngForCCU_Copy_0 0;
BA_ "GenSigSendType" SG_ 745 PDC_ResetPreWrngForCCU_Copy_0 4;
BA_ "Description" SG_ 745 PDC_ResetPreWrngForCCU_Copy_0 "This is a warning signal for reset.  This signal is used for preparing sideeffect of reset by Gateway";
BA_ "Version" SG_ 745 PDC_ResetPreWrngForOthers_Copy_0 "24.05.05";
BA_ "UserSigValidity" SG_ 745 PDC_ResetPreWrngForOthers_Copy_0 0;
BA_ "GenSigSendType" SG_ 745 PDC_ResetPreWrngForOthers_Copy_0 4;
BA_ "Description" SG_ 745 PDC_ResetPreWrngForOthers_Copy_0 "This is a warning signal for reset.  This signal is used for preparing sideeffect of reset by Receivers";
BA_ "Version" SG_ 745 PDC_ResetReqForCCU_Copy_0 "24.05.05";
BA_ "UserSigValidity" SG_ 745 PDC_ResetReqForCCU_Copy_0 0;
BA_ "GenSigSendType" SG_ 745 PDC_ResetReqForCCU_Copy_0 4;
BA_ "Description" SG_ 745 PDC_ResetReqForCCU_Copy_0 "This is a request signal for SW reset of Gateway";
BA_ "Version" SG_ 745 PDC_ResetReqForOthers_Copy_0 "24.05.05";
BA_ "UserSigValidity" SG_ 745 PDC_ResetReqForOthers_Copy_0 0;
BA_ "GenSigSendType" SG_ 745 PDC_ResetReqForOthers_Copy_0 4;
BA_ "Description" SG_ 745 PDC_ResetReqForOthers_Copy_0 "This is a request signal for SW reset except for Gateway";
BA_ "Version" SG_ 745 PDC_ResetFuncOpt_Copy_0 "24.05.05";
BA_ "UserSigValidity" SG_ 745 PDC_ResetFuncOpt_Copy_0 0;
BA_ "GenSigSendType" SG_ 745 PDC_ResetFuncOpt_Copy_0 4;
BA_ "Description" SG_ 745 PDC_ResetFuncOpt_Copy_0 "This signal inform whether reset fucntion at PDC is appiled or not";
BA_ "Version" SG_ 745 PDC_12VRlyCtrl_Copy_0 "24.05.05";
BA_ "UserSigValidity" SG_ 745 PDC_12VRlyCtrl_Copy_0 0;
BA_ "GenSigSendType" SG_ 745 PDC_12VRlyCtrl_Copy_0 4;
BA_ "Description" SG_ 745 PDC_12VRlyCtrl_Copy_0 "This signal is request signal to control 12V battery internal relay for HW reset";
BA_ "Version" SG_ 745 PDC_CurrentValueForReset_Copy_0 "24.07.03";
BA_ "UserSigValidity" SG_ 745 PDC_CurrentValueForReset_Copy_0 0;
BA_ "GenSigSendType" SG_ 745 PDC_CurrentValueForReset_Copy_0 4;
BA_ "Description" SG_ 745 PDC_CurrentValueForReset_Copy_0 "This signal sets the average discharge current value to be measured for PDC_TimevalueForReset to be considered as a situation requiring reset.";
BA_ "Version" SG_ 745 PDC_TimeValueForReset_Copy_0 "24.07.03";
BA_ "UserSigValidity" SG_ 745 PDC_TimeValueForReset_Copy_0 0;
BA_ "GenSigSendType" SG_ 745 PDC_TimeValueForReset_Copy_0 4;
BA_ "Description" SG_ 745 PDC_TimeValueForReset_Copy_0 "This signal sets the time value to be considered as a situation requiring reset.";
BA_ "Version" SG_ 745 PDC_12VRlyOffHoldingTime_Copy_0 "24.05.05";
BA_ "UserSigValidity" SG_ 745 PDC_12VRlyOffHoldingTime_Copy_0 0;
BA_ "GenSigSendType" SG_ 745 PDC_12VRlyOffHoldingTime_Copy_0 4;
BA_ "Description" SG_ 745 PDC_12VRlyOffHoldingTime_Copy_0 "This signal sets how long the relay will be turned off when performing an HW reset using a 12 V battery internal relay.";
BA_ "Version" SG_ 745 PDC_ResetCountSetting_Copy_0 "24.05.05";
BA_ "UserSigValidity" SG_ 745 PDC_ResetCountSetting_Copy_0 0;
BA_ "GenSigSendType" SG_ 745 PDC_ResetCountSetting_Copy_0 4;
BA_ "Description" SG_ 745 PDC_ResetCountSetting_Copy_0 "This signal sets the number of resets performed.";
BA_ "Version" SG_ 745 PDC_ResetCount_Copy_0 "24.05.05";
BA_ "UserSigValidity" SG_ 745 PDC_ResetCount_Copy_0 0;
BA_ "GenSigSendType" SG_ 745 PDC_ResetCount_Copy_0 4;
BA_ "Description" SG_ 745 PDC_ResetCount_Copy_0 "This signal indicates how much reset has occurred.";
BA_ "Version" SG_ 745 PDC_ResetCumulativeCount_Copy_0 "24.05.05";
BA_ "UserSigValidity" SG_ 745 PDC_ResetCumulativeCount_Copy_0 0;
BA_ "GenSigSendType" SG_ 745 PDC_ResetCumulativeCount_Copy_0 4;
BA_ "Description" SG_ 745 PDC_ResetCumulativeCount_Copy_0 "This signal indicates the cumulative number of resets performed.";
BA_ "Version" SG_ 745 PDC_ResetOpsta_Copy_0 "24.05.05";
BA_ "UserSigValidity" SG_ 745 PDC_ResetOpsta_Copy_0 0;
BA_ "GenSigSendType" SG_ 745 PDC_ResetOpsta_Copy_0 4;
BA_ "Description" SG_ 745 PDC_ResetOpsta_Copy_0 "This signal indicates whether the reset operation has been completed or not";
BA_ "Version" SG_ 745 PDC_ReadyTimeValueForReset_Copy_ "24.07.06";
BA_ "UserSigValidity" SG_ 745 PDC_ReadyTimeValueForReset_Copy_ 0;
BA_ "GenSigSendType" SG_ 745 PDC_ReadyTimeValueForReset_Copy_ 4;
BA_ "Description" SG_ 745 PDC_ReadyTimeValueForReset_Copy_ "This signal sets the time value to be considered as a situation of quiescent current

if receiver receive the value of no setting, do not operate the logic related to this signal";
BA_ "SystemSignalLongSymbol" SG_ 745 PDC_ReadyTimeValueForReset_Copy_ "PDC_ReadyTimeValueForReset_Copy_0";
BA_ "Version" SG_ 2348810508 TP_BDC_FD_L_DHRR_FD_Byte0 "23.06.01";
BA_ "NetworkRequestHoldingTime" SG_ 2348810508 TP_BDC_FD_L_DHRR_FD_Byte0 5000;
BA_ "NetworkRequest" SG_ 2348810508 TP_BDC_FD_L_DHRR_FD_Byte0 0;
BA_ "UserSigValidity" SG_ 2348810508 TP_BDC_FD_L_DHRR_FD_Byte0 0;
BA_ "UsrSigPurpose" SG_ 2348810508 TP_BDC_FD_L_DHRR_FD_Byte0 9;
BA_ "Description" SG_ 2348810508 TP_BDC_FD_L_DHRR_FD_Byte0 "TP Index : 276";
BA_ "Version" SG_ 2348810508 TP_BDC_FD_L_DHRR_FD_Byte13 "23.06.01";
BA_ "NetworkRequestHoldingTime" SG_ 2348810508 TP_BDC_FD_L_DHRR_FD_Byte13 5000;
BA_ "NetworkRequest" SG_ 2348810508 TP_BDC_FD_L_DHRR_FD_Byte13 0;
BA_ "UserSigValidity" SG_ 2348810508 TP_BDC_FD_L_DHRR_FD_Byte13 0;
BA_ "UsrSigPurpose" SG_ 2348810508 TP_BDC_FD_L_DHRR_FD_Byte13 9;
BA_ "Description" SG_ 2348810508 TP_BDC_FD_L_DHRR_FD_Byte13 "TP Index : 276";
BA_ "Version" SG_ 2348810508 TP_BDC_FD_L_DHRR_FD_Byte14 "23.06.01";
BA_ "NetworkRequestHoldingTime" SG_ 2348810508 TP_BDC_FD_L_DHRR_FD_Byte14 5000;
BA_ "NetworkRequest" SG_ 2348810508 TP_BDC_FD_L_DHRR_FD_Byte14 0;
BA_ "UserSigValidity" SG_ 2348810508 TP_BDC_FD_L_DHRR_FD_Byte14 0;
BA_ "UsrSigPurpose" SG_ 2348810508 TP_BDC_FD_L_DHRR_FD_Byte14 9;
BA_ "Description" SG_ 2348810508 TP_BDC_FD_L_DHRR_FD_Byte14 "TP Index : 276";
BA_ "Version" SG_ 2348810508 TP_BDC_FD_L_DHRR_FD_Byte15 "23.06.01";
BA_ "NetworkRequestHoldingTime" SG_ 2348810508 TP_BDC_FD_L_DHRR_FD_Byte15 5000;
BA_ "NetworkRequest" SG_ 2348810508 TP_BDC_FD_L_DHRR_FD_Byte15 0;
BA_ "UserSigValidity" SG_ 2348810508 TP_BDC_FD_L_DHRR_FD_Byte15 0;
BA_ "UsrSigPurpose" SG_ 2348810508 TP_BDC_FD_L_DHRR_FD_Byte15 9;
BA_ "Description" SG_ 2348810508 TP_BDC_FD_L_DHRR_FD_Byte15 "TP Index : 276";
BA_ "Version" SG_ 2348810508 TP_BDC_FD_L_DHRR_FD_Byte16 "23.06.01";
BA_ "NetworkRequestHoldingTime" SG_ 2348810508 TP_BDC_FD_L_DHRR_FD_Byte16 5000;
BA_ "NetworkRequest" SG_ 2348810508 TP_BDC_FD_L_DHRR_FD_Byte16 0;
BA_ "UserSigValidity" SG_ 2348810508 TP_BDC_FD_L_DHRR_FD_Byte16 0;
BA_ "UsrSigPurpose" SG_ 2348810508 TP_BDC_FD_L_DHRR_FD_Byte16 9;
BA_ "Description" SG_ 2348810508 TP_BDC_FD_L_DHRR_FD_Byte16 "TP Index : 276";
BA_ "Version" SG_ 2348810508 TP_BDC_FD_L_DHRR_FD_Byte17 "23.06.01";
BA_ "NetworkRequestHoldingTime" SG_ 2348810508 TP_BDC_FD_L_DHRR_FD_Byte17 5000;
BA_ "NetworkRequest" SG_ 2348810508 TP_BDC_FD_L_DHRR_FD_Byte17 0;
BA_ "UserSigValidity" SG_ 2348810508 TP_BDC_FD_L_DHRR_FD_Byte17 0;
BA_ "UsrSigPurpose" SG_ 2348810508 TP_BDC_FD_L_DHRR_FD_Byte17 9;
BA_ "Description" SG_ 2348810508 TP_BDC_FD_L_DHRR_FD_Byte17 "TP Index : 276";
BA_ "Version" SG_ 2348810508 TP_BDC_FD_L_DHRR_FD_Byte18 "23.06.01";
BA_ "NetworkRequestHoldingTime" SG_ 2348810508 TP_BDC_FD_L_DHRR_FD_Byte18 5000;
BA_ "NetworkRequest" SG_ 2348810508 TP_BDC_FD_L_DHRR_FD_Byte18 0;
BA_ "UserSigValidity" SG_ 2348810508 TP_BDC_FD_L_DHRR_FD_Byte18 0;
BA_ "UsrSigPurpose" SG_ 2348810508 TP_BDC_FD_L_DHRR_FD_Byte18 9;
BA_ "Description" SG_ 2348810508 TP_BDC_FD_L_DHRR_FD_Byte18 "TP Index : 276";
BA_ "Version" SG_ 2348810508 TP_BDC_FD_L_DHRR_FD_Byte19 "23.06.01";
BA_ "NetworkRequestHoldingTime" SG_ 2348810508 TP_BDC_FD_L_DHRR_FD_Byte19 5000;
BA_ "NetworkRequest" SG_ 2348810508 TP_BDC_FD_L_DHRR_FD_Byte19 0;
BA_ "UserSigValidity" SG_ 2348810508 TP_BDC_FD_L_DHRR_FD_Byte19 0;
BA_ "UsrSigPurpose" SG_ 2348810508 TP_BDC_FD_L_DHRR_FD_Byte19 9;
BA_ "Description" SG_ 2348810508 TP_BDC_FD_L_DHRR_FD_Byte19 "TP Index : 276";
BA_ "Version" SG_ 2348810508 TP_BDC_FD_L_DHRR_FD_Byte2 "23.06.01";
BA_ "NetworkRequestHoldingTime" SG_ 2348810508 TP_BDC_FD_L_DHRR_FD_Byte2 5000;
BA_ "NetworkRequest" SG_ 2348810508 TP_BDC_FD_L_DHRR_FD_Byte2 0;
BA_ "UserSigValidity" SG_ 2348810508 TP_BDC_FD_L_DHRR_FD_Byte2 0;
BA_ "UsrSigPurpose" SG_ 2348810508 TP_BDC_FD_L_DHRR_FD_Byte2 9;
BA_ "Description" SG_ 2348810508 TP_BDC_FD_L_DHRR_FD_Byte2 "TP Index : 276";
BA_ "Version" SG_ 2348810508 TP_BDC_FD_L_DHRR_FD_Byte20 "23.06.01";
BA_ "NetworkRequestHoldingTime" SG_ 2348810508 TP_BDC_FD_L_DHRR_FD_Byte20 5000;
BA_ "NetworkRequest" SG_ 2348810508 TP_BDC_FD_L_DHRR_FD_Byte20 0;
BA_ "UserSigValidity" SG_ 2348810508 TP_BDC_FD_L_DHRR_FD_Byte20 0;
BA_ "UsrSigPurpose" SG_ 2348810508 TP_BDC_FD_L_DHRR_FD_Byte20 9;
BA_ "Description" SG_ 2348810508 TP_BDC_FD_L_DHRR_FD_Byte20 "TP Index : 276";
BA_ "Version" SG_ 2348810508 TP_BDC_FD_L_DHRR_FD_Byte21 "23.06.01";
BA_ "NetworkRequestHoldingTime" SG_ 2348810508 TP_BDC_FD_L_DHRR_FD_Byte21 5000;
BA_ "NetworkRequest" SG_ 2348810508 TP_BDC_FD_L_DHRR_FD_Byte21 0;
BA_ "UserSigValidity" SG_ 2348810508 TP_BDC_FD_L_DHRR_FD_Byte21 0;
BA_ "UsrSigPurpose" SG_ 2348810508 TP_BDC_FD_L_DHRR_FD_Byte21 9;
BA_ "Description" SG_ 2348810508 TP_BDC_FD_L_DHRR_FD_Byte21 "TP Index : 276";
BA_ "Version" SG_ 2348810508 TP_BDC_FD_L_DHRR_FD_Byte22 "23.06.01";
BA_ "NetworkRequestHoldingTime" SG_ 2348810508 TP_BDC_FD_L_DHRR_FD_Byte22 5000;
BA_ "NetworkRequest" SG_ 2348810508 TP_BDC_FD_L_DHRR_FD_Byte22 0;
BA_ "UserSigValidity" SG_ 2348810508 TP_BDC_FD_L_DHRR_FD_Byte22 0;
BA_ "UsrSigPurpose" SG_ 2348810508 TP_BDC_FD_L_DHRR_FD_Byte22 9;
BA_ "Description" SG_ 2348810508 TP_BDC_FD_L_DHRR_FD_Byte22 "TP Index : 276";
BA_ "Version" SG_ 2348810508 TP_BDC_FD_L_DHRR_FD_Byte23 "23.06.01";
BA_ "NetworkRequestHoldingTime" SG_ 2348810508 TP_BDC_FD_L_DHRR_FD_Byte23 5000;
BA_ "NetworkRequest" SG_ 2348810508 TP_BDC_FD_L_DHRR_FD_Byte23 0;
BA_ "UserSigValidity" SG_ 2348810508 TP_BDC_FD_L_DHRR_FD_Byte23 0;
BA_ "UsrSigPurpose" SG_ 2348810508 TP_BDC_FD_L_DHRR_FD_Byte23 9;
BA_ "Description" SG_ 2348810508 TP_BDC_FD_L_DHRR_FD_Byte23 "TP Index : 276";
BA_ "Version" SG_ 2348810508 TP_BDC_FD_L_DHRR_FD_Byte24 "23.06.01";
BA_ "NetworkRequestHoldingTime" SG_ 2348810508 TP_BDC_FD_L_DHRR_FD_Byte24 5000;
BA_ "NetworkRequest" SG_ 2348810508 TP_BDC_FD_L_DHRR_FD_Byte24 0;
BA_ "UserSigValidity" SG_ 2348810508 TP_BDC_FD_L_DHRR_FD_Byte24 0;
BA_ "UsrSigPurpose" SG_ 2348810508 TP_BDC_FD_L_DHRR_FD_Byte24 9;
BA_ "Description" SG_ 2348810508 TP_BDC_FD_L_DHRR_FD_Byte24 "TP Index : 276";
BA_ "Version" SG_ 2348810508 TP_BDC_FD_L_DHRR_FD_Byte25 "23.06.01";
BA_ "NetworkRequestHoldingTime" SG_ 2348810508 TP_BDC_FD_L_DHRR_FD_Byte25 5000;
BA_ "NetworkRequest" SG_ 2348810508 TP_BDC_FD_L_DHRR_FD_Byte25 0;
BA_ "UserSigValidity" SG_ 2348810508 TP_BDC_FD_L_DHRR_FD_Byte25 0;
BA_ "UsrSigPurpose" SG_ 2348810508 TP_BDC_FD_L_DHRR_FD_Byte25 9;
BA_ "Description" SG_ 2348810508 TP_BDC_FD_L_DHRR_FD_Byte25 "TP Index : 276";
BA_ "Version" SG_ 2348810508 TP_BDC_FD_L_DHRR_FD_Byte26 "23.06.01";
BA_ "NetworkRequestHoldingTime" SG_ 2348810508 TP_BDC_FD_L_DHRR_FD_Byte26 5000;
BA_ "NetworkRequest" SG_ 2348810508 TP_BDC_FD_L_DHRR_FD_Byte26 0;
BA_ "UserSigValidity" SG_ 2348810508 TP_BDC_FD_L_DHRR_FD_Byte26 0;
BA_ "UsrSigPurpose" SG_ 2348810508 TP_BDC_FD_L_DHRR_FD_Byte26 9;
BA_ "Description" SG_ 2348810508 TP_BDC_FD_L_DHRR_FD_Byte26 "TP Index : 276";
BA_ "Version" SG_ 2348810508 TP_BDC_FD_L_DHRR_FD_Byte27 "23.06.01";
BA_ "NetworkRequestHoldingTime" SG_ 2348810508 TP_BDC_FD_L_DHRR_FD_Byte27 5000;
BA_ "NetworkRequest" SG_ 2348810508 TP_BDC_FD_L_DHRR_FD_Byte27 0;
BA_ "UserSigValidity" SG_ 2348810508 TP_BDC_FD_L_DHRR_FD_Byte27 0;
BA_ "UsrSigPurpose" SG_ 2348810508 TP_BDC_FD_L_DHRR_FD_Byte27 9;
BA_ "Description" SG_ 2348810508 TP_BDC_FD_L_DHRR_FD_Byte27 "TP Index : 276";
BA_ "Version" SG_ 2348810508 TP_BDC_FD_L_DHRR_FD_Byte28 "23.06.01";
BA_ "NetworkRequestHoldingTime" SG_ 2348810508 TP_BDC_FD_L_DHRR_FD_Byte28 5000;
BA_ "NetworkRequest" SG_ 2348810508 TP_BDC_FD_L_DHRR_FD_Byte28 0;
BA_ "UserSigValidity" SG_ 2348810508 TP_BDC_FD_L_DHRR_FD_Byte28 0;
BA_ "UsrSigPurpose" SG_ 2348810508 TP_BDC_FD_L_DHRR_FD_Byte28 9;
BA_ "Description" SG_ 2348810508 TP_BDC_FD_L_DHRR_FD_Byte28 "TP Index : 276";
BA_ "Version" SG_ 2348810508 TP_BDC_FD_L_DHRR_FD_Byte29 "23.06.01";
BA_ "NetworkRequestHoldingTime" SG_ 2348810508 TP_BDC_FD_L_DHRR_FD_Byte29 5000;
BA_ "NetworkRequest" SG_ 2348810508 TP_BDC_FD_L_DHRR_FD_Byte29 0;
BA_ "UserSigValidity" SG_ 2348810508 TP_BDC_FD_L_DHRR_FD_Byte29 0;
BA_ "UsrSigPurpose" SG_ 2348810508 TP_BDC_FD_L_DHRR_FD_Byte29 9;
BA_ "Description" SG_ 2348810508 TP_BDC_FD_L_DHRR_FD_Byte29 "TP Index : 276";
BA_ "Version" SG_ 2348810508 TP_BDC_FD_L_DHRR_FD_Byte3 "23.06.01";
BA_ "NetworkRequestHoldingTime" SG_ 2348810508 TP_BDC_FD_L_DHRR_FD_Byte3 5000;
BA_ "NetworkRequest" SG_ 2348810508 TP_BDC_FD_L_DHRR_FD_Byte3 0;
BA_ "UserSigValidity" SG_ 2348810508 TP_BDC_FD_L_DHRR_FD_Byte3 0;
BA_ "UsrSigPurpose" SG_ 2348810508 TP_BDC_FD_L_DHRR_FD_Byte3 9;
BA_ "Description" SG_ 2348810508 TP_BDC_FD_L_DHRR_FD_Byte3 "TP Index : 276";
BA_ "Version" SG_ 2348810508 TP_BDC_FD_L_DHRR_FD_Byte30 "23.06.01";
BA_ "NetworkRequestHoldingTime" SG_ 2348810508 TP_BDC_FD_L_DHRR_FD_Byte30 5000;
BA_ "NetworkRequest" SG_ 2348810508 TP_BDC_FD_L_DHRR_FD_Byte30 0;
BA_ "UserSigValidity" SG_ 2348810508 TP_BDC_FD_L_DHRR_FD_Byte30 0;
BA_ "UsrSigPurpose" SG_ 2348810508 TP_BDC_FD_L_DHRR_FD_Byte30 9;
BA_ "Description" SG_ 2348810508 TP_BDC_FD_L_DHRR_FD_Byte30 "TP Index : 276";
BA_ "Version" SG_ 2348810508 TP_BDC_FD_L_DHRR_FD_Byte31 "23.06.01";
BA_ "NetworkRequestHoldingTime" SG_ 2348810508 TP_BDC_FD_L_DHRR_FD_Byte31 5000;
BA_ "NetworkRequest" SG_ 2348810508 TP_BDC_FD_L_DHRR_FD_Byte31 0;
BA_ "UserSigValidity" SG_ 2348810508 TP_BDC_FD_L_DHRR_FD_Byte31 0;
BA_ "UsrSigPurpose" SG_ 2348810508 TP_BDC_FD_L_DHRR_FD_Byte31 9;
BA_ "Description" SG_ 2348810508 TP_BDC_FD_L_DHRR_FD_Byte31 "TP Index : 276";
BA_ "Version" SG_ 2348810508 TP_BDC_FD_L_DHRR_FD_Byte4 "23.06.01";
BA_ "NetworkRequestHoldingTime" SG_ 2348810508 TP_BDC_FD_L_DHRR_FD_Byte4 5000;
BA_ "NetworkRequest" SG_ 2348810508 TP_BDC_FD_L_DHRR_FD_Byte4 0;
BA_ "UserSigValidity" SG_ 2348810508 TP_BDC_FD_L_DHRR_FD_Byte4 0;
BA_ "UsrSigPurpose" SG_ 2348810508 TP_BDC_FD_L_DHRR_FD_Byte4 9;
BA_ "Description" SG_ 2348810508 TP_BDC_FD_L_DHRR_FD_Byte4 "TP Index : 276";
BA_ "Version" SG_ 2348810508 TP_BDC_FD_L_DHRR_FD_Byte5 "23.06.01";
BA_ "NetworkRequestHoldingTime" SG_ 2348810508 TP_BDC_FD_L_DHRR_FD_Byte5 5000;
BA_ "NetworkRequest" SG_ 2348810508 TP_BDC_FD_L_DHRR_FD_Byte5 0;
BA_ "UserSigValidity" SG_ 2348810508 TP_BDC_FD_L_DHRR_FD_Byte5 0;
BA_ "UsrSigPurpose" SG_ 2348810508 TP_BDC_FD_L_DHRR_FD_Byte5 9;
BA_ "Description" SG_ 2348810508 TP_BDC_FD_L_DHRR_FD_Byte5 "TP Index : 276";
BA_ "Version" SG_ 2348810508 TP_BDC_FD_L_DHRR_FD_Byte6 "23.06.01";
BA_ "NetworkRequestHoldingTime" SG_ 2348810508 TP_BDC_FD_L_DHRR_FD_Byte6 5000;
BA_ "NetworkRequest" SG_ 2348810508 TP_BDC_FD_L_DHRR_FD_Byte6 0;
BA_ "UserSigValidity" SG_ 2348810508 TP_BDC_FD_L_DHRR_FD_Byte6 0;
BA_ "UsrSigPurpose" SG_ 2348810508 TP_BDC_FD_L_DHRR_FD_Byte6 9;
BA_ "Description" SG_ 2348810508 TP_BDC_FD_L_DHRR_FD_Byte6 "TP Index : 276";
BA_ "Version" SG_ 2348810508 TP_BDC_FD_L_DHRR_FD_Byte7 "23.06.01";
BA_ "NetworkRequestHoldingTime" SG_ 2348810508 TP_BDC_FD_L_DHRR_FD_Byte7 5000;
BA_ "NetworkRequest" SG_ 2348810508 TP_BDC_FD_L_DHRR_FD_Byte7 0;
BA_ "UserSigValidity" SG_ 2348810508 TP_BDC_FD_L_DHRR_FD_Byte7 0;
BA_ "UsrSigPurpose" SG_ 2348810508 TP_BDC_FD_L_DHRR_FD_Byte7 9;
BA_ "Description" SG_ 2348810508 TP_BDC_FD_L_DHRR_FD_Byte7 "TP Index : 276";
BA_ "Version" SG_ 2348810508 TP_BDC_FD_L_DHRR_FD_Byte8 "23.06.01";
BA_ "NetworkRequestHoldingTime" SG_ 2348810508 TP_BDC_FD_L_DHRR_FD_Byte8 5000;
BA_ "NetworkRequest" SG_ 2348810508 TP_BDC_FD_L_DHRR_FD_Byte8 0;
BA_ "UserSigValidity" SG_ 2348810508 TP_BDC_FD_L_DHRR_FD_Byte8 0;
BA_ "UsrSigPurpose" SG_ 2348810508 TP_BDC_FD_L_DHRR_FD_Byte8 9;
BA_ "Description" SG_ 2348810508 TP_BDC_FD_L_DHRR_FD_Byte8 "TP Index : 276";
BA_ "Version" SG_ 2348810508 TP_BDC_FD_L_DHRR_FD_Byte9 "23.06.01";
BA_ "NetworkRequestHoldingTime" SG_ 2348810508 TP_BDC_FD_L_DHRR_FD_Byte9 5000;
BA_ "NetworkRequest" SG_ 2348810508 TP_BDC_FD_L_DHRR_FD_Byte9 0;
BA_ "UserSigValidity" SG_ 2348810508 TP_BDC_FD_L_DHRR_FD_Byte9 0;
BA_ "UsrSigPurpose" SG_ 2348810508 TP_BDC_FD_L_DHRR_FD_Byte9 9;
BA_ "Description" SG_ 2348810508 TP_BDC_FD_L_DHRR_FD_Byte9 "TP Index : 276";
BA_ "Version" SG_ 2348810508 TP_BDC_FD_L_DHRR_FD_Byte1 "23.06.01";
BA_ "NetworkRequestHoldingTime" SG_ 2348810508 TP_BDC_FD_L_DHRR_FD_Byte1 5000;
BA_ "NetworkRequest" SG_ 2348810508 TP_BDC_FD_L_DHRR_FD_Byte1 0;
BA_ "UserSigValidity" SG_ 2348810508 TP_BDC_FD_L_DHRR_FD_Byte1 0;
BA_ "UsrSigPurpose" SG_ 2348810508 TP_BDC_FD_L_DHRR_FD_Byte1 9;
BA_ "Description" SG_ 2348810508 TP_BDC_FD_L_DHRR_FD_Byte1 "TP Index : 276";
BA_ "Version" SG_ 2348810508 TP_BDC_FD_L_DHRR_FD_Byte10 "23.06.01";
BA_ "NetworkRequestHoldingTime" SG_ 2348810508 TP_BDC_FD_L_DHRR_FD_Byte10 5000;
BA_ "NetworkRequest" SG_ 2348810508 TP_BDC_FD_L_DHRR_FD_Byte10 0;
BA_ "UserSigValidity" SG_ 2348810508 TP_BDC_FD_L_DHRR_FD_Byte10 0;
BA_ "UsrSigPurpose" SG_ 2348810508 TP_BDC_FD_L_DHRR_FD_Byte10 9;
BA_ "Description" SG_ 2348810508 TP_BDC_FD_L_DHRR_FD_Byte10 "TP Index : 276";
BA_ "Version" SG_ 2348810508 TP_BDC_FD_L_DHRR_FD_Byte11 "23.06.01";
BA_ "NetworkRequestHoldingTime" SG_ 2348810508 TP_BDC_FD_L_DHRR_FD_Byte11 5000;
BA_ "NetworkRequest" SG_ 2348810508 TP_BDC_FD_L_DHRR_FD_Byte11 0;
BA_ "UserSigValidity" SG_ 2348810508 TP_BDC_FD_L_DHRR_FD_Byte11 0;
BA_ "UsrSigPurpose" SG_ 2348810508 TP_BDC_FD_L_DHRR_FD_Byte11 9;
BA_ "Description" SG_ 2348810508 TP_BDC_FD_L_DHRR_FD_Byte11 "TP Index : 276";
BA_ "Version" SG_ 2348810508 TP_BDC_FD_L_DHRR_FD_Byte12 "23.06.01";
BA_ "NetworkRequestHoldingTime" SG_ 2348810508 TP_BDC_FD_L_DHRR_FD_Byte12 5000;
BA_ "NetworkRequest" SG_ 2348810508 TP_BDC_FD_L_DHRR_FD_Byte12 0;
BA_ "UserSigValidity" SG_ 2348810508 TP_BDC_FD_L_DHRR_FD_Byte12 0;
BA_ "UsrSigPurpose" SG_ 2348810508 TP_BDC_FD_L_DHRR_FD_Byte12 9;
BA_ "Description" SG_ 2348810508 TP_BDC_FD_L_DHRR_FD_Byte12 "TP Index : 276";
BA_ "Version" SG_ 2348810507 TP_L_DHRL_FD_BDC_FD_Byte0 "23.06.01";
BA_ "NetworkRequestHoldingTime" SG_ 2348810507 TP_L_DHRL_FD_BDC_FD_Byte0 5000;
BA_ "NetworkRequest" SG_ 2348810507 TP_L_DHRL_FD_BDC_FD_Byte0 0;
BA_ "UserSigValidity" SG_ 2348810507 TP_L_DHRL_FD_BDC_FD_Byte0 0;
BA_ "UsrSigPurpose" SG_ 2348810507 TP_L_DHRL_FD_BDC_FD_Byte0 9;
BA_ "Description" SG_ 2348810507 TP_L_DHRL_FD_BDC_FD_Byte0 "TP Index : 275";
BA_ "Version" SG_ 2348810507 TP_L_DHRL_FD_BDC_FD_Byte13 "23.06.01";
BA_ "NetworkRequestHoldingTime" SG_ 2348810507 TP_L_DHRL_FD_BDC_FD_Byte13 5000;
BA_ "NetworkRequest" SG_ 2348810507 TP_L_DHRL_FD_BDC_FD_Byte13 0;
BA_ "UserSigValidity" SG_ 2348810507 TP_L_DHRL_FD_BDC_FD_Byte13 0;
BA_ "UsrSigPurpose" SG_ 2348810507 TP_L_DHRL_FD_BDC_FD_Byte13 9;
BA_ "Description" SG_ 2348810507 TP_L_DHRL_FD_BDC_FD_Byte13 "TP Index : 275";
BA_ "Version" SG_ 2348810507 TP_L_DHRL_FD_BDC_FD_Byte14 "23.06.01";
BA_ "NetworkRequestHoldingTime" SG_ 2348810507 TP_L_DHRL_FD_BDC_FD_Byte14 5000;
BA_ "NetworkRequest" SG_ 2348810507 TP_L_DHRL_FD_BDC_FD_Byte14 0;
BA_ "UserSigValidity" SG_ 2348810507 TP_L_DHRL_FD_BDC_FD_Byte14 0;
BA_ "UsrSigPurpose" SG_ 2348810507 TP_L_DHRL_FD_BDC_FD_Byte14 9;
BA_ "Description" SG_ 2348810507 TP_L_DHRL_FD_BDC_FD_Byte14 "TP Index : 275";
BA_ "Version" SG_ 2348810507 TP_L_DHRL_FD_BDC_FD_Byte15 "23.06.01";
BA_ "NetworkRequestHoldingTime" SG_ 2348810507 TP_L_DHRL_FD_BDC_FD_Byte15 5000;
BA_ "NetworkRequest" SG_ 2348810507 TP_L_DHRL_FD_BDC_FD_Byte15 0;
BA_ "UserSigValidity" SG_ 2348810507 TP_L_DHRL_FD_BDC_FD_Byte15 0;
BA_ "UsrSigPurpose" SG_ 2348810507 TP_L_DHRL_FD_BDC_FD_Byte15 9;
BA_ "Description" SG_ 2348810507 TP_L_DHRL_FD_BDC_FD_Byte15 "TP Index : 275";
BA_ "Version" SG_ 2348810507 TP_L_DHRL_FD_BDC_FD_Byte16 "23.06.01";
BA_ "NetworkRequestHoldingTime" SG_ 2348810507 TP_L_DHRL_FD_BDC_FD_Byte16 5000;
BA_ "NetworkRequest" SG_ 2348810507 TP_L_DHRL_FD_BDC_FD_Byte16 0;
BA_ "UserSigValidity" SG_ 2348810507 TP_L_DHRL_FD_BDC_FD_Byte16 0;
BA_ "UsrSigPurpose" SG_ 2348810507 TP_L_DHRL_FD_BDC_FD_Byte16 9;
BA_ "Description" SG_ 2348810507 TP_L_DHRL_FD_BDC_FD_Byte16 "TP Index : 275";
BA_ "Version" SG_ 2348810507 TP_L_DHRL_FD_BDC_FD_Byte17 "23.06.01";
BA_ "NetworkRequestHoldingTime" SG_ 2348810507 TP_L_DHRL_FD_BDC_FD_Byte17 5000;
BA_ "NetworkRequest" SG_ 2348810507 TP_L_DHRL_FD_BDC_FD_Byte17 0;
BA_ "UserSigValidity" SG_ 2348810507 TP_L_DHRL_FD_BDC_FD_Byte17 0;
BA_ "UsrSigPurpose" SG_ 2348810507 TP_L_DHRL_FD_BDC_FD_Byte17 9;
BA_ "Description" SG_ 2348810507 TP_L_DHRL_FD_BDC_FD_Byte17 "TP Index : 275";
BA_ "Version" SG_ 2348810507 TP_L_DHRL_FD_BDC_FD_Byte18 "23.06.01";
BA_ "NetworkRequestHoldingTime" SG_ 2348810507 TP_L_DHRL_FD_BDC_FD_Byte18 5000;
BA_ "NetworkRequest" SG_ 2348810507 TP_L_DHRL_FD_BDC_FD_Byte18 0;
BA_ "UserSigValidity" SG_ 2348810507 TP_L_DHRL_FD_BDC_FD_Byte18 0;
BA_ "UsrSigPurpose" SG_ 2348810507 TP_L_DHRL_FD_BDC_FD_Byte18 9;
BA_ "Description" SG_ 2348810507 TP_L_DHRL_FD_BDC_FD_Byte18 "TP Index : 275";
BA_ "Version" SG_ 2348810507 TP_L_DHRL_FD_BDC_FD_Byte19 "23.06.01";
BA_ "NetworkRequestHoldingTime" SG_ 2348810507 TP_L_DHRL_FD_BDC_FD_Byte19 5000;
BA_ "NetworkRequest" SG_ 2348810507 TP_L_DHRL_FD_BDC_FD_Byte19 0;
BA_ "UserSigValidity" SG_ 2348810507 TP_L_DHRL_FD_BDC_FD_Byte19 0;
BA_ "UsrSigPurpose" SG_ 2348810507 TP_L_DHRL_FD_BDC_FD_Byte19 9;
BA_ "Description" SG_ 2348810507 TP_L_DHRL_FD_BDC_FD_Byte19 "TP Index : 275";
BA_ "Version" SG_ 2348810507 TP_L_DHRL_FD_BDC_FD_Byte2 "23.06.01";
BA_ "NetworkRequestHoldingTime" SG_ 2348810507 TP_L_DHRL_FD_BDC_FD_Byte2 5000;
BA_ "NetworkRequest" SG_ 2348810507 TP_L_DHRL_FD_BDC_FD_Byte2 0;
BA_ "UserSigValidity" SG_ 2348810507 TP_L_DHRL_FD_BDC_FD_Byte2 0;
BA_ "UsrSigPurpose" SG_ 2348810507 TP_L_DHRL_FD_BDC_FD_Byte2 9;
BA_ "Description" SG_ 2348810507 TP_L_DHRL_FD_BDC_FD_Byte2 "TP Index : 275";
BA_ "Version" SG_ 2348810507 TP_L_DHRL_FD_BDC_FD_Byte20 "23.06.01";
BA_ "NetworkRequestHoldingTime" SG_ 2348810507 TP_L_DHRL_FD_BDC_FD_Byte20 5000;
BA_ "NetworkRequest" SG_ 2348810507 TP_L_DHRL_FD_BDC_FD_Byte20 0;
BA_ "UserSigValidity" SG_ 2348810507 TP_L_DHRL_FD_BDC_FD_Byte20 0;
BA_ "UsrSigPurpose" SG_ 2348810507 TP_L_DHRL_FD_BDC_FD_Byte20 9;
BA_ "Description" SG_ 2348810507 TP_L_DHRL_FD_BDC_FD_Byte20 "TP Index : 275";
BA_ "Version" SG_ 2348810507 TP_L_DHRL_FD_BDC_FD_Byte21 "23.06.01";
BA_ "NetworkRequestHoldingTime" SG_ 2348810507 TP_L_DHRL_FD_BDC_FD_Byte21 5000;
BA_ "NetworkRequest" SG_ 2348810507 TP_L_DHRL_FD_BDC_FD_Byte21 0;
BA_ "UserSigValidity" SG_ 2348810507 TP_L_DHRL_FD_BDC_FD_Byte21 0;
BA_ "UsrSigPurpose" SG_ 2348810507 TP_L_DHRL_FD_BDC_FD_Byte21 9;
BA_ "Description" SG_ 2348810507 TP_L_DHRL_FD_BDC_FD_Byte21 "TP Index : 275";
BA_ "Version" SG_ 2348810507 TP_L_DHRL_FD_BDC_FD_Byte22 "23.06.01";
BA_ "NetworkRequestHoldingTime" SG_ 2348810507 TP_L_DHRL_FD_BDC_FD_Byte22 5000;
BA_ "NetworkRequest" SG_ 2348810507 TP_L_DHRL_FD_BDC_FD_Byte22 0;
BA_ "UserSigValidity" SG_ 2348810507 TP_L_DHRL_FD_BDC_FD_Byte22 0;
BA_ "UsrSigPurpose" SG_ 2348810507 TP_L_DHRL_FD_BDC_FD_Byte22 9;
BA_ "Description" SG_ 2348810507 TP_L_DHRL_FD_BDC_FD_Byte22 "TP Index : 275";
BA_ "Version" SG_ 2348810507 TP_L_DHRL_FD_BDC_FD_Byte23 "23.06.01";
BA_ "NetworkRequestHoldingTime" SG_ 2348810507 TP_L_DHRL_FD_BDC_FD_Byte23 5000;
BA_ "NetworkRequest" SG_ 2348810507 TP_L_DHRL_FD_BDC_FD_Byte23 0;
BA_ "UserSigValidity" SG_ 2348810507 TP_L_DHRL_FD_BDC_FD_Byte23 0;
BA_ "UsrSigPurpose" SG_ 2348810507 TP_L_DHRL_FD_BDC_FD_Byte23 9;
BA_ "Description" SG_ 2348810507 TP_L_DHRL_FD_BDC_FD_Byte23 "TP Index : 275";
BA_ "Version" SG_ 2348810507 TP_L_DHRL_FD_BDC_FD_Byte24 "23.06.01";
BA_ "NetworkRequestHoldingTime" SG_ 2348810507 TP_L_DHRL_FD_BDC_FD_Byte24 5000;
BA_ "NetworkRequest" SG_ 2348810507 TP_L_DHRL_FD_BDC_FD_Byte24 0;
BA_ "UserSigValidity" SG_ 2348810507 TP_L_DHRL_FD_BDC_FD_Byte24 0;
BA_ "UsrSigPurpose" SG_ 2348810507 TP_L_DHRL_FD_BDC_FD_Byte24 9;
BA_ "Description" SG_ 2348810507 TP_L_DHRL_FD_BDC_FD_Byte24 "TP Index : 275";
BA_ "Version" SG_ 2348810507 TP_L_DHRL_FD_BDC_FD_Byte25 "23.06.01";
BA_ "NetworkRequestHoldingTime" SG_ 2348810507 TP_L_DHRL_FD_BDC_FD_Byte25 5000;
BA_ "NetworkRequest" SG_ 2348810507 TP_L_DHRL_FD_BDC_FD_Byte25 0;
BA_ "UserSigValidity" SG_ 2348810507 TP_L_DHRL_FD_BDC_FD_Byte25 0;
BA_ "UsrSigPurpose" SG_ 2348810507 TP_L_DHRL_FD_BDC_FD_Byte25 9;
BA_ "Description" SG_ 2348810507 TP_L_DHRL_FD_BDC_FD_Byte25 "TP Index : 275";
BA_ "Version" SG_ 2348810507 TP_L_DHRL_FD_BDC_FD_Byte26 "23.06.01";
BA_ "NetworkRequestHoldingTime" SG_ 2348810507 TP_L_DHRL_FD_BDC_FD_Byte26 5000;
BA_ "NetworkRequest" SG_ 2348810507 TP_L_DHRL_FD_BDC_FD_Byte26 0;
BA_ "UserSigValidity" SG_ 2348810507 TP_L_DHRL_FD_BDC_FD_Byte26 0;
BA_ "UsrSigPurpose" SG_ 2348810507 TP_L_DHRL_FD_BDC_FD_Byte26 9;
BA_ "Description" SG_ 2348810507 TP_L_DHRL_FD_BDC_FD_Byte26 "TP Index : 275";
BA_ "Version" SG_ 2348810507 TP_L_DHRL_FD_BDC_FD_Byte27 "23.06.01";
BA_ "NetworkRequestHoldingTime" SG_ 2348810507 TP_L_DHRL_FD_BDC_FD_Byte27 5000;
BA_ "NetworkRequest" SG_ 2348810507 TP_L_DHRL_FD_BDC_FD_Byte27 0;
BA_ "UserSigValidity" SG_ 2348810507 TP_L_DHRL_FD_BDC_FD_Byte27 0;
BA_ "UsrSigPurpose" SG_ 2348810507 TP_L_DHRL_FD_BDC_FD_Byte27 9;
BA_ "Description" SG_ 2348810507 TP_L_DHRL_FD_BDC_FD_Byte27 "TP Index : 275";
BA_ "Version" SG_ 2348810507 TP_L_DHRL_FD_BDC_FD_Byte28 "23.06.01";
BA_ "NetworkRequestHoldingTime" SG_ 2348810507 TP_L_DHRL_FD_BDC_FD_Byte28 5000;
BA_ "NetworkRequest" SG_ 2348810507 TP_L_DHRL_FD_BDC_FD_Byte28 0;
BA_ "UserSigValidity" SG_ 2348810507 TP_L_DHRL_FD_BDC_FD_Byte28 0;
BA_ "UsrSigPurpose" SG_ 2348810507 TP_L_DHRL_FD_BDC_FD_Byte28 9;
BA_ "Description" SG_ 2348810507 TP_L_DHRL_FD_BDC_FD_Byte28 "TP Index : 275";
BA_ "Version" SG_ 2348810507 TP_L_DHRL_FD_BDC_FD_Byte29 "23.06.01";
BA_ "NetworkRequestHoldingTime" SG_ 2348810507 TP_L_DHRL_FD_BDC_FD_Byte29 5000;
BA_ "NetworkRequest" SG_ 2348810507 TP_L_DHRL_FD_BDC_FD_Byte29 0;
BA_ "UserSigValidity" SG_ 2348810507 TP_L_DHRL_FD_BDC_FD_Byte29 0;
BA_ "UsrSigPurpose" SG_ 2348810507 TP_L_DHRL_FD_BDC_FD_Byte29 9;
BA_ "Description" SG_ 2348810507 TP_L_DHRL_FD_BDC_FD_Byte29 "TP Index : 275";
BA_ "Version" SG_ 2348810507 TP_L_DHRL_FD_BDC_FD_Byte3 "23.06.01";
BA_ "NetworkRequestHoldingTime" SG_ 2348810507 TP_L_DHRL_FD_BDC_FD_Byte3 5000;
BA_ "NetworkRequest" SG_ 2348810507 TP_L_DHRL_FD_BDC_FD_Byte3 0;
BA_ "UserSigValidity" SG_ 2348810507 TP_L_DHRL_FD_BDC_FD_Byte3 0;
BA_ "UsrSigPurpose" SG_ 2348810507 TP_L_DHRL_FD_BDC_FD_Byte3 9;
BA_ "Description" SG_ 2348810507 TP_L_DHRL_FD_BDC_FD_Byte3 "TP Index : 275";
BA_ "Version" SG_ 2348810507 TP_L_DHRL_FD_BDC_FD_Byte30 "23.06.01";
BA_ "NetworkRequestHoldingTime" SG_ 2348810507 TP_L_DHRL_FD_BDC_FD_Byte30 5000;
BA_ "NetworkRequest" SG_ 2348810507 TP_L_DHRL_FD_BDC_FD_Byte30 0;
BA_ "UserSigValidity" SG_ 2348810507 TP_L_DHRL_FD_BDC_FD_Byte30 0;
BA_ "UsrSigPurpose" SG_ 2348810507 TP_L_DHRL_FD_BDC_FD_Byte30 9;
BA_ "Description" SG_ 2348810507 TP_L_DHRL_FD_BDC_FD_Byte30 "TP Index : 275";
BA_ "Version" SG_ 2348810507 TP_L_DHRL_FD_BDC_FD_Byte31 "23.06.01";
BA_ "NetworkRequestHoldingTime" SG_ 2348810507 TP_L_DHRL_FD_BDC_FD_Byte31 5000;
BA_ "NetworkRequest" SG_ 2348810507 TP_L_DHRL_FD_BDC_FD_Byte31 0;
BA_ "UserSigValidity" SG_ 2348810507 TP_L_DHRL_FD_BDC_FD_Byte31 0;
BA_ "UsrSigPurpose" SG_ 2348810507 TP_L_DHRL_FD_BDC_FD_Byte31 9;
BA_ "Description" SG_ 2348810507 TP_L_DHRL_FD_BDC_FD_Byte31 "TP Index : 275";
BA_ "Version" SG_ 2348810507 TP_L_DHRL_FD_BDC_FD_Byte4 "23.06.01";
BA_ "NetworkRequestHoldingTime" SG_ 2348810507 TP_L_DHRL_FD_BDC_FD_Byte4 5000;
BA_ "NetworkRequest" SG_ 2348810507 TP_L_DHRL_FD_BDC_FD_Byte4 0;
BA_ "UserSigValidity" SG_ 2348810507 TP_L_DHRL_FD_BDC_FD_Byte4 0;
BA_ "UsrSigPurpose" SG_ 2348810507 TP_L_DHRL_FD_BDC_FD_Byte4 9;
BA_ "Description" SG_ 2348810507 TP_L_DHRL_FD_BDC_FD_Byte4 "TP Index : 275";
BA_ "Version" SG_ 2348810507 TP_L_DHRL_FD_BDC_FD_Byte5 "23.06.01";
BA_ "NetworkRequestHoldingTime" SG_ 2348810507 TP_L_DHRL_FD_BDC_FD_Byte5 5000;
BA_ "NetworkRequest" SG_ 2348810507 TP_L_DHRL_FD_BDC_FD_Byte5 0;
BA_ "UserSigValidity" SG_ 2348810507 TP_L_DHRL_FD_BDC_FD_Byte5 0;
BA_ "UsrSigPurpose" SG_ 2348810507 TP_L_DHRL_FD_BDC_FD_Byte5 9;
BA_ "Description" SG_ 2348810507 TP_L_DHRL_FD_BDC_FD_Byte5 "TP Index : 275";
BA_ "Version" SG_ 2348810507 TP_L_DHRL_FD_BDC_FD_Byte6 "23.06.01";
BA_ "NetworkRequestHoldingTime" SG_ 2348810507 TP_L_DHRL_FD_BDC_FD_Byte6 5000;
BA_ "NetworkRequest" SG_ 2348810507 TP_L_DHRL_FD_BDC_FD_Byte6 0;
BA_ "UserSigValidity" SG_ 2348810507 TP_L_DHRL_FD_BDC_FD_Byte6 0;
BA_ "UsrSigPurpose" SG_ 2348810507 TP_L_DHRL_FD_BDC_FD_Byte6 9;
BA_ "Description" SG_ 2348810507 TP_L_DHRL_FD_BDC_FD_Byte6 "TP Index : 275";
BA_ "Version" SG_ 2348810507 TP_L_DHRL_FD_BDC_FD_Byte7 "23.06.01";
BA_ "NetworkRequestHoldingTime" SG_ 2348810507 TP_L_DHRL_FD_BDC_FD_Byte7 5000;
BA_ "NetworkRequest" SG_ 2348810507 TP_L_DHRL_FD_BDC_FD_Byte7 0;
BA_ "UserSigValidity" SG_ 2348810507 TP_L_DHRL_FD_BDC_FD_Byte7 0;
BA_ "UsrSigPurpose" SG_ 2348810507 TP_L_DHRL_FD_BDC_FD_Byte7 9;
BA_ "Description" SG_ 2348810507 TP_L_DHRL_FD_BDC_FD_Byte7 "TP Index : 275";
BA_ "Version" SG_ 2348810507 TP_L_DHRL_FD_BDC_FD_Byte8 "23.06.01";
BA_ "NetworkRequestHoldingTime" SG_ 2348810507 TP_L_DHRL_FD_BDC_FD_Byte8 5000;
BA_ "NetworkRequest" SG_ 2348810507 TP_L_DHRL_FD_BDC_FD_Byte8 0;
BA_ "UserSigValidity" SG_ 2348810507 TP_L_DHRL_FD_BDC_FD_Byte8 0;
BA_ "UsrSigPurpose" SG_ 2348810507 TP_L_DHRL_FD_BDC_FD_Byte8 9;
BA_ "Description" SG_ 2348810507 TP_L_DHRL_FD_BDC_FD_Byte8 "TP Index : 275";
BA_ "Version" SG_ 2348810507 TP_L_DHRL_FD_BDC_FD_Byte9 "23.06.01";
BA_ "NetworkRequestHoldingTime" SG_ 2348810507 TP_L_DHRL_FD_BDC_FD_Byte9 5000;
BA_ "NetworkRequest" SG_ 2348810507 TP_L_DHRL_FD_BDC_FD_Byte9 0;
BA_ "UserSigValidity" SG_ 2348810507 TP_L_DHRL_FD_BDC_FD_Byte9 0;
BA_ "UsrSigPurpose" SG_ 2348810507 TP_L_DHRL_FD_BDC_FD_Byte9 9;
BA_ "Description" SG_ 2348810507 TP_L_DHRL_FD_BDC_FD_Byte9 "TP Index : 275";
BA_ "Version" SG_ 2348810507 TP_L_DHRL_FD_BDC_FD_Byte1 "23.06.01";
BA_ "NetworkRequestHoldingTime" SG_ 2348810507 TP_L_DHRL_FD_BDC_FD_Byte1 5000;
BA_ "NetworkRequest" SG_ 2348810507 TP_L_DHRL_FD_BDC_FD_Byte1 0;
BA_ "UserSigValidity" SG_ 2348810507 TP_L_DHRL_FD_BDC_FD_Byte1 0;
BA_ "UsrSigPurpose" SG_ 2348810507 TP_L_DHRL_FD_BDC_FD_Byte1 9;
BA_ "Description" SG_ 2348810507 TP_L_DHRL_FD_BDC_FD_Byte1 "TP Index : 275";
BA_ "Version" SG_ 2348810507 TP_L_DHRL_FD_BDC_FD_Byte10 "23.06.01";
BA_ "NetworkRequestHoldingTime" SG_ 2348810507 TP_L_DHRL_FD_BDC_FD_Byte10 5000;
BA_ "NetworkRequest" SG_ 2348810507 TP_L_DHRL_FD_BDC_FD_Byte10 0;
BA_ "UserSigValidity" SG_ 2348810507 TP_L_DHRL_FD_BDC_FD_Byte10 0;
BA_ "UsrSigPurpose" SG_ 2348810507 TP_L_DHRL_FD_BDC_FD_Byte10 9;
BA_ "Description" SG_ 2348810507 TP_L_DHRL_FD_BDC_FD_Byte10 "TP Index : 275";
BA_ "Version" SG_ 2348810507 TP_L_DHRL_FD_BDC_FD_Byte11 "23.06.01";
BA_ "NetworkRequestHoldingTime" SG_ 2348810507 TP_L_DHRL_FD_BDC_FD_Byte11 5000;
BA_ "NetworkRequest" SG_ 2348810507 TP_L_DHRL_FD_BDC_FD_Byte11 0;
BA_ "UserSigValidity" SG_ 2348810507 TP_L_DHRL_FD_BDC_FD_Byte11 0;
BA_ "UsrSigPurpose" SG_ 2348810507 TP_L_DHRL_FD_BDC_FD_Byte11 9;
BA_ "Description" SG_ 2348810507 TP_L_DHRL_FD_BDC_FD_Byte11 "TP Index : 275";
BA_ "Version" SG_ 2348810507 TP_L_DHRL_FD_BDC_FD_Byte12 "23.06.01";
BA_ "NetworkRequestHoldingTime" SG_ 2348810507 TP_L_DHRL_FD_BDC_FD_Byte12 5000;
BA_ "NetworkRequest" SG_ 2348810507 TP_L_DHRL_FD_BDC_FD_Byte12 0;
BA_ "UserSigValidity" SG_ 2348810507 TP_L_DHRL_FD_BDC_FD_Byte12 0;
BA_ "UsrSigPurpose" SG_ 2348810507 TP_L_DHRL_FD_BDC_FD_Byte12 9;
BA_ "Description" SG_ 2348810507 TP_L_DHRL_FD_BDC_FD_Byte12 "TP Index : 275";
BA_REL_ "GenSigTimeoutTime" BU_SG_REL_ GW_BDC_FD SG_ 2214592722 UWB_FR_Ranging_Enc_Result2 0;
BA_REL_ "GenSigTimeoutTime" BU_SG_REL_ L_UWB_BLE_MST_FD SG_ 2214592722 UWB_FR_Ranging_Enc_Result2 0;
BA_REL_ "GenSigTimeoutTime" BU_SG_REL_ GW_BDC_FD SG_ 2214592722 UWB_FR_Ranging_Enc_Result 0;
BA_REL_ "GenSigTimeoutTime" BU_SG_REL_ L_UWB_BLE_MST_FD SG_ 2214592722 UWB_FR_Ranging_Enc_Result 0;
BA_REL_ "GenSigTimeoutTime" BU_SG_REL_ L_EDT_FD SG_ 2214592714 MST_DisconnectDKID 0;
BA_REL_ "GenSigTimeoutTime" BU_SG_REL_ L_EDT_FD SG_ 2214592714 MST_DisconnectReason 0;
BA_REL_ "GenSigTimeoutTime" BU_SG_REL_ L_EDT_FD SG_ 2214592714 MST_BLE_ErrorReturn 0;
BA_REL_ "GenSigTimeoutTime" BU_SG_REL_ L_UWB_BLE_SLV_FD SG_ 2214592714 MST_BLE_ErrorReturn 0;
BA_REL_ "GenSigTimeoutTime" BU_SG_REL_ L_EDT_FD SG_ 2214592719 UWB_FL_Dvp_Data 0;
BA_REL_ "GenSigTimeoutTime" BU_SG_REL_ L_UWB_BLE_MST_FD SG_ 2521143553 SLV_SWID_4_IVD_1 0;
BA_REL_ "GenSigTimeoutTime" BU_SG_REL_ GW_BDC_FD SG_ 2214592705 UWB_FL_FOB_RSD_Enc_Result 0;
BA_REL_ "GenSigTimeoutTime" BU_SG_REL_ GW_BDC_FD SG_ 2214592704 UWB_FL_UWB_Decrypt_FB 0;
BA_REL_ "GenSigTimeoutTime" BU_SG_REL_ L_UWB_BLE_MST_FD SG_ 2214592704 UWB_FL_MST_Decrypt_FB 0;
BA_REL_ "GenSigTimeoutTime" BU_SG_REL_ L_UWB_BLE_MST_FD SG_ 2214592704 UWB_FL_OTA_Rsp 0;
BA_REL_ "GenSigTimeoutTime" BU_SG_REL_ L_EDT_FD SG_ 2214592704 UWB_FL_UWB_IC_Status 0;
BA_REL_ "GenSigTimeoutTime" BU_SG_REL_ GW_BDC_FD SG_ 2214592706 UWB_FL_Ranging_Enc_Result2 0;
BA_REL_ "GenSigTimeoutTime" BU_SG_REL_ L_UWB_BLE_MST_FD SG_ 2214592706 UWB_FL_Ranging_Enc_Result2 0;
BA_REL_ "GenSigTimeoutTime" BU_SG_REL_ GW_BDC_FD SG_ 2214592706 UWB_FL_Ranging_Enc_Result 0;
BA_REL_ "GenSigTimeoutTime" BU_SG_REL_ L_UWB_BLE_MST_FD SG_ 2214592706 UWB_FL_Ranging_Enc_Result 0;
BA_REL_ "GenSigTimeoutTime" BU_SG_REL_ L_UWB_BLE_MST_FD SG_ 2525339649 FL_SWID_3_IVD_1 0;
BA_REL_ "GenSigTimeoutTime" BU_SG_REL_ L_EDT_FD SG_ 2214592767 UWB_RL_Dvp_Data 0;
BA_REL_ "GenSigTimeoutTime" BU_SG_REL_ GW_BDC_FD SG_ 2214592754 UWB_RL_Ranging_Enc_Result2 0;
BA_REL_ "GenSigTimeoutTime" BU_SG_REL_ L_UWB_BLE_MST_FD SG_ 2214592754 UWB_RL_Ranging_Enc_Result2 0;
BA_REL_ "GenSigTimeoutTime" BU_SG_REL_ GW_BDC_FD SG_ 2214592754 UWB_RL_Ranging_Enc_Result 0;
BA_REL_ "GenSigTimeoutTime" BU_SG_REL_ L_UWB_BLE_MST_FD SG_ 2214592754 UWB_RL_Ranging_Enc_Result 0;
BA_REL_ "GenSigTimeoutTime" BU_SG_REL_ GW_BDC_FD SG_ 2214592752 UWB_RL_UWB_Decrypt_FB 0;
BA_REL_ "GenSigTimeoutTime" BU_SG_REL_ L_UWB_BLE_MST_FD SG_ 2214592752 UWB_RL_MST_Decrypt_FB 0;
BA_REL_ "GenSigTimeoutTime" BU_SG_REL_ L_UWB_BLE_MST_FD SG_ 2214592752 UWB_RL_OTA_Rsp 0;
BA_REL_ "GenSigTimeoutTime" BU_SG_REL_ L_EDT_FD SG_ 2214592752 UWB_RL_UWB_IC_Status 0;
BA_REL_ "GenSigTimeoutTime" BU_SG_REL_ GW_BDC_FD SG_ 2214592753 UWB_RL_FOB_RSD_Enc_Result 0;
BA_REL_ "GenSigTimeoutTime" BU_SG_REL_ L_SAL_FD SG_ 187 Lamp_FootLampCmd 0;
BA_REL_ "GenSigTimeoutTime" BU_SG_REL_ L_EDT_FD SG_ 2214592751 UWB_FRNK_Dvp_Data 0;
BA_REL_ "GenSigTimeoutTime" BU_SG_REL_ GW_BDC_FD SG_ 2214592738 UWB_FRNK_Ranging_Enc_Result2 0;
BA_REL_ "GenSigTimeoutTime" BU_SG_REL_ L_UWB_BLE_MST_FD SG_ 2214592738 UWB_FRNK_Ranging_Enc_Result2 0;
BA_REL_ "GenSigTimeoutTime" BU_SG_REL_ GW_BDC_FD SG_ 2214592738 UWB_FRNK_Ranging_Enc_Result 0;
BA_REL_ "GenSigTimeoutTime" BU_SG_REL_ L_UWB_BLE_MST_FD SG_ 2214592738 UWB_FRNK_Ranging_Enc_Result 0;
BA_REL_ "GenSigTimeoutTime" BU_SG_REL_ GW_BDC_FD SG_ 2214592737 UWB_FRNK_FOB_RSD_Enc_Result 0;
BA_REL_ "GenSigTimeoutTime" BU_SG_REL_ GW_BDC_FD SG_ 2214592736 UWB_FRNK_UWB_Decrypt_FB 0;
BA_REL_ "GenSigTimeoutTime" BU_SG_REL_ L_UWB_BLE_MST_FD SG_ 2214592736 UWB_FRNK_MST_Decrypt_FB 0;
BA_REL_ "GenSigTimeoutTime" BU_SG_REL_ L_UWB_BLE_MST_FD SG_ 2214592736 UWB_FRNK_OTA_Rsp 0;
BA_REL_ "GenSigTimeoutTime" BU_SG_REL_ L_EDT_FD SG_ 2214592736 UWB_FRNK_UWB_IC_Status 0;
BA_REL_ "GenSigTimeoutTime" BU_SG_REL_ GW_BDC_FD SG_ 2348810509 TP_L_DHRR_FD_BDC_FD_Byte0 0;
BA_REL_ "GenSigTimeoutTime" BU_SG_REL_ GW_BDC_FD SG_ 2348810509 TP_L_DHRR_FD_BDC_FD_Byte13 0;
BA_REL_ "GenSigTimeoutTime" BU_SG_REL_ GW_BDC_FD SG_ 2348810509 TP_L_DHRR_FD_BDC_FD_Byte14 0;
BA_REL_ "GenSigTimeoutTime" BU_SG_REL_ GW_BDC_FD SG_ 2348810509 TP_L_DHRR_FD_BDC_FD_Byte15 0;
BA_REL_ "GenSigTimeoutTime" BU_SG_REL_ GW_BDC_FD SG_ 2348810509 TP_L_DHRR_FD_BDC_FD_Byte16 0;
BA_REL_ "GenSigTimeoutTime" BU_SG_REL_ GW_BDC_FD SG_ 2348810509 TP_L_DHRR_FD_BDC_FD_Byte17 0;
BA_REL_ "GenSigTimeoutTime" BU_SG_REL_ GW_BDC_FD SG_ 2348810509 TP_L_DHRR_FD_BDC_FD_Byte18 0;
BA_REL_ "GenSigTimeoutTime" BU_SG_REL_ GW_BDC_FD SG_ 2348810509 TP_L_DHRR_FD_BDC_FD_Byte19 0;
BA_REL_ "GenSigTimeoutTime" BU_SG_REL_ GW_BDC_FD SG_ 2348810509 TP_L_DHRR_FD_BDC_FD_Byte2 0;
BA_REL_ "GenSigTimeoutTime" BU_SG_REL_ GW_BDC_FD SG_ 2348810509 TP_L_DHRR_FD_BDC_FD_Byte20 0;
BA_REL_ "GenSigTimeoutTime" BU_SG_REL_ GW_BDC_FD SG_ 2348810509 TP_L_DHRR_FD_BDC_FD_Byte21 0;
BA_REL_ "GenSigTimeoutTime" BU_SG_REL_ GW_BDC_FD SG_ 2348810509 TP_L_DHRR_FD_BDC_FD_Byte22 0;
BA_REL_ "GenSigTimeoutTime" BU_SG_REL_ GW_BDC_FD SG_ 2348810509 TP_L_DHRR_FD_BDC_FD_Byte23 0;
BA_REL_ "GenSigTimeoutTime" BU_SG_REL_ GW_BDC_FD SG_ 2348810509 TP_L_DHRR_FD_BDC_FD_Byte24 0;
BA_REL_ "GenSigTimeoutTime" BU_SG_REL_ GW_BDC_FD SG_ 2348810509 TP_L_DHRR_FD_BDC_FD_Byte25 0;
BA_REL_ "GenSigTimeoutTime" BU_SG_REL_ GW_BDC_FD SG_ 2348810509 TP_L_DHRR_FD_BDC_FD_Byte26 0;
BA_REL_ "GenSigTimeoutTime" BU_SG_REL_ GW_BDC_FD SG_ 2348810509 TP_L_DHRR_FD_BDC_FD_Byte27 0;
BA_REL_ "GenSigTimeoutTime" BU_SG_REL_ GW_BDC_FD SG_ 2348810509 TP_L_DHRR_FD_BDC_FD_Byte28 0;
BA_REL_ "GenSigTimeoutTime" BU_SG_REL_ GW_BDC_FD SG_ 2348810509 TP_L_DHRR_FD_BDC_FD_Byte29 0;
BA_REL_ "GenSigTimeoutTime" BU_SG_REL_ GW_BDC_FD SG_ 2348810509 TP_L_DHRR_FD_BDC_FD_Byte3 0;
BA_REL_ "GenSigTimeoutTime" BU_SG_REL_ GW_BDC_FD SG_ 2348810509 TP_L_DHRR_FD_BDC_FD_Byte30 0;
BA_REL_ "GenSigTimeoutTime" BU_SG_REL_ GW_BDC_FD SG_ 2348810509 TP_L_DHRR_FD_BDC_FD_Byte31 0;
BA_REL_ "GenSigTimeoutTime" BU_SG_REL_ GW_BDC_FD SG_ 2348810509 TP_L_DHRR_FD_BDC_FD_Byte4 0;
BA_REL_ "GenSigTimeoutTime" BU_SG_REL_ GW_BDC_FD SG_ 2348810509 TP_L_DHRR_FD_BDC_FD_Byte5 0;
BA_REL_ "GenSigTimeoutTime" BU_SG_REL_ GW_BDC_FD SG_ 2348810509 TP_L_DHRR_FD_BDC_FD_Byte6 0;
BA_REL_ "GenSigTimeoutTime" BU_SG_REL_ GW_BDC_FD SG_ 2348810509 TP_L_DHRR_FD_BDC_FD_Byte7 0;
BA_REL_ "GenSigTimeoutTime" BU_SG_REL_ GW_BDC_FD SG_ 2348810509 TP_L_DHRR_FD_BDC_FD_Byte8 0;
BA_REL_ "GenSigTimeoutTime" BU_SG_REL_ GW_BDC_FD SG_ 2348810509 TP_L_DHRR_FD_BDC_FD_Byte9 0;
BA_REL_ "GenSigTimeoutTime" BU_SG_REL_ GW_BDC_FD SG_ 2348810509 TP_L_DHRR_FD_BDC_FD_Byte1 0;
BA_REL_ "GenSigTimeoutTime" BU_SG_REL_ GW_BDC_FD SG_ 2348810509 TP_L_DHRR_FD_BDC_FD_Byte10 0;
BA_REL_ "GenSigTimeoutTime" BU_SG_REL_ GW_BDC_FD SG_ 2348810509 TP_L_DHRR_FD_BDC_FD_Byte11 0;
BA_REL_ "GenSigTimeoutTime" BU_SG_REL_ GW_BDC_FD SG_ 2348810509 TP_L_DHRR_FD_BDC_FD_Byte12 0;
BA_REL_ "GenSigTimeoutTime" BU_SG_REL_ L_DHL_FD SG_ 745 PDC_FD_Crc15Val 1500;
BA_REL_ "GenSigTimeoutTime" BU_SG_REL_ L_DHRL_FD SG_ 745 PDC_FD_Crc15Val 1500;
BA_REL_ "GenSigTimeoutTime" BU_SG_REL_ L_DHRR_FD SG_ 745 PDC_FD_Crc15Val 1500;
BA_REL_ "GenSigTimeoutTime" BU_SG_REL_ L_DHR_FD SG_ 745 PDC_FD_Crc15Val 1500;
BA_REL_ "GenSigTimeoutTime" BU_SG_REL_ L_EDT_FD SG_ 745 PDC_FD_Crc15Val 1500;
BA_REL_ "GenSigTimeoutTime" BU_SG_REL_ L_ROA_FD SG_ 745 PDC_FD_Crc15Val 1500;
BA_REL_ "GenSigTimeoutTime" BU_SG_REL_ L_ROA_FR_FD SG_ 745 PDC_FD_Crc15Val 1500;
BA_REL_ "GenSigTimeoutTime" BU_SG_REL_ L_SAL_FD SG_ 745 PDC_FD_Crc15Val 1500;
BA_REL_ "GenSigTimeoutTime" BU_SG_REL_ L_TPMS_FD SG_ 745 PDC_FD_Crc15Val 1500;
BA_REL_ "GenSigTimeoutTime" BU_SG_REL_ L_UWB_BLE_MST_FD SG_ 745 PDC_FD_Crc15Val 1500;
BA_REL_ "GenSigTimeoutTime" BU_SG_REL_ L_UWB_BLE_SLV_FD SG_ 745 PDC_FD_Crc15Val 1500;
BA_REL_ "GenSigTimeoutTime" BU_SG_REL_ L_UWB_FL_FD SG_ 745 PDC_FD_Crc15Val 1500;
BA_REL_ "GenSigTimeoutTime" BU_SG_REL_ L_UWB_FRNK_FD SG_ 745 PDC_FD_Crc15Val 1500;
BA_REL_ "GenSigTimeoutTime" BU_SG_REL_ L_UWB_FR_FD SG_ 745 PDC_FD_Crc15Val 1500;
BA_REL_ "GenSigTimeoutTime" BU_SG_REL_ L_UWB_RL_FD SG_ 745 PDC_FD_Crc15Val 1500;
BA_REL_ "GenSigTimeoutTime" BU_SG_REL_ L_UWB_RR_FD SG_ 745 PDC_FD_Crc15Val 1500;
BA_REL_ "GenSigTimeoutTime" BU_SG_REL_ L_UWB_TRNK_FD SG_ 745 PDC_FD_Crc15Val 1500;
BA_REL_ "GenSigTimeoutTime" BU_SG_REL_ L_WPC_FD SG_ 745 PDC_FD_Crc15Val 1500;
BA_REL_ "GenSigTimeoutTime" BU_SG_REL_ L_DHL_FD SG_ 745 PDC_FD_AlvCnt15Val 1500;
BA_REL_ "GenSigTimeoutTime" BU_SG_REL_ L_DHRL_FD SG_ 745 PDC_FD_AlvCnt15Val 1500;
BA_REL_ "GenSigTimeoutTime" BU_SG_REL_ L_DHRR_FD SG_ 745 PDC_FD_AlvCnt15Val 1500;
BA_REL_ "GenSigTimeoutTime" BU_SG_REL_ L_DHR_FD SG_ 745 PDC_FD_AlvCnt15Val 1500;
BA_REL_ "GenSigTimeoutTime" BU_SG_REL_ L_EDT_FD SG_ 745 PDC_FD_AlvCnt15Val 1500;
BA_REL_ "GenSigTimeoutTime" BU_SG_REL_ L_ROA_FD SG_ 745 PDC_FD_AlvCnt15Val 1500;
BA_REL_ "GenSigTimeoutTime" BU_SG_REL_ L_ROA_FR_FD SG_ 745 PDC_FD_AlvCnt15Val 1500;
BA_REL_ "GenSigTimeoutTime" BU_SG_REL_ L_SAL_FD SG_ 745 PDC_FD_AlvCnt15Val 1500;
BA_REL_ "GenSigTimeoutTime" BU_SG_REL_ L_TPMS_FD SG_ 745 PDC_FD_AlvCnt15Val 1500;
BA_REL_ "GenSigTimeoutTime" BU_SG_REL_ L_UWB_BLE_MST_FD SG_ 745 PDC_FD_AlvCnt15Val 1500;
BA_REL_ "GenSigTimeoutTime" BU_SG_REL_ L_UWB_BLE_SLV_FD SG_ 745 PDC_FD_AlvCnt15Val 1500;
BA_REL_ "GenSigTimeoutTime" BU_SG_REL_ L_UWB_FL_FD SG_ 745 PDC_FD_AlvCnt15Val 1500;
BA_REL_ "GenSigTimeoutTime" BU_SG_REL_ L_UWB_FRNK_FD SG_ 745 PDC_FD_AlvCnt15Val 1500;
BA_REL_ "GenSigTimeoutTime" BU_SG_REL_ L_UWB_FR_FD SG_ 745 PDC_FD_AlvCnt15Val 1500;
BA_REL_ "GenSigTimeoutTime" BU_SG_REL_ L_UWB_RL_FD SG_ 745 PDC_FD_AlvCnt15Val 1500;
BA_REL_ "GenSigTimeoutTime" BU_SG_REL_ L_UWB_RR_FD SG_ 745 PDC_FD_AlvCnt15Val 1500;
BA_REL_ "GenSigTimeoutTime" BU_SG_REL_ L_UWB_TRNK_FD SG_ 745 PDC_FD_AlvCnt15Val 1500;
BA_REL_ "GenSigTimeoutTime" BU_SG_REL_ L_WPC_FD SG_ 745 PDC_FD_AlvCnt15Val 1500;
BA_REL_ "GenSigTimeoutTime" BU_SG_REL_ L_DHL_FD SG_ 745 PDC_ResetPreWrngForOthers_Copy_0 1500;
BA_REL_ "GenSigTimeoutTime" BU_SG_REL_ L_DHRL_FD SG_ 745 PDC_ResetPreWrngForOthers_Copy_0 1500;
BA_REL_ "GenSigTimeoutTime" BU_SG_REL_ L_DHRR_FD SG_ 745 PDC_ResetPreWrngForOthers_Copy_0 1500;
BA_REL_ "GenSigTimeoutTime" BU_SG_REL_ L_DHR_FD SG_ 745 PDC_ResetPreWrngForOthers_Copy_0 1500;
BA_REL_ "GenSigTimeoutTime" BU_SG_REL_ L_EDT_FD SG_ 745 PDC_ResetPreWrngForOthers_Copy_0 1500;
BA_REL_ "GenSigTimeoutTime" BU_SG_REL_ L_ROA_FD SG_ 745 PDC_ResetPreWrngForOthers_Copy_0 1500;
BA_REL_ "GenSigTimeoutTime" BU_SG_REL_ L_ROA_FR_FD SG_ 745 PDC_ResetPreWrngForOthers_Copy_0 1500;
BA_REL_ "GenSigTimeoutTime" BU_SG_REL_ L_SAL_FD SG_ 745 PDC_ResetPreWrngForOthers_Copy_0 1500;
BA_REL_ "GenSigTimeoutTime" BU_SG_REL_ L_TPMS_FD SG_ 745 PDC_ResetPreWrngForOthers_Copy_0 1500;
BA_REL_ "GenSigTimeoutTime" BU_SG_REL_ L_UWB_BLE_MST_FD SG_ 745 PDC_ResetPreWrngForOthers_Copy_0 1500;
BA_REL_ "GenSigTimeoutTime" BU_SG_REL_ L_UWB_BLE_SLV_FD SG_ 745 PDC_ResetPreWrngForOthers_Copy_0 1500;
BA_REL_ "GenSigTimeoutTime" BU_SG_REL_ L_UWB_FL_FD SG_ 745 PDC_ResetPreWrngForOthers_Copy_0 1500;
BA_REL_ "GenSigTimeoutTime" BU_SG_REL_ L_UWB_FRNK_FD SG_ 745 PDC_ResetPreWrngForOthers_Copy_0 1500;
BA_REL_ "GenSigTimeoutTime" BU_SG_REL_ L_UWB_FR_FD SG_ 745 PDC_ResetPreWrngForOthers_Copy_0 1500;
BA_REL_ "GenSigTimeoutTime" BU_SG_REL_ L_UWB_RL_FD SG_ 745 PDC_ResetPreWrngForOthers_Copy_0 1500;
BA_REL_ "GenSigTimeoutTime" BU_SG_REL_ L_UWB_RR_FD SG_ 745 PDC_ResetPreWrngForOthers_Copy_0 1500;
BA_REL_ "GenSigTimeoutTime" BU_SG_REL_ L_UWB_TRNK_FD SG_ 745 PDC_ResetPreWrngForOthers_Copy_0 1500;
BA_REL_ "GenSigTimeoutTime" BU_SG_REL_ L_WPC_FD SG_ 745 PDC_ResetPreWrngForOthers_Copy_0 1500;
BA_REL_ "GenSigTimeoutTime" BU_SG_REL_ L_DHL_FD SG_ 745 PDC_ResetReqForOthers_Copy_0 1500;
BA_REL_ "GenSigTimeoutTime" BU_SG_REL_ L_DHRL_FD SG_ 745 PDC_ResetReqForOthers_Copy_0 1500;
BA_REL_ "GenSigTimeoutTime" BU_SG_REL_ L_DHRR_FD SG_ 745 PDC_ResetReqForOthers_Copy_0 1500;
BA_REL_ "GenSigTimeoutTime" BU_SG_REL_ L_DHR_FD SG_ 745 PDC_ResetReqForOthers_Copy_0 1500;
BA_REL_ "GenSigTimeoutTime" BU_SG_REL_ L_EDT_FD SG_ 745 PDC_ResetReqForOthers_Copy_0 1500;
BA_REL_ "GenSigTimeoutTime" BU_SG_REL_ L_ROA_FD SG_ 745 PDC_ResetReqForOthers_Copy_0 1500;
BA_REL_ "GenSigTimeoutTime" BU_SG_REL_ L_ROA_FR_FD SG_ 745 PDC_ResetReqForOthers_Copy_0 1500;
BA_REL_ "GenSigTimeoutTime" BU_SG_REL_ L_SAL_FD SG_ 745 PDC_ResetReqForOthers_Copy_0 1500;
BA_REL_ "GenSigTimeoutTime" BU_SG_REL_ L_TPMS_FD SG_ 745 PDC_ResetReqForOthers_Copy_0 1500;
BA_REL_ "GenSigTimeoutTime" BU_SG_REL_ L_UWB_BLE_MST_FD SG_ 745 PDC_ResetReqForOthers_Copy_0 1500;
BA_REL_ "GenSigTimeoutTime" BU_SG_REL_ L_UWB_BLE_SLV_FD SG_ 745 PDC_ResetReqForOthers_Copy_0 1500;
BA_REL_ "GenSigTimeoutTime" BU_SG_REL_ L_UWB_FL_FD SG_ 745 PDC_ResetReqForOthers_Copy_0 1500;
BA_REL_ "GenSigTimeoutTime" BU_SG_REL_ L_UWB_FRNK_FD SG_ 745 PDC_ResetReqForOthers_Copy_0 1500;
BA_REL_ "GenSigTimeoutTime" BU_SG_REL_ L_UWB_FR_FD SG_ 745 PDC_ResetReqForOthers_Copy_0 1500;
BA_REL_ "GenSigTimeoutTime" BU_SG_REL_ L_UWB_RL_FD SG_ 745 PDC_ResetReqForOthers_Copy_0 1500;
BA_REL_ "GenSigTimeoutTime" BU_SG_REL_ L_UWB_RR_FD SG_ 745 PDC_ResetReqForOthers_Copy_0 1500;
BA_REL_ "GenSigTimeoutTime" BU_SG_REL_ L_UWB_TRNK_FD SG_ 745 PDC_ResetReqForOthers_Copy_0 1500;
BA_REL_ "GenSigTimeoutTime" BU_SG_REL_ L_WPC_FD SG_ 745 PDC_ResetReqForOthers_Copy_0 1500;
BA_REL_ "GenSigTimeoutTime" BU_SG_REL_ L_ROA_FD SG_ 745 PDC_ResetFuncOpt_Copy_0 1500;
BA_REL_ "GenSigTimeoutTime" BU_SG_REL_ L_ROA_FR_FD SG_ 745 PDC_ResetFuncOpt_Copy_0 1500;
BA_REL_ "GenSigTimeoutTime" BU_SG_REL_ L_TPMS_FD SG_ 745 PDC_ResetFuncOpt_Copy_0 1500;
BA_REL_ "GenSigTimeoutTime" BU_SG_REL_ L_UWB_BLE_MST_FD SG_ 745 PDC_ResetFuncOpt_Copy_0 1500;
BA_REL_ "GenSigTimeoutTime" BU_SG_REL_ L_UWB_BLE_SLV_FD SG_ 745 PDC_ResetFuncOpt_Copy_0 1500;
BA_REL_ "GenSigTimeoutTime" BU_SG_REL_ L_UWB_FL_FD SG_ 745 PDC_ResetFuncOpt_Copy_0 1500;
BA_REL_ "GenSigTimeoutTime" BU_SG_REL_ L_UWB_FRNK_FD SG_ 745 PDC_ResetFuncOpt_Copy_0 1500;
BA_REL_ "GenSigTimeoutTime" BU_SG_REL_ L_UWB_FR_FD SG_ 745 PDC_ResetFuncOpt_Copy_0 1500;
BA_REL_ "GenSigTimeoutTime" BU_SG_REL_ L_UWB_RL_FD SG_ 745 PDC_ResetFuncOpt_Copy_0 1500;
BA_REL_ "GenSigTimeoutTime" BU_SG_REL_ L_UWB_RR_FD SG_ 745 PDC_ResetFuncOpt_Copy_0 1500;
BA_REL_ "GenSigTimeoutTime" BU_SG_REL_ L_UWB_TRNK_FD SG_ 745 PDC_ResetFuncOpt_Copy_0 1500;
BA_REL_ "GenSigTimeoutTime" BU_SG_REL_ L_DHRR_FD SG_ 2348810508 TP_BDC_FD_L_DHRR_FD_Byte0 0;
BA_REL_ "GenSigTimeoutTime" BU_SG_REL_ L_DHRR_FD SG_ 2348810508 TP_BDC_FD_L_DHRR_FD_Byte13 0;
BA_REL_ "GenSigTimeoutTime" BU_SG_REL_ L_DHRR_FD SG_ 2348810508 TP_BDC_FD_L_DHRR_FD_Byte14 0;
BA_REL_ "GenSigTimeoutTime" BU_SG_REL_ L_DHRR_FD SG_ 2348810508 TP_BDC_FD_L_DHRR_FD_Byte15 0;
BA_REL_ "GenSigTimeoutTime" BU_SG_REL_ L_DHRR_FD SG_ 2348810508 TP_BDC_FD_L_DHRR_FD_Byte16 0;
BA_REL_ "GenSigTimeoutTime" BU_SG_REL_ L_DHRR_FD SG_ 2348810508 TP_BDC_FD_L_DHRR_FD_Byte17 0;
BA_REL_ "GenSigTimeoutTime" BU_SG_REL_ L_DHRR_FD SG_ 2348810508 TP_BDC_FD_L_DHRR_FD_Byte18 0;
BA_REL_ "GenSigTimeoutTime" BU_SG_REL_ L_DHRR_FD SG_ 2348810508 TP_BDC_FD_L_DHRR_FD_Byte19 0;
BA_REL_ "GenSigTimeoutTime" BU_SG_REL_ L_DHRR_FD SG_ 2348810508 TP_BDC_FD_L_DHRR_FD_Byte2 0;
BA_REL_ "GenSigTimeoutTime" BU_SG_REL_ L_DHRR_FD SG_ 2348810508 TP_BDC_FD_L_DHRR_FD_Byte20 0;
BA_REL_ "GenSigTimeoutTime" BU_SG_REL_ L_DHRR_FD SG_ 2348810508 TP_BDC_FD_L_DHRR_FD_Byte21 0;
BA_REL_ "GenSigTimeoutTime" BU_SG_REL_ L_DHRR_FD SG_ 2348810508 TP_BDC_FD_L_DHRR_FD_Byte22 0;
BA_REL_ "GenSigTimeoutTime" BU_SG_REL_ L_DHRR_FD SG_ 2348810508 TP_BDC_FD_L_DHRR_FD_Byte23 0;
BA_REL_ "GenSigTimeoutTime" BU_SG_REL_ L_DHRR_FD SG_ 2348810508 TP_BDC_FD_L_DHRR_FD_Byte24 0;
BA_REL_ "GenSigTimeoutTime" BU_SG_REL_ L_DHRR_FD SG_ 2348810508 TP_BDC_FD_L_DHRR_FD_Byte25 0;
BA_REL_ "GenSigTimeoutTime" BU_SG_REL_ L_DHRR_FD SG_ 2348810508 TP_BDC_FD_L_DHRR_FD_Byte26 0;
BA_REL_ "GenSigTimeoutTime" BU_SG_REL_ L_DHRR_FD SG_ 2348810508 TP_BDC_FD_L_DHRR_FD_Byte27 0;
BA_REL_ "GenSigTimeoutTime" BU_SG_REL_ L_DHRR_FD SG_ 2348810508 TP_BDC_FD_L_DHRR_FD_Byte28 0;
BA_REL_ "GenSigTimeoutTime" BU_SG_REL_ L_DHRR_FD SG_ 2348810508 TP_BDC_FD_L_DHRR_FD_Byte29 0;
BA_REL_ "GenSigTimeoutTime" BU_SG_REL_ L_DHRR_FD SG_ 2348810508 TP_BDC_FD_L_DHRR_FD_Byte3 0;
BA_REL_ "GenSigTimeoutTime" BU_SG_REL_ L_DHRR_FD SG_ 2348810508 TP_BDC_FD_L_DHRR_FD_Byte30 0;
BA_REL_ "GenSigTimeoutTime" BU_SG_REL_ L_DHRR_FD SG_ 2348810508 TP_BDC_FD_L_DHRR_FD_Byte31 0;
BA_REL_ "GenSigTimeoutTime" BU_SG_REL_ L_DHRR_FD SG_ 2348810508 TP_BDC_FD_L_DHRR_FD_Byte4 0;
BA_REL_ "GenSigTimeoutTime" BU_SG_REL_ L_DHRR_FD SG_ 2348810508 TP_BDC_FD_L_DHRR_FD_Byte5 0;
BA_REL_ "GenSigTimeoutTime" BU_SG_REL_ L_DHRR_FD SG_ 2348810508 TP_BDC_FD_L_DHRR_FD_Byte6 0;
BA_REL_ "GenSigTimeoutTime" BU_SG_REL_ L_DHRR_FD SG_ 2348810508 TP_BDC_FD_L_DHRR_FD_Byte7 0;
BA_REL_ "GenSigTimeoutTime" BU_SG_REL_ L_DHRR_FD SG_ 2348810508 TP_BDC_FD_L_DHRR_FD_Byte8 0;
BA_REL_ "GenSigTimeoutTime" BU_SG_REL_ L_DHRR_FD SG_ 2348810508 TP_BDC_FD_L_DHRR_FD_Byte9 0;
BA_REL_ "GenSigTimeoutTime" BU_SG_REL_ L_DHRR_FD SG_ 2348810508 TP_BDC_FD_L_DHRR_FD_Byte1 0;
BA_REL_ "GenSigTimeoutTime" BU_SG_REL_ L_DHRR_FD SG_ 2348810508 TP_BDC_FD_L_DHRR_FD_Byte10 0;
BA_REL_ "GenSigTimeoutTime" BU_SG_REL_ L_DHRR_FD SG_ 2348810508 TP_BDC_FD_L_DHRR_FD_Byte11 0;
BA_REL_ "GenSigTimeoutTime" BU_SG_REL_ L_DHRR_FD SG_ 2348810508 TP_BDC_FD_L_DHRR_FD_Byte12 0;
BA_REL_ "GenSigTimeoutTime" BU_SG_REL_ GW_BDC_FD SG_ 2348810507 TP_L_DHRL_FD_BDC_FD_Byte0 0;
BA_REL_ "GenSigTimeoutTime" BU_SG_REL_ GW_BDC_FD SG_ 2348810507 TP_L_DHRL_FD_BDC_FD_Byte13 0;
BA_REL_ "GenSigTimeoutTime" BU_SG_REL_ GW_BDC_FD SG_ 2348810507 TP_L_DHRL_FD_BDC_FD_Byte14 0;
BA_REL_ "GenSigTimeoutTime" BU_SG_REL_ GW_BDC_FD SG_ 2348810507 TP_L_DHRL_FD_BDC_FD_Byte15 0;
BA_REL_ "GenSigTimeoutTime" BU_SG_REL_ GW_BDC_FD SG_ 2348810507 TP_L_DHRL_FD_BDC_FD_Byte16 0;
BA_REL_ "GenSigTimeoutTime" BU_SG_REL_ GW_BDC_FD SG_ 2348810507 TP_L_DHRL_FD_BDC_FD_Byte17 0;
BA_REL_ "GenSigTimeoutTime" BU_SG_REL_ GW_BDC_FD SG_ 2348810507 TP_L_DHRL_FD_BDC_FD_Byte18 0;
BA_REL_ "GenSigTimeoutTime" BU_SG_REL_ GW_BDC_FD SG_ 2348810507 TP_L_DHRL_FD_BDC_FD_Byte19 0;
BA_REL_ "GenSigTimeoutTime" BU_SG_REL_ GW_BDC_FD SG_ 2348810507 TP_L_DHRL_FD_BDC_FD_Byte2 0;
BA_REL_ "GenSigTimeoutTime" BU_SG_REL_ GW_BDC_FD SG_ 2348810507 TP_L_DHRL_FD_BDC_FD_Byte20 0;
BA_REL_ "GenSigTimeoutTime" BU_SG_REL_ GW_BDC_FD SG_ 2348810507 TP_L_DHRL_FD_BDC_FD_Byte21 0;
BA_REL_ "GenSigTimeoutTime" BU_SG_REL_ GW_BDC_FD SG_ 2348810507 TP_L_DHRL_FD_BDC_FD_Byte22 0;
BA_REL_ "GenSigTimeoutTime" BU_SG_REL_ GW_BDC_FD SG_ 2348810507 TP_L_DHRL_FD_BDC_FD_Byte23 0;
BA_REL_ "GenSigTimeoutTime" BU_SG_REL_ GW_BDC_FD SG_ 2348810507 TP_L_DHRL_FD_BDC_FD_Byte24 0;
BA_REL_ "GenSigTimeoutTime" BU_SG_REL_ GW_BDC_FD SG_ 2348810507 TP_L_DHRL_FD_BDC_FD_Byte25 0;
BA_REL_ "GenSigTimeoutTime" BU_SG_REL_ GW_BDC_FD SG_ 2348810507 TP_L_DHRL_FD_BDC_FD_Byte26 0;
BA_REL_ "GenSigTimeoutTime" BU_SG_REL_ GW_BDC_FD SG_ 2348810507 TP_L_DHRL_FD_BDC_FD_Byte27 0;
BA_REL_ "GenSigTimeoutTime" BU_SG_REL_ GW_BDC_FD SG_ 2348810507 TP_L_DHRL_FD_BDC_FD_Byte28 0;
BA_REL_ "GenSigTimeoutTime" BU_SG_REL_ GW_BDC_FD SG_ 2348810507 TP_L_DHRL_FD_BDC_FD_Byte29 0;
BA_REL_ "GenSigTimeoutTime" BU_SG_REL_ GW_BDC_FD SG_ 2348810507 TP_L_DHRL_FD_BDC_FD_Byte3 0;
BA_REL_ "GenSigTimeoutTime" BU_SG_REL_ GW_BDC_FD SG_ 2348810507 TP_L_DHRL_FD_BDC_FD_Byte30 0;
BA_REL_ "GenSigTimeoutTime" BU_SG_REL_ GW_BDC_FD SG_ 2348810507 TP_L_DHRL_FD_BDC_FD_Byte31 0;
BA_REL_ "GenSigTimeoutTime" BU_SG_REL_ GW_BDC_FD SG_ 2348810507 TP_L_DHRL_FD_BDC_FD_Byte4 0;
BA_REL_ "GenSigTimeoutTime" BU_SG_REL_ GW_BDC_FD SG_ 2348810507 TP_L_DHRL_FD_BDC_FD_Byte5 0;
BA_REL_ "GenSigTimeoutTime" BU_SG_REL_ GW_BDC_FD SG_ 2348810507 TP_L_DHRL_FD_BDC_FD_Byte6 0;
BA_REL_ "GenSigTimeoutTime" BU_SG_REL_ GW_BDC_FD SG_ 2348810507 TP_L_DHRL_FD_BDC_FD_Byte7 0;
BA_REL_ "GenSigTimeoutTime" BU_SG_REL_ GW_BDC_FD SG_ 2348810507 TP_L_DHRL_FD_BDC_FD_Byte8 0;
BA_REL_ "GenSigTimeoutTime" BU_SG_REL_ GW_BDC_FD SG_ 2348810507 TP_L_DHRL_FD_BDC_FD_Byte9 0;
BA_REL_ "GenSigTimeoutTime" BU_SG_REL_ GW_BDC_FD SG_ 2348810507 TP_L_DHRL_FD_BDC_FD_Byte1 0;
BA_REL_ "GenSigTimeoutTime" BU_SG_REL_ GW_BDC_FD SG_ 2348810507 TP_L_DHRL_FD_BDC_FD_Byte10 0;
BA_REL_ "GenSigTimeoutTime" BU_SG_REL_ GW_BDC_FD SG_ 2348810507 TP_L_DHRL_FD_BDC_FD_Byte11 0;
BA_REL_ "GenSigTimeoutTime" BU_SG_REL_ GW_BDC_FD SG_ 2348810507 TP_L_DHRL_FD_BDC_FD_Byte12 0;
VAL_ 2214592722 L_UWB_FR_FD_Crc3Val 0 "0x0x0~0xFFFF:CRCValue" 65535 "0x0x0~0xFFFF:CRCValue" ;
VAL_ 2214592722 L_UWB_FR_FD_AlvCnt3Val 0 "0x0x0~0xFF:AlvCntValue" 255 "0x0x0~0xFF:AlvCntValue" ;
VAL_ 2214592714 L_UWB_BLE_MST_FD_Crc22Val 0 "0x0x0~0xFFFF:CRCValue" 65535 "0x0x0~0xFFFF:CRCValue" ;
VAL_ 2214592714 L_UWB_BLE_MST_FD_AlvCnt22Val 0 "0x0x0~0xFF:AlvCntValue" 255 "0x0x0~0xFF:AlvCntValue" ;
VAL_ 2214592714 MST_DisconnectDKID 0 "0x0x0~0xFF:DK ID" 255 "0x0x0~0xFF:DK ID" ;
VAL_ 2214592714 MST_DisconnectReason 0 "Default" 1 "L2CAP Creation Fail" 2 "OP RQ Not_Received" 3 "New Device Timeout" 4 "SMP Pairing Fail" 5 "DK Local Termination" 6 "Delete All and IRK Update" 7 "Disconnected by device" 8 "Supervision Timeout" 9 "Other reasons" ;
VAL_ 2521143553 L_UWB_BLE_SLV_FD_Crc13Val 0 "0x0x0~0xFFFF:CRCValue" 65535 "0x0x0~0xFFFF:CRCValue" ;
VAL_ 2521143553 L_UWB_BLE_SLV_FD_AlvCnt13Val 0 "0x0x0~0xFF:AlvCntValue" 255 "0x0x0~0xFF:AlvCntValue" ;
VAL_ 2214592705 L_UWB_FL_FD_Crc2Val 0 "0x0x0~0xFFFF:CRCValue" 65535 "0x0x0~0xFFFF:CRCValue" ;
VAL_ 2214592705 L_UWB_FL_FD_AlvCnt2Val 0 "0x0x0~0xFF:AlvCntValue" 255 "0x0x0~0xFF:AlvCntValue" ;
VAL_ 2214592704 L_UWB_FL_FD_Crc1Val 0 "0x0x0~0xFFFF:CRCValue" 65535 "0x0x0~0xFFFF:CRCValue" ;
VAL_ 2214592704 L_UWB_FL_FD_AlvCnt1Val 0 "0x0x0~0xFF:AlvCntValue" 255 "0x0x0~0xFF:AlvCntValue" ;
VAL_ 2214592704 UWB_FL_UWB_Decrypt_FB 0 "Default" 1 "Positive" 2 "Negative" 3 "RESERVED" 4 "RESERVED" 5 "RESERVED" 6 "RESERVED" 7 "RESERVED" 8 "RESERVED" 9 "RESERVED" 10 "RESERVED" 11 "RESERVED" 12 "RESERVED" 13 "RESERVED" 14 "RESERVED" 15 "RESERVED" ;
VAL_ 2214592704 UWB_FL_MST_Decrypt_FB 0 "Default" 1 "Positive" 2 "Negative" 3 "RESERVED" 4 "RESERVED" 5 "RESERVED" 6 "RESERVED" 7 "RESERVED" 8 "RESERVED" 9 "RESERVED" 10 "RESERVED" 11 "RESERVED" 12 "RESERVED" 13 "RESERVED" 14 "RESERVED" 15 "RESERVED" ;
VAL_ 2214592704 UWB_FL_OTA_Rsp 0 "Default" 1 "Request_Success" 2 "Request_Fail" 3 "Erase_Success" 4 "Erase_Fail" 5 "RESERVED" 6 "RESERVED" 7 "Verify_Success" 8 "Verify_Fail" 9 "RESERVED" 10 "RESERVED" 11 "Pause_Response" 12 "RESERVED" 13 "RESERVED" 14 "RESERVED" 15 "RESERVED" ;
VAL_ 2214592704 UWB_FL_UWB_IC_Status 0 "Status_OK" 1 "Status_Rejected" 2 "Status_Failed" 3 "Status_Syntax_Error" 4 "Status_Invalid_Param" 5 "Status_Invalid_Range" 6 "Status_Invalid_Message" 7 "Status_Unknow_GID" 8 "Status_Unknow_OID" 9 "Status_Read_Only" 10 "Status_Com_Retry" 11 "RESERVED" 12 "RESERVED" 13 "RESERVED" 14 "RESERVED" 15 "RESERVED" 17 "Session_Not_Exist" 18 "Session_Duplicate" 19 "Session_Active" 20 "Session_Max" 21 "Session_Not_Config" 22 "Session_Ongonig" 23 "RESERVED" 24 "RESERVED" 25 "RESERVED" 26 "Error_Slot_Len" 27 "Error_Slot_Per_RR" 28 "Error_STS_IDX" 29 "RESERVED" 30 "RESERVED" 31 "RESERVED" 32 "RESERVED" 33 "Init_Rejected" 34 "Init_Failed" 35 "Start_Rejected" 36 "Start_Failed" 37 "0x25~0xFF:RESERVED" 255 "0x25~0xFF:RESERVED" ;
VAL_ 2214592706 L_UWB_FL_FD_Crc3Val 0 "0x0x0~0xFFFF:CRCValue" 65535 "0x0x0~0xFFFF:CRCValue" ;
VAL_ 2214592706 L_UWB_FL_FD_AlvCnt3Val 0 "0x0x0~0xFF:AlvCntValue" 255 "0x0x0~0xFF:AlvCntValue" ;
VAL_ 2525339649 L_UWB_FL_FD_Crc4Val 0 "0x0x0~0xFFFF:CRCValue" 65535 "0x0x0~0xFFFF:CRCValue" ;
VAL_ 2525339649 L_UWB_FL_FD_AlvCnt4Val 0 "0x0x0~0xFF:AlvCntValue" 255 "0x0x0~0xFF:AlvCntValue" ;
VAL_ 2214592754 L_UWB_RL_FD_Crc3Val 0 "0x0x0~0xFFFF:CRCValue" 65535 "0x0x0~0xFFFF:CRCValue" ;
VAL_ 2214592754 L_UWB_RL_FD_AlvCnt3Val 0 "0x0x0~0xFF:AlvCntValue" 255 "0x0x0~0xFF:AlvCntValue" ;
VAL_ 2214592752 L_UWB_RL_FD_Crc1Val 0 "0x0x0~0xFFFF:CRCValue" 65535 "0x0x0~0xFFFF:CRCValue" ;
VAL_ 2214592752 L_UWB_RL_FD_AlvCnt1Val 0 "0x0x0~0xFF:AlvCntValue" 255 "0x0x0~0xFF:AlvCntValue" ;
VAL_ 2214592752 UWB_RL_UWB_Decrypt_FB 0 "Default" 1 "Positive" 2 "Negative" 3 "RESERVED" 4 "RESERVED" 5 "RESERVED" 6 "RESERVED" 7 "RESERVED" 8 "RESERVED" 9 "RESERVED" 10 "RESERVED" 11 "RESERVED" 12 "RESERVED" 13 "RESERVED" 14 "RESERVED" 15 "RESERVED" ;
VAL_ 2214592752 UWB_RL_MST_Decrypt_FB 0 "Default" 1 "Positive" 2 "Negative" 3 "RESERVED" 4 "RESERVED" 5 "RESERVED" 6 "RESERVED" 7 "RESERVED" 8 "RESERVED" 9 "RESERVED" 10 "RESERVED" 11 "RESERVED" 12 "RESERVED" 13 "RESERVED" 14 "RESERVED" 15 "RESERVED" ;
VAL_ 2214592752 UWB_RL_OTA_Rsp 0 "Default" 1 "Request_Success" 2 "Request_Fail" 3 "Erase_Success" 4 "Erase_Fail" 5 "RESERVED" 6 "RESERVED" 7 "Verify_Success" 8 "Verify_Fail" 9 "RESERVED" 10 "RESERVED" 11 "Pause_Response" 12 "RESERVED" 13 "RESERVED" 14 "RESERVED" 15 "RESERVED" ;
VAL_ 2214592752 UWB_RL_UWB_IC_Status 0 "Status_OK" 1 "Status_Rejected" 2 "Status_Failed" 3 "Status_Syntax_Error" 4 "Status_Invalid_Param" 5 "Status_Invalid_Range" 6 "Status_Invalid_Message" 7 "Status_Unknow_GID" 8 "Status_Unknow_OID" 9 "Status_Read_Only" 10 "Status_Com_Retry" 11 "RESERVED" 12 "RESERVED" 13 "RESERVED" 14 "RESERVED" 15 "RESERVED" 17 "Session_Not_Exist" 18 "Session_Duplicate" 19 "Session_Active" 20 "Session_Max" 21 "Session_Not_Config" 22 "Session_Ongonig" 23 "RESERVED" 24 "RESERVED" 25 "RESERVED" 26 "Error_Slot_Len" 27 "Error_Slot_Per_RR" 28 "Error_STS_IDX" 29 "RESERVED" 30 "RESERVED" 31 "RESERVED" 32 "RESERVED" 33 "Init_Rejected" 34 "Init_Failed" 35 "Start_Rejected" 36 "Start_Failed" 37 "0x25~0xFF:RESERVED" 255 "0x25~0xFF:RESERVED" ;
VAL_ 2214592753 L_UWB_RL_FD_Crc2Val 0 "0x0x0~0xFFFF:CRCValue" 65535 "0x0x0~0xFFFF:CRCValue" ;
VAL_ 2214592753 L_UWB_RL_FD_AlvCnt2Val 0 "0x0x0~0xFF:AlvCntValue" 255 "0x0x0~0xFF:AlvCntValue" ;
VAL_ 187 BDC_FD_Crc1Val 0 "0x0x0~0xFFFF:CRCValue" 65535 "0x0x0~0xFFFF:CRCValue" ;
VAL_ 187 Ast_AutoRlxWrngDis_Copy_0 0 "Off" 1 "Auto relax Enable" 2 "Mode-Fail (Vehicle Speed Warning)" 3 "Mode-Fail (Not P Warning)" 4 "Mode-Fail (2nd Seat Belted)" 5 "Mode-Fail (Not Initialized)" 6 "Mode-Fail (2nd Seat Position Warning)" 7 "Invaild" ;
VAL_ 187 RLPSU_FailState_PopUp_Copy_0 0 "Default" 1 "Relax Mode Position" 2 "Return Mode Position" 3 "Monitor Mode Position" 4 "Reading Mode Position" 5 "1st Seat Moving" 6 "1st Seat RePositioning" 7 "3rd Seat Moving" 8 "3rd Seat RePositioning" 9 "Mode-Fail (1st Seat Condition)" 10 "Mode-Fail (Side Sliding Limit SW Condition)" 11 "Mode-Fail (Vehicle Condition)" 12 "Mode-Fail (3rd Seat Condition)" 13 "Mode-Fail (Anti-Pinch)" 14 "Mode-Fail (Seat System Error)" 15 "Invalid" ;
VAL_ 187 RRPSU_FailState_PopUp_Copy_0 0 "Default" 1 "Relax Mode Position" 2 "Retrun Mode Position" 3 "Monitor Mode Position" 4 "Reading Mode Position" 5 "1st Seat Moving" 6 "1st Seat RePositioning" 7 "3rd Seat Moving" 8 "3rd Seat RePositioning" 9 "Mode-Fail (1st Seat Condition)" 10 "Mode-Fail (Side Sliding Limit SW Unlocked)" 11 "Mode-Fail (Vehicle Condition)Mode-Fail (Vehicle Condition)" 12 "Mode-Fail (3rd Seat Condition)" 13 "Mode-Fail (Anti-Pinch)Mode-Fail (Anti-Pinch)" 14 "Mode-Fail (Seat System Error)" 15 "Invalid" ;
VAL_ 187 Pseat_AllSeatIMSMemoryDelReq 0 "Off" 1 "DeleteMemory" 2 "RESERVED" 3 "Error Indicator" ;
VAL_ 187 PSeat_RLVIPRelaxionMemoryDelReq 0 "Off" 1 "DeleteRelaxMemory" 2 "DeleteReturnMemory" 3 "DeleteReadMemory" 4 "DeleteWatchMemory" 5 "RESERVED" 6 "RESERVED" 7 "Error Indicator" ;
VAL_ 187 PSeat_RRVIPRelaxionMemoryDelReq 0 "Off" 1 "DeleteRelaxMemory" 2 "DeleteReturnMemory" 3 "DeleteReadMemory" 4 "DeleteWatchMemory" 5 "RESERVED" 6 "RESERVED" 7 "Error Indicator" ;
VAL_ 187 Lamp_FrunkLampCmd 0 "None" 1 "Off" 2 "LongOn" 3 "SteadyOn" ;
VAL_ 187 Lamp_DrvCourtesyLampCmd 0 "None" 1 "Off" 2 "LongOn" 3 "SteadyOn" ;
VAL_ 187 Lamp_AstCourtesyLampCmd 0 "None" 1 "Off" 2 "LongOn" 3 "SteadyOn" ;
VAL_ 187 Lamp_RLCourtesyLampCmd 0 "None" 1 "Off" 2 "LongOn" 3 "SteadyOn" ;
VAL_ 187 Lamp_RRCourtesyLampCmd 0 "None" 1 "Off" 2 "LongOn" 3 "SteadyOn" ;
VAL_ 187 Lamp_RoomLampCmd 0 "None" 1 "Off" 2 "ShortOn" 3 "LongOn" 4 "SteadyOn" 5 "Not Used" 6 "Not Used" 7 "Error Indicator" ;
VAL_ 187 Lamp_FootLampCmd 0 "None" 1 "Off" 2 "Short1On" 3 "Short2On" 4 "SteadyOn" 5 "Short3DimOut" 6 "SteadyDimOut" 7 "LongAnyDoorOpen" 8 "SteadyAnyDoorOpen" 9 "Not Used" 10 "Not Used" 11 "Not Used" 12 "Not Used" 13 "Not Used" 14 "Not Used" 15 "Error Indicator" ;
VAL_ 187 PFSU_3LAMPBzrReq_Copy_0 0 "Off" 1 "On" 2 "Not Used" 3 "Error Indicator" ;
VAL_ 187 PFSU_3RAMPBzrReq_Copy_0 0 "Off" 1 "On" 2 "Not Used" 3 "Error Indicator" ;
VAL_ 187 Drv_AutoRlxWrngDis_2_Copy_0 0 "Off" 1 "2nd Seat Moving" 2 "2nd Seat Repositioning" 3 "RESERVED" 4 "RESERVED" 5 "RESERVED" 6 "RESERVED" 7 "Invalid" ;
VAL_ 187 Ast_AutoRlxWrngDis_2_Copy_0 0 "Off" 1 "2nd Seat Moving" 2 "2nd Seat Repositioning" 3 "RESERVED" 4 "RESERVED" 5 "RESERVED" 6 "RESERVED" 7 "Invaild" ;
VAL_ 187 RLPSU_Folding_State_Popup_EC_Cop 0 "Default" 1 "Folded(Finished)" 2 "Unfolded(Finished)" 3 "Mode-Fail(Anti-Pinch)" 4 "Mode-Fail(TGS&Break Condition)" 5 "Mode-Fail(System Error)" 6 "Mode-Fail(Vehicle Speed Warning)" 7 "Invalid" ;
VAL_ 187 RRPSU_Folding_State_Popup_EC_Cop 0 "Default" 1 "Folded(Finished)" 2 "Unfolded(Finished)" 3 "Mode-Fail(Anti-Pinch)" 4 "Mode-Fail(TGS&Break Condition)" 5 "Mode-Fail(System Error)" 6 "Mode-Fail(Vehicle Speed Warning)" 7 "Invalid" ;
VAL_ 187 C_LH_Folding_State_PopUp_Copy_0 0 "Default" 1 "Folded (Finished)" 2 "Unfolded (Finished)" 3 "Mode-Fail (Anti-Pinch)" 4 "Mode-Fail (TGS & Break Condition)" 5 "Mode-Fail (System Error)" 6 "Mode-Fail(Vehicle Speed Warning)" 7 "Invalid" ;
VAL_ 187 C_RH_Folding_State_PopUp_Copy_0 0 "Default" 1 "Folded (Finish)" 2 "UnFolded (Finish)" 3 "Mode-Fail (Anti-Pinch)" 4 "Mode-Fail (TGS & Break Condition)" 5 "Mode-Fail (System Error)" 6 "Mode-Fail(Vehicle Speed Warning)" 7 "Invalid" ;
VAL_ 187 C_RH_Folding_State_PopUp_2_Copy_ 0 "Default" 1 "2nd Seat Moving" 2 "2nd Seat RePositioning" 3 "RESERVED" 4 "RESERVED" 5 "RESERVED" 6 "RESERVED" 7 "Invalid" ;
VAL_ 187 BDC_FD_AlvCnt1Val 0 "0x0x0~0xFF:AlvCntValue" 255 "0x0x0~0xFF:AlvCntValue" ;
VAL_ 187 C_LH_Folding_State_PopUp_2_Copy_ 0 "Default" 1 "2nd Seat Moving" 2 "2nd Seat RePositioning" 3 "RESERVED" 4 "RESERVED" 5 "RESERVED" 6 "RESERVED" 7 "Invalid" ;
VAL_ 187 Swivel_UtilModeSetReq 0 "Default" 1 "Rest Mode Off(Not Used)" 2 "Rest Mode On" 3 "Invalid" ;
VAL_ 187 PSeat_SecondRLTiltWalkInDisReq 0 "Default" 1 "SeatUnlocked Warning" 2 "RESERVED" 3 "Invalid" ;
VAL_ 187 PSeat_SecondRRTiltWalkInDisReq 0 "Default" 1 "SeatUnlocked Warning" 2 "Resesrved" 3 "Invalid" ;
VAL_ 187 PSeat_DrvLegrestOSDDisReq 0 "Default" 1 "Vehicle Speed Warning" 2 "Not P Warning" 3 "RESERVED" 4 "RESERVED" 5 "RESERVED" 6 "RESERVED" 7 "Invalid" ;
VAL_ 187 PHEV_FuelDrWakeupSta_Copy_0 0 "OFF" 1 "ON" 2 "Not Used" 3 "Error Indicator" ;
VAL_ 187 MoodLamp_MLSingleBrghtModCmd 0 "None" 1 "Off" 2 "ShortOn" 3 "LongOn" 4 "SteadyOn" 5 "RESERVED" 6 "RESERVED" 7 "Invalid" ;
VAL_ 187 MoodLamp_SingleBrghtVal 0 "None" 1 "Off" 2 "Step1" 3 "Step2" 4 "Step3" 5 "Step4" 6 "Step1Night" 7 "Step2Night" 8 "Step3Night" 9 "Step4Night" 10 "RESERVED" 11 "RESERVED" 12 "RESERVED" 13 "RESERVED" 14 "RESERVED" 15 "Invalid" ;
VAL_ 187 PSeat_AstReturnMemoryCmd 0 "Off" 1 "Return" 2 "RESERVED" 3 "Error Indicator" ;
VAL_ 187 Swivel_AVNPlayConfirmReq 0 "Off" 1 "On" 2 "Not Used" 3 "Error Indicator" ;
VAL_ 187 Swivel_AVNDrvPopUpDisReq 0 "Default" 1 "PopUp1" 2 "PopUp2" 3 "PopUp3" 4 "PopUp4" 5 "PopUp5" 6 "PopUp6" 7 "PopUp7" 8 "PopUp8" 9 "PopUp9" 10 "PopUp10" 11 "PopUp11" 12 "PopUp12" 13 "PopUp13" 14 "PopUp14" 15 "Invalid" ;
VAL_ 187 Swivel_AVNAstPopUpDisReq 0 "Default" 1 "PopUp1" 2 "PopUp2" 3 "PopUp3" 4 "PopUp4" 5 "PopUp5" 6 "PopUp6" 7 "PopUp7" 8 "PopUp8" 9 "PopUp9" 10 "PopUp10" 11 "PopUp11" 12 "PopUp12" 13 "PopUp13" 14 "PopUp14" 15 "Invalid" ;
VAL_ 187 Swivel_AVNDrvOSDDisReq 0 "Default" 1 "OSD1" 2 "OSD2" 3 "OSD3" 4 "OSD4" 5 "OSD5" 6 "OSD6" 7 "OSD7" 8 "OSD8" 9 "OSD9" 10 "OSD10" 11 "OSD11" 12 "OSD12" 13 "OSD13" 14 "OSD14" 15 "Invalid" ;
VAL_ 187 Swivel_AVNAstOSDDisReq 0 "Default" 1 "OSD1" 2 "OSD2" 3 "OSD3" 4 "OSD4" 5 "OSD5" 6 "OSD6" 7 "OSD7" 8 "OSD8" 9 "OSD9" 10 "OSD10" 11 "OSD11" 12 "OSD12" 13 "OSD13" 14 "OSD14" 15 "Invalid" ;
VAL_ 187 Swivel_CTSPlayConfirmReq 0 "Off" 1 "On" 2 "Not Used" 3 "Error Indicator" ;
VAL_ 187 Swivel_CTSDrvPopUpDisReq 0 "Default" 1 "PopUp1" 2 "PopUp2" 3 "PopUp3" 4 "PopUp4" 5 "PopUp5" 6 "PopUp6" 7 "PopUp7" 8 "PopUp8" 9 "PopUp9" 10 "PopUp10" 11 "PopUp11" 12 "PopUp12" 13 "PopUp13" 14 "PopUp14" 15 "Invalid" ;
VAL_ 187 Swivel_CTSAstPopUpDisReq 0 "Default" 1 "PopUp1" 2 "PopUp2" 3 "PopUp3" 4 "PopUp4" 5 "PopUp5" 6 "PopUp6" 7 "PopUp7" 8 "PopUp8" 9 "PopUp9" 10 "PopUp10" 11 "PopUp11" 12 "PopUp12" 13 "PopUp13" 14 "PopUp14" 15 "Invalid" ;
VAL_ 187 Swivel_CTSDrvOSDDisReq 0 "Default" 1 "OSD1" 2 "OSD2" 3 "OSD3" 4 "OSD4" 5 "OSD5" 6 "OSD6" 7 "OSD7" 8 "OSD8" 9 "OSD9" 10 "OSD10" 11 "OSD11" 12 "OSD12" 13 "OSD13" 14 "OSD14" 15 "Invalid" ;
VAL_ 187 Swivel_CTSAstOSDDisReq 0 "Default" 1 "OSD1" 2 "OSD2" 3 "OSD3" 4 "OSD4" 5 "OSD5" 6 "OSD6" 7 "OSD7" 8 "OSD8" 9 "OSD9" 10 "OSD10" 11 "OSD11" 12 "OSD12" 13 "OSD13" 14 "OSD14" 15 "Invalid" ;
VAL_ 187 PSeat_AllFoldUnfoldOSDDisReq 0 "Default" 1 "OSD1" 2 "OSD2" 3 "OSD3" 4 "OSD4" 5 "OSD5" 6 "OSD6" 7 "OSD7" 8 "OSD8" 9 "OSD9" 10 "OSD10" 11 "OSD11" 12 "OSD12" 13 "OSD13" 14 "OSD14" 15 "Invalid" ;
VAL_ 187 DrvIMS_MemorySetEnaSta_Copy_0 0 "Disable" 1 "Enable" 2 "Not Used" 3 "Error Indicator" ;
VAL_ 187 C_LH_Folding_State_PopUp_CTS 0 "Default" 1 "Folded (Finished)" 2 "Unfolded (Finished)" 3 "Mode-Fail (Anti-Pinch)" 4 "Mode-Fail (TGS & Break Condition)" 5 "Mode-Fail (System Error)" 6 "Mode-Fail(Vehicle Speed Warning)" 7 "Invalid" ;
VAL_ 187 C_LH_Folding_State_PopUp_2_CTS 0 "Default" 1 "2nd Seat Moving" 2 "2nd Seat RePositioning" 3 "RESERVED" 4 "RESERVED" 5 "RESERVED" 6 "RESERVED" 7 "Invalid" ;
VAL_ 187 PHEV_FuelDrReleaseSwSta_Copy_0 0 "Off" 1 "On" 2 "Not Used" 3 "Error Indicator" ;
VAL_ 187 C_RH_Folding_State_PopUp_CTS 0 "Default" 1 "Folded (Finish)" 2 "UnFolded (Finish)" 3 "Mode-Fail (Anti-Pinch)" 4 "Mode-Fail (TGS & Break Condition)" 5 "Mode-Fail (System Error)" 6 "Mode-Fail(Vehicle Speed Warning)" 7 "Invalid" ;
VAL_ 187 C_RH_Folding_State_PopUp_2_CTS 0 "Default" 1 "2nd Seat Moving" 2 "2nd Seat RePositioning" 3 "RESERVED" 4 "RESERVED" 5 "RESERVED" 6 "RESERVED" 7 "Invalid" ;
VAL_ 187 PSeat_AllFoldUnfoldOSDDisReq_CTS 0 "Default" 1 "OSD1" 2 "OSD2" 3 "OSD3" 4 "OSD4" 5 "OSD5" 6 "OSD6" 7 "OSD7" 8 "OSD8" 9 "OSD9" 10 "OSD10" 11 "OSD11" 12 "OSD12" 13 "OSD13" 14 "OSD14" 15 "Invalid" ;
VAL_ 187 StrWhlWrmr_MKBDBpReq_Copy_0 0 "Beep Off" 1 "Beep On" 2 "Not Used" 3 "Error Indicator" ;
VAL_ 187 BckGls_RrGlsHtdMKBDBpReq_Copy_0 0 "Beep Off" 1 "Beep On" 2 "Not Used" 3 "Error Indicator" ;
VAL_ 187 Wndshld_FrtGlsHtdMKBDBpReq_Copy_ 0 "Beep Off" 1 "Beep On" 2 "Not Used" 3 "Error Indicator" ;
VAL_ 187 BAlarm_AutoLockrReq_Copy_0 0 "Off" 1 "Lock" 2 "Not Used" 3 "Error Indicator" ;
VAL_ 187 RLPSU_FailState_PopUp_CTS 0 "Default" 1 "Relax Mode Position" 2 "Return Mode Position" 3 "Monitor Mode Position" 4 "Reading Mode Position" 5 "1st Seat Moving" 6 "1st Seat RePositioning" 7 "3rd Seat Moving" 8 "3rd Seat RePositioning" 9 "Mode-Fail (1st Seat Condition)" 10 "Mode-Fail (Side Sliding Limit SW Condition)" 11 "Mode-Fail (Vehicle Condition)" 12 "Mode-Fail (3rd Seat Condition)" 13 "Mode-Fail (Anti-Pinch)" 14 "Mode-Fail (Seat System Error)" 15 "Invalid" ;
VAL_ 187 RLPSU_Folding_State_Popup_CTS 0 "Default" 1 "Folded(Finished)" 2 "Unfolded(Finished)" 3 "Mode-Fail(Anti-Pinch)" 4 "Mode-Fail(TGS&Break Condition)" 5 "Mode-Fail(System Error)" 6 "Mode-Fail(Vehicle Speed Warning)" 7 "Invalid" ;
VAL_ 187 RRPSU_FailState_PopUp_CTS 0 "Default" 1 "Relax Mode Position" 2 "Retrun Mode Position" 3 "Monitor Mode Position" 4 "Reading Mode Position" 5 "1st Seat Moving" 6 "1st Seat RePositioning" 7 "3rd Seat Moving" 8 "3rd Seat RePositioning" 9 "Mode-Fail (1st Seat Condition)" 10 "Mode-Fail (Side Sliding Limit SW Unlocked)" 11 "Mode-Fail (Vehicle Condition)Mode-Fail (Vehicle Condition)" 12 "Mode-Fail (3rd Seat Condition)" 13 "Mode-Fail (Anti-Pinch)Mode-Fail (Anti-Pinch)" 14 "Mode-Fail (Seat System Error)" 15 "Invalid" ;
VAL_ 187 RRPSU_Folding_State_Popup_CTS 0 "Default" 1 "Folded(Finished)" 2 "Unfolded(Finished)" 3 "Mode-Fail(Anti-Pinch)" 4 "Mode-Fail(TGS&Break Condition)" 5 "Mode-Fail(System Error)" 6 "Mode-Fail(Vehicle Speed Warning)" 7 "Invalid" ;
VAL_ 187 DrvIMS_AMPBzrReq_Copy_0 0 "Off" 1 "On (LHD)" 2 "On (RHD)" 3 "Error Indicator" ;
VAL_ 187 AstIMS_AMPBzrReq_Copy_0 0 "Off" 1 "On (LHD)" 2 "On (RHD)" 3 "Error Indicator" ;
VAL_ 187 RLIMS_AMPBzrReq_Copy_0 0 "Off" 1 "On" 2 "Not Used" 3 "Error Indicator" ;
VAL_ 187 RRIMS_AMPBzrReq_Copy_0 0 "Off" 1 "On" 2 "Not Used" 3 "Error Indicator" ;
VAL_ 187 DrvIMS_BzrReq_Copy_0 0 "Off" 1 "On" 2 "Not Used" 3 "Error Indicator" ;
VAL_ 187 DrvIMS_ErrConWmgDis_Copy_0 0 "Off" 1 "On" 2 "Not Used" 3 "Error Indicator" ;
VAL_ 187 DrvIMS_MemoryP1Req_Copy_0 0 "None" 1 "P1" 2 "Not Used" 3 "Error Indicator" ;
VAL_ 187 DrvIMS_MemoryP2Req_Copy_0 0 "None" 1 "P2" 2 "Not Used" 3 "Error Indicator" ;
VAL_ 187 DrvIMS_MemoryP3Req_Copy_0 0 "None" 1 "P3" 2 "Not Used" 3 "Error Indicator" ;
VAL_ 187 DrvIMS_PlyBckP1Req_Copy_0 0 "None" 1 "P1" 2 "Not Used" 3 "Error Indicator" ;
VAL_ 187 DrvIMS_PlyBckP2Req_Copy_0 0 "None" 1 "P2" 2 "Not Used" 3 "Error Indicator" ;
VAL_ 187 DrvIMS_PlyBckP3Req_Copy_0 0 "None" 1 "P3" 2 "Not Used" 3 "Error Indicator" ;
VAL_ 187 DrvIMS_PlyBckStpReq_Copy_0 0 "Off" 1 "Stop" 2 "Not Used" 3 "Error Indicator" ;
VAL_ 187 AVN_SeatPosMemory_Cmd_Copy_0 0 "Default" 1 "memory 1" 2 "memory 2" 3 "memory 3" 4 "Not Used" 5 "Not Used" 6 "Not Used" 7 "Error Indicator" ;
VAL_ 187 AVN_SeatPosPlyBck_Cmd_Copy_0 0 "Default" 1 "memory 1" 2 "memory 2" 3 "memory 3" 4 "Not Used" 5 "Not Used" 6 "Stop" 7 "Error Indicator" ;
VAL_ 187 SmrtIMS_EnterSwSta_Copy_0 0 "off" 1 "on" 2 "reserved" 3 "invalid" ;
VAL_ 187 SmrtIMS_PlyBckReq_Copy_0 0 "None" 1 "0x1~0x97E:Smart IMS DB Number(1~2430)" 2430 "0x1~0x97E:Smart IMS DB Number(1~2430)" 2431 "0x97F~0xFFE:RESERVED" 4094 "0x97F~0xFFE:RESERVED" 4095 "Invalid" ;
VAL_ 187 SmrtIMS_PlyBckStpReq_Copy_0 0 "OFF" 1 "On" 2 "Not Used" 3 "Error Indicator" ;
VAL_ 187 Drv_AutoRlxWrngDis_Copy_0 0 "Off" 1 "Auto Relax Enable" 2 "Mode-Fail (Vehicle Speed Warning)" 3 "Mode-Fail (Not P Warning)" 4 "Mode-Fail (2nd Seat Belted)" 5 "Mode-Fail (Not Initialized)" 6 "Mode-Fail (2nd Seat Position Warning)" 7 "Invalid" ;
VAL_ 2214592738 L_UWB_FRNK_FD_Crc3Val 0 "0x0x0~0xFFFF:CRCValue" 65535 "0x0x0~0xFFFF:CRCValue" ;
VAL_ 2214592738 L_UWB_FRNK_FD_AlvCnt3Val 0 "0x0x0~0xFF:AlvCntValue" 255 "0x0x0~0xFF:AlvCntValue" ;
VAL_ 2214592737 L_UWB_FRNK_FD_Crc2Val 0 "0x0x0~0xFFFF:CRCValue" 65535 "0x0x0~0xFFFF:CRCValue" ;
VAL_ 2214592737 L_UWB_FRNK_FD_AlvCnt2Val 0 "0x0x0~0xFF:AlvCntValue" 255 "0x0x0~0xFF:AlvCntValue" ;
VAL_ 2214592736 L_UWB_FRNK_FD_Crc1Val 0 "0x0x0~0xFFFF:CRCValue" 65535 "0x0x0~0xFFFF:CRCValue" ;
VAL_ 2214592736 L_UWB_FRNK_FD_AlvCnt1Val 0 "0x0x0~0xFF:AlvCntValue" 255 "0x0x0~0xFF:AlvCntValue" ;
VAL_ 2214592736 UWB_FRNK_UWB_Decrypt_FB 0 "Default" 1 "Positive" 2 "Negative" 3 "RESERVED" 4 "RESERVED" 5 "RESERVED" 6 "RESERVED" 7 "RESERVED" 8 "RESERVED" 9 "RESERVED" 10 "RESERVED" 11 "RESERVED" 12 "RESERVED" 13 "RESERVED" 14 "RESERVED" 15 "RESERVED" ;
VAL_ 2214592736 UWB_FRNK_MST_Decrypt_FB 0 "Default" 1 "Positive" 2 "Negative" 3 "RESERVED" 4 "RESERVED" 5 "RESERVED" 6 "RESERVED" 7 "RESERVED" 8 "RESERVED" 9 "RESERVED" 10 "RESERVED" 11 "RESERVED" 12 "RESERVED" 13 "RESERVED" 14 "RESERVED" 15 "RESERVED" ;
VAL_ 2214592736 UWB_FRNK_OTA_Rsp 0 "Default" 1 "Request_Success" 2 "Request_Fail" 3 "Erase_Success" 4 "Erase_Fail" 5 "RESERVED" 6 "RESERVED" 7 "Verify_Success" 8 "Verify_Fail" 9 "RESERVED" 10 "RESERVED" 11 "Pause_Response" 12 "RESERVED" 13 "RESERVED" 14 "RESERVED" 15 "RESERVED" ;
VAL_ 2214592736 UWB_FRNK_UWB_IC_Status 0 "Status_OK" 1 "Status_Rejected" 2 "Status_Failed" 3 "Status_Syntax_Error" 4 "Status_Invalid_Param" 5 "Status_Invalid_Range" 6 "Status_Invalid_Message" 7 "Status_Unknow_GID" 8 "Status_Unknow_OID" 9 "Status_Read_Only" 10 "Status_Com_Retry" 11 "RESERVED" 12 "RESERVED" 13 "RESERVED" 14 "RESERVED" 15 "RESERVED" 17 "Session_Not_Exist" 18 "Session_Duplicate" 19 "Session_Active" 20 "Session_Max" 21 "Session_Not_Config" 22 "Session_Ongonig" 23 "RESERVED" 24 "RESERVED" 25 "RESERVED" 26 "Error_Slot_Len" 27 "Error_Slot_Per_RR" 28 "Error_STS_IDX" 29 "RESERVED" 30 "RESERVED" 31 "RESERVED" 32 "RESERVED" 33 "Init_Rejected" 34 "Init_Failed" 35 "Start_Rejected" 36 "Start_Failed" 37 "0x25~0xFF:RESERVED" 255 "0x25~0xFF:RESERVED" ;
VAL_ 745 PDC_FD_Crc15Val 0 "0x0x0~0xFFFF:CRCValue" 65535 "0x0x0~0xFFFF:CRCValue" ;
VAL_ 745 PDC_CurrAtReset_Copy_0 0 "0x0x0~0xFFE:-40,940mA ~ 0mA" 4094 "0x0x0~0xFFE:-40,940mA ~ 0mA" 4095 "Error" ;
VAL_ 745 PDC_AvgCurrAtReset_Copy_0 0 "0x0x0~0xFFE:-40,940mA ~ 0mA" 4094 "0x0x0~0xFFE:-40,940mA ~ 0mA" 4095 "Error" ;
VAL_ 745 PDC_ResetReason_Copy_0 0 "No Reset" 1 "Reset By Non-Sleep" 2 "Reset By Current" 3 "RESERVED" 4 "RESERVED" 5 "RESERVED" 6 "RESERVED" 7 "RESERVED" ;
VAL_ 745 PDC_CumulativeCountOf12VReq_Copy 0 "0x0x0~0x3FF:0~1023" 1023 "0x0x0~0x3FF:0~1023" ;
VAL_ 745 PDC_CumulativeCountOfCCUReq_Copy 0 "0x0x0~0x3FF:0~1023" 1023 "0x0x0~0x3FF:0~1023" ;
VAL_ 745 PDC_FD_AlvCnt15Val 0 "0x0x0~0xFF:AlvCntValue" 255 "0x0x0~0xFF:AlvCntValue" ;
VAL_ 745 PDC_LDConReq_Copy_0 0 "Off (Default)" 1 "On" 2 "RESERVED" 3 "RESERVED" ;
VAL_ 745 PDC_LDConReq_By_LVBat_Copy_0 0 "Off (Default)" 1 "On" 2 "RESERVED" 3 "RESERVED" ;
VAL_ 745 PDC_LDConReq_By_OTA_Copy_0 0 "Off (Default)" 1 "On" 2 "RESERVED" 3 "RESERVED" ;
VAL_ 745 PDC_LDConReq_By_Load_Copy_0 0 "Off (Default)" 1 "On" 2 "RESERVED" 3 "RESERVED" ;
VAL_ 745 PDC_LDConReq_By_ActiveOn_Copy_0 0 "Off (Default)" 1 "On" 2 "RESERVED" 3 "RESERVED" ;
VAL_ 745 PDC_ResetPreWrngForCCU_Copy_0 0 "No Warning" 1 "Warning" 2 "RESERVED" 3 "Invalid" ;
VAL_ 745 PDC_ResetPreWrngForOthers_Copy_0 0 "No Warning" 1 "Warning" 2 "RESERVED" 3 "Invalid" ;
VAL_ 745 PDC_ResetReqForCCU_Copy_0 0 "No Requeset" 1 "Reset Requeset" 2 "RESERVED" 3 "Invalid" ;
VAL_ 745 PDC_ResetReqForOthers_Copy_0 0 "No Requeset" 1 "Reset Requeset" 2 "RESERVED" 3 "Invalid" ;
VAL_ 745 PDC_ResetFuncOpt_Copy_0 0 "Not Applied" 1 "Applied" 2 "RESERVED" 3 "Invalid" ;
VAL_ 745 PDC_12VRlyCtrl_Copy_0 0 "No Request" 1 "Relay On request" 2 "Relay Off request" 3 "Invalid" ;
VAL_ 745 PDC_CurrentValueForReset_Copy_0 0 "No Setting" 1 "0x1~0xFE:50mA ~ 12700mA" 254 "0x1~0xFE:50mA ~ 12700mA" 255 "Invalid" ;
VAL_ 745 PDC_TimeValueForReset_Copy_0 0 "No Setting" 1 "0x1~0xFE:0.5h ~ 127h" 254 "0x1~0xFE:0.5h ~ 127h" 255 "Invalid" ;
VAL_ 745 PDC_12VRlyOffHoldingTime_Copy_0 0 "No Setting" 1 "0.5s ~ 15s" 2 "0.5s ~ 15s" 3 "0.5s ~ 15s" 4 "0.5s ~ 15s" 5 "0.5s ~ 15s" 6 "0.5s ~ 15s" 7 "0.5s ~ 15s" 8 "0.5s ~ 15s" 9 "0.5s ~ 15s" 10 "0.5s ~ 15s" 11 "0.5s ~ 15s" 12 "0.5s ~ 15s" 13 "0.5s ~ 15s" 14 "0.5s ~ 15s" 15 "0.5s ~ 15s" 16 "0.5s ~ 15s" 17 "0.5s ~ 15s" 18 "0.5s ~ 15s" 19 "0.5s ~ 15s" 20 "0.5s ~ 15s" 21 "0.5s ~ 15s" 22 "0.5s ~ 15s" 23 "0.5s ~ 15s" 24 "0.5s ~ 15s" 25 "0.5s ~ 15s" 26 "0.5s ~ 15s" 27 "0.5s ~ 15s" 28 "0.5s ~ 15s" 29 "0.5s ~ 15s" 30 "0.5s ~ 15s" 31 "Invalid" ;
VAL_ 745 PDC_ResetCountSetting_Copy_0 0 "No Setting" 1 "1~3" 2 "1~3" 3 "1~3" ;
VAL_ 745 PDC_ResetCount_Copy_0 0 "No Setting" 1 "1~3" 2 "1~3" 3 "1~3" ;
VAL_ 745 PDC_ResetCumulativeCount_Copy_0 0 "0x0x0~0x3FF:0~1023" 1023 "0x0x0~0x3FF:0~1023" ;
VAL_ 745 PDC_ResetOpsta_Copy_0 0 "Normal" 1 "Reset Complete" 2 "Reset Fail" 3 "RESERVED" ;
VAL_ 745 PDC_ReadyTimeValueForReset_Copy_ 0 "No Setting" 1 "0x1~0xFE:10min~254min/0XFF: Invalid" 254 "0x1~0xFE:10min~254min/0XFF: Invalid" ;
